VERSION "HINBNNNYYNNNYYNNNNNNNNNNNNYNNNYYYNNYNNNNNN/4//%%/4/'%**4NNN///"

NS_ :

BS_:

BU_: NMTMaster I_O_Device_3 I_O_Device_2 I_O_Device_1 NMT_Master

BO_ 127 RED_IndicateActiveCANLine: 0 Vector__XXX

BO_ 118 FM_ForceReset: 0 Vector__XXX

BO_ 117 FM_ReqMasterCapable: 0 Vector__XXX

BO_ 116 FM_RspMasterCapable: 0 Vector__XXX

BO_ 115 FM_ReqPrioLevel: 0 Vector__XXX

BO_ 114 FM_TriggerTimeSlot: 0 Vector__XXX

BO_ 113 FM_MasterPrioLevel: 2 Vector__XXX
 SG_ FM_NodeID : 8|8@1+ (1,0) [0|0] "" Vector__XXX
 SG_ FM_PrioLevel : 0|8@1+ (1,0) [0|0] "" Vector__XXX

BO_ 1919 HBGuard_127: 1 Vector__XXX
 SG_ Toggle : 7|1@1+ (1,0) [0|0] "" Vector__XXX
 SG_ State : 0|7@1+ (1,0) [0|0] "" Vector__XXX

BO_ 1918 HBGuard_126: 1 Vector__XXX
 SG_ Toggle : 7|1@1+ (1,0) [0|0] "" Vector__XXX
 SG_ State : 0|7@1+ (1,0) [0|0] "" Vector__XXX

BO_ 1917 HBGuard_125: 1 Vector__XXX
 SG_ Toggle : 7|1@1+ (1,0) [0|0] "" Vector__XXX
 SG_ State : 0|7@1+ (1,0) [0|0] "" Vector__XXX

BO_ 1916 HBGuard_124: 1 Vector__XXX
 SG_ Toggle : 7|1@1+ (1,0) [0|0] "" Vector__XXX
 SG_ State : 0|7@1+ (1,0) [0|0] "" Vector__XXX

BO_ 1915 HBGuard_123: 1 Vector__XXX
 SG_ Toggle : 7|1@1+ (1,0) [0|0] "" Vector__XXX
 SG_ State : 0|7@1+ (1,0) [0|0] "" Vector__XXX

BO_ 1914 HBGuard_122: 1 Vector__XXX
 SG_ Toggle : 7|1@1+ (1,0) [0|0] "" Vector__XXX
 SG_ State : 0|7@1+ (1,0) [0|0] "" Vector__XXX

BO_ 1913 HBGuard_121: 1 Vector__XXX
 SG_ Toggle : 7|1@1+ (1,0) [0|0] "" Vector__XXX
 SG_ State : 0|7@1+ (1,0) [0|0] "" Vector__XXX

BO_ 1912 HBGuard_120: 1 Vector__XXX
 SG_ Toggle : 7|1@1+ (1,0) [0|0] "" Vector__XXX
 SG_ State : 0|7@1+ (1,0) [0|0] "" Vector__XXX

BO_ 1911 HBGuard_119: 1 Vector__XXX
 SG_ Toggle : 7|1@1+ (1,0) [0|0] "" Vector__XXX
 SG_ State : 0|7@1+ (1,0) [0|0] "" Vector__XXX

BO_ 1910 HBGuard_118: 1 Vector__XXX
 SG_ Toggle : 7|1@1+ (1,0) [0|0] "" Vector__XXX
 SG_ State : 0|7@1+ (1,0) [0|0] "" Vector__XXX

BO_ 1909 HBGuard_117: 1 Vector__XXX
 SG_ Toggle : 7|1@1+ (1,0) [0|0] "" Vector__XXX
 SG_ State : 0|7@1+ (1,0) [0|0] "" Vector__XXX

BO_ 1908 HBGuard_116: 1 Vector__XXX
 SG_ Toggle : 7|1@1+ (1,0) [0|0] "" Vector__XXX
 SG_ State : 0|7@1+ (1,0) [0|0] "" Vector__XXX

BO_ 1907 HBGuard_115: 1 Vector__XXX
 SG_ Toggle : 7|1@1+ (1,0) [0|0] "" Vector__XXX
 SG_ State : 0|7@1+ (1,0) [0|0] "" Vector__XXX

BO_ 1906 HBGuard_114: 1 Vector__XXX
 SG_ Toggle : 7|1@1+ (1,0) [0|0] "" Vector__XXX
 SG_ State : 0|7@1+ (1,0) [0|0] "" Vector__XXX

BO_ 1905 HBGuard_113: 1 Vector__XXX
 SG_ Toggle : 7|1@1+ (1,0) [0|0] "" Vector__XXX
 SG_ State : 0|7@1+ (1,0) [0|0] "" Vector__XXX

BO_ 1904 HBGuard_112: 1 Vector__XXX
 SG_ Toggle : 7|1@1+ (1,0) [0|0] "" Vector__XXX
 SG_ State : 0|7@1+ (1,0) [0|0] "" Vector__XXX

BO_ 1903 HBGuard_111: 1 Vector__XXX
 SG_ Toggle : 7|1@1+ (1,0) [0|0] "" Vector__XXX
 SG_ State : 0|7@1+ (1,0) [0|0] "" Vector__XXX

BO_ 1902 HBGuard_110: 1 Vector__XXX
 SG_ Toggle : 7|1@1+ (1,0) [0|0] "" Vector__XXX
 SG_ State : 0|7@1+ (1,0) [0|0] "" Vector__XXX

BO_ 1901 HBGuard_109: 1 Vector__XXX
 SG_ Toggle : 7|1@1+ (1,0) [0|0] "" Vector__XXX
 SG_ State : 0|7@1+ (1,0) [0|0] "" Vector__XXX

BO_ 1900 HBGuard_108: 1 Vector__XXX
 SG_ Toggle : 7|1@1+ (1,0) [0|0] "" Vector__XXX
 SG_ State : 0|7@1+ (1,0) [0|0] "" Vector__XXX

BO_ 1899 HBGuard_107: 1 Vector__XXX
 SG_ Toggle : 7|1@1+ (1,0) [0|0] "" Vector__XXX
 SG_ State : 0|7@1+ (1,0) [0|0] "" Vector__XXX

BO_ 1898 HBGuard_106: 1 Vector__XXX
 SG_ Toggle : 7|1@1+ (1,0) [0|0] "" Vector__XXX
 SG_ State : 0|7@1+ (1,0) [0|0] "" Vector__XXX

BO_ 1897 HBGuard_105: 1 Vector__XXX
 SG_ Toggle : 7|1@1+ (1,0) [0|0] "" Vector__XXX
 SG_ State : 0|7@1+ (1,0) [0|0] "" Vector__XXX

BO_ 1896 HBGuard_104: 1 Vector__XXX
 SG_ Toggle : 7|1@1+ (1,0) [0|0] "" Vector__XXX
 SG_ State : 0|7@1+ (1,0) [0|0] "" Vector__XXX

BO_ 1895 HBGuard_103: 1 Vector__XXX
 SG_ Toggle : 7|1@1+ (1,0) [0|0] "" Vector__XXX
 SG_ State : 0|7@1+ (1,0) [0|0] "" Vector__XXX

BO_ 1894 HBGuard_102: 1 Vector__XXX
 SG_ Toggle : 7|1@1+ (1,0) [0|0] "" Vector__XXX
 SG_ State : 0|7@1+ (1,0) [0|0] "" Vector__XXX

BO_ 1893 HBGuard_101: 1 Vector__XXX
 SG_ Toggle : 7|1@1+ (1,0) [0|0] "" Vector__XXX
 SG_ State : 0|7@1+ (1,0) [0|0] "" Vector__XXX

BO_ 1892 HBGuard_100: 1 Vector__XXX
 SG_ Toggle : 7|1@1+ (1,0) [0|0] "" Vector__XXX
 SG_ State : 0|7@1+ (1,0) [0|0] "" Vector__XXX

BO_ 1891 HBGuard_099: 1 Vector__XXX
 SG_ Toggle : 7|1@1+ (1,0) [0|0] "" Vector__XXX
 SG_ State : 0|7@1+ (1,0) [0|0] "" Vector__XXX

BO_ 1890 HBGuard_098: 1 Vector__XXX
 SG_ Toggle : 7|1@1+ (1,0) [0|0] "" Vector__XXX
 SG_ State : 0|7@1+ (1,0) [0|0] "" Vector__XXX

BO_ 1889 HBGuard_097: 1 Vector__XXX
 SG_ Toggle : 7|1@1+ (1,0) [0|0] "" Vector__XXX
 SG_ State : 0|7@1+ (1,0) [0|0] "" Vector__XXX

BO_ 1888 HBGuard_096: 1 Vector__XXX
 SG_ Toggle : 7|1@1+ (1,0) [0|0] "" Vector__XXX
 SG_ State : 0|7@1+ (1,0) [0|0] "" Vector__XXX

BO_ 1887 HBGuard_095: 1 Vector__XXX
 SG_ Toggle : 7|1@1+ (1,0) [0|0] "" Vector__XXX
 SG_ State : 0|7@1+ (1,0) [0|0] "" Vector__XXX

BO_ 1886 HBGuard_094: 1 Vector__XXX
 SG_ Toggle : 7|1@1+ (1,0) [0|0] "" Vector__XXX
 SG_ State : 0|7@1+ (1,0) [0|0] "" Vector__XXX

BO_ 1885 HBGuard_093: 1 Vector__XXX
 SG_ Toggle : 7|1@1+ (1,0) [0|0] "" Vector__XXX
 SG_ State : 0|7@1+ (1,0) [0|0] "" Vector__XXX

BO_ 1884 HBGuard_092: 1 Vector__XXX
 SG_ Toggle : 7|1@1+ (1,0) [0|0] "" Vector__XXX
 SG_ State : 0|7@1+ (1,0) [0|0] "" Vector__XXX

BO_ 1883 HBGuard_091: 1 Vector__XXX
 SG_ Toggle : 7|1@1+ (1,0) [0|0] "" Vector__XXX
 SG_ State : 0|7@1+ (1,0) [0|0] "" Vector__XXX

BO_ 1882 HBGuard_090: 1 Vector__XXX
 SG_ Toggle : 7|1@1+ (1,0) [0|0] "" Vector__XXX
 SG_ State : 0|7@1+ (1,0) [0|0] "" Vector__XXX

BO_ 1881 HBGuard_089: 1 Vector__XXX
 SG_ Toggle : 7|1@1+ (1,0) [0|0] "" Vector__XXX
 SG_ State : 0|7@1+ (1,0) [0|0] "" Vector__XXX

BO_ 1880 HBGuard_088: 1 Vector__XXX
 SG_ Toggle : 7|1@1+ (1,0) [0|0] "" Vector__XXX
 SG_ State : 0|7@1+ (1,0) [0|0] "" Vector__XXX

BO_ 1879 HBGuard_087: 1 Vector__XXX
 SG_ Toggle : 7|1@1+ (1,0) [0|0] "" Vector__XXX
 SG_ State : 0|7@1+ (1,0) [0|0] "" Vector__XXX

BO_ 1878 HBGuard_086: 1 Vector__XXX
 SG_ Toggle : 7|1@1+ (1,0) [0|0] "" Vector__XXX
 SG_ State : 0|7@1+ (1,0) [0|0] "" Vector__XXX

BO_ 1877 HBGuard_085: 1 Vector__XXX
 SG_ Toggle : 7|1@1+ (1,0) [0|0] "" Vector__XXX
 SG_ State : 0|7@1+ (1,0) [0|0] "" Vector__XXX

BO_ 1876 HBGuard_084: 1 Vector__XXX
 SG_ Toggle : 7|1@1+ (1,0) [0|0] "" Vector__XXX
 SG_ State : 0|7@1+ (1,0) [0|0] "" Vector__XXX

BO_ 1875 HBGuard_083: 1 Vector__XXX
 SG_ Toggle : 7|1@1+ (1,0) [0|0] "" Vector__XXX
 SG_ State : 0|7@1+ (1,0) [0|0] "" Vector__XXX

BO_ 1874 HBGuard_082: 1 Vector__XXX
 SG_ Toggle : 7|1@1+ (1,0) [0|0] "" Vector__XXX
 SG_ State : 0|7@1+ (1,0) [0|0] "" Vector__XXX

BO_ 1873 HBGuard_081: 1 Vector__XXX
 SG_ Toggle : 7|1@1+ (1,0) [0|0] "" Vector__XXX
 SG_ State : 0|7@1+ (1,0) [0|0] "" Vector__XXX

BO_ 1872 HBGuard_080: 1 Vector__XXX
 SG_ Toggle : 7|1@1+ (1,0) [0|0] "" Vector__XXX
 SG_ State : 0|7@1+ (1,0) [0|0] "" Vector__XXX

BO_ 1871 HBGuard_079: 1 Vector__XXX
 SG_ Toggle : 7|1@1+ (1,0) [0|0] "" Vector__XXX
 SG_ State : 0|7@1+ (1,0) [0|0] "" Vector__XXX

BO_ 1870 HBGuard_078: 1 Vector__XXX
 SG_ Toggle : 7|1@1+ (1,0) [0|0] "" Vector__XXX
 SG_ State : 0|7@1+ (1,0) [0|0] "" Vector__XXX

BO_ 1869 HBGuard_077: 1 Vector__XXX
 SG_ Toggle : 7|1@1+ (1,0) [0|0] "" Vector__XXX
 SG_ State : 0|7@1+ (1,0) [0|0] "" Vector__XXX

BO_ 1868 HBGuard_076: 1 Vector__XXX
 SG_ Toggle : 7|1@1+ (1,0) [0|0] "" Vector__XXX
 SG_ State : 0|7@1+ (1,0) [0|0] "" Vector__XXX

BO_ 1867 HBGuard_075: 1 Vector__XXX
 SG_ Toggle : 7|1@1+ (1,0) [0|0] "" Vector__XXX
 SG_ State : 0|7@1+ (1,0) [0|0] "" Vector__XXX

BO_ 1866 HBGuard_074: 1 Vector__XXX
 SG_ Toggle : 7|1@1+ (1,0) [0|0] "" Vector__XXX
 SG_ State : 0|7@1+ (1,0) [0|0] "" Vector__XXX

BO_ 1865 HBGuard_073: 1 Vector__XXX
 SG_ Toggle : 7|1@1+ (1,0) [0|0] "" Vector__XXX
 SG_ State : 0|7@1+ (1,0) [0|0] "" Vector__XXX

BO_ 1864 HBGuard_072: 1 Vector__XXX
 SG_ Toggle : 7|1@1+ (1,0) [0|0] "" Vector__XXX
 SG_ State : 0|7@1+ (1,0) [0|0] "" Vector__XXX

BO_ 1863 HBGuard_071: 1 Vector__XXX
 SG_ Toggle : 7|1@1+ (1,0) [0|0] "" Vector__XXX
 SG_ State : 0|7@1+ (1,0) [0|0] "" Vector__XXX

BO_ 1862 HBGuard_070: 1 Vector__XXX
 SG_ Toggle : 7|1@1+ (1,0) [0|0] "" Vector__XXX
 SG_ State : 0|7@1+ (1,0) [0|0] "" Vector__XXX

BO_ 1861 HBGuard_069: 1 Vector__XXX
 SG_ Toggle : 7|1@1+ (1,0) [0|0] "" Vector__XXX
 SG_ State : 0|7@1+ (1,0) [0|0] "" Vector__XXX

BO_ 1860 HBGuard_068: 1 Vector__XXX
 SG_ Toggle : 7|1@1+ (1,0) [0|0] "" Vector__XXX
 SG_ State : 0|7@1+ (1,0) [0|0] "" Vector__XXX

BO_ 1859 HBGuard_067: 1 Vector__XXX
 SG_ Toggle : 7|1@1+ (1,0) [0|0] "" Vector__XXX
 SG_ State : 0|7@1+ (1,0) [0|0] "" Vector__XXX

BO_ 1858 HBGuard_066: 1 Vector__XXX
 SG_ Toggle : 7|1@1+ (1,0) [0|0] "" Vector__XXX
 SG_ State : 0|7@1+ (1,0) [0|0] "" Vector__XXX

BO_ 1857 HBGuard_065: 1 Vector__XXX
 SG_ Toggle : 7|1@1+ (1,0) [0|0] "" Vector__XXX
 SG_ State : 0|7@1+ (1,0) [0|0] "" Vector__XXX

BO_ 1856 HBGuard_064: 1 Vector__XXX
 SG_ Toggle : 7|1@1+ (1,0) [0|0] "" Vector__XXX
 SG_ State : 0|7@1+ (1,0) [0|0] "" Vector__XXX

BO_ 1855 HBGuard_063: 1 Vector__XXX
 SG_ Toggle : 7|1@1+ (1,0) [0|0] "" Vector__XXX
 SG_ State : 0|7@1+ (1,0) [0|0] "" Vector__XXX

BO_ 1854 HBGuard_062: 1 Vector__XXX
 SG_ Toggle : 7|1@1+ (1,0) [0|0] "" Vector__XXX
 SG_ State : 0|7@1+ (1,0) [0|0] "" Vector__XXX

BO_ 1853 HBGuard_061: 1 Vector__XXX
 SG_ Toggle : 7|1@1+ (1,0) [0|0] "" Vector__XXX
 SG_ State : 0|7@1+ (1,0) [0|0] "" Vector__XXX

BO_ 1852 HBGuard_060: 1 Vector__XXX
 SG_ Toggle : 7|1@1+ (1,0) [0|0] "" Vector__XXX
 SG_ State : 0|7@1+ (1,0) [0|0] "" Vector__XXX

BO_ 1851 HBGuard_059: 1 Vector__XXX
 SG_ Toggle : 7|1@1+ (1,0) [0|0] "" Vector__XXX
 SG_ State : 0|7@1+ (1,0) [0|0] "" Vector__XXX

BO_ 1850 HBGuard_058: 1 Vector__XXX
 SG_ Toggle : 7|1@1+ (1,0) [0|0] "" Vector__XXX
 SG_ State : 0|7@1+ (1,0) [0|0] "" Vector__XXX

BO_ 1849 HBGuard_057: 1 Vector__XXX
 SG_ Toggle : 7|1@1+ (1,0) [0|0] "" Vector__XXX
 SG_ State : 0|7@1+ (1,0) [0|0] "" Vector__XXX

BO_ 1848 HBGuard_056: 1 Vector__XXX
 SG_ Toggle : 7|1@1+ (1,0) [0|0] "" Vector__XXX
 SG_ State : 0|7@1+ (1,0) [0|0] "" Vector__XXX

BO_ 1847 HBGuard_055: 1 Vector__XXX
 SG_ Toggle : 7|1@1+ (1,0) [0|0] "" Vector__XXX
 SG_ State : 0|7@1+ (1,0) [0|0] "" Vector__XXX

BO_ 1846 HBGuard_054: 1 Vector__XXX
 SG_ Toggle : 7|1@1+ (1,0) [0|0] "" Vector__XXX
 SG_ State : 0|7@1+ (1,0) [0|0] "" Vector__XXX

BO_ 1845 HBGuard_053: 1 Vector__XXX
 SG_ Toggle : 7|1@1+ (1,0) [0|0] "" Vector__XXX
 SG_ State : 0|7@1+ (1,0) [0|0] "" Vector__XXX

BO_ 1844 HBGuard_052: 1 Vector__XXX
 SG_ Toggle : 7|1@1+ (1,0) [0|0] "" Vector__XXX
 SG_ State : 0|7@1+ (1,0) [0|0] "" Vector__XXX

BO_ 1843 HBGuard_051: 1 Vector__XXX
 SG_ Toggle : 7|1@1+ (1,0) [0|0] "" Vector__XXX
 SG_ State : 0|7@1+ (1,0) [0|0] "" Vector__XXX

BO_ 1842 HBGuard_050: 1 Vector__XXX
 SG_ Toggle : 7|1@1+ (1,0) [0|0] "" Vector__XXX
 SG_ State : 0|7@1+ (1,0) [0|0] "" Vector__XXX

BO_ 1841 HBGuard_049: 1 Vector__XXX
 SG_ Toggle : 7|1@1+ (1,0) [0|0] "" Vector__XXX
 SG_ State : 0|7@1+ (1,0) [0|0] "" Vector__XXX

BO_ 1840 HBGuard_048: 1 Vector__XXX
 SG_ Toggle : 7|1@1+ (1,0) [0|0] "" Vector__XXX
 SG_ State : 0|7@1+ (1,0) [0|0] "" Vector__XXX

BO_ 1839 HBGuard_047: 1 Vector__XXX
 SG_ Toggle : 7|1@1+ (1,0) [0|0] "" Vector__XXX
 SG_ State : 0|7@1+ (1,0) [0|0] "" Vector__XXX

BO_ 1838 HBGuard_046: 1 Vector__XXX
 SG_ Toggle : 7|1@1+ (1,0) [0|0] "" Vector__XXX
 SG_ State : 0|7@1+ (1,0) [0|0] "" Vector__XXX

BO_ 1837 HBGuard_045: 1 Vector__XXX
 SG_ Toggle : 7|1@1+ (1,0) [0|0] "" Vector__XXX
 SG_ State : 0|7@1+ (1,0) [0|0] "" Vector__XXX

BO_ 1836 HBGuard_044: 1 Vector__XXX
 SG_ Toggle : 7|1@1+ (1,0) [0|0] "" Vector__XXX
 SG_ State : 0|7@1+ (1,0) [0|0] "" Vector__XXX

BO_ 1835 HBGuard_043: 1 Vector__XXX
 SG_ Toggle : 7|1@1+ (1,0) [0|0] "" Vector__XXX
 SG_ State : 0|7@1+ (1,0) [0|0] "" Vector__XXX

BO_ 1834 HBGuard_042: 1 Vector__XXX
 SG_ Toggle : 7|1@1+ (1,0) [0|0] "" Vector__XXX
 SG_ State : 0|7@1+ (1,0) [0|0] "" Vector__XXX

BO_ 1833 HBGuard_041: 1 Vector__XXX
 SG_ Toggle : 7|1@1+ (1,0) [0|0] "" Vector__XXX
 SG_ State : 0|7@1+ (1,0) [0|0] "" Vector__XXX

BO_ 1832 HBGuard_040: 1 Vector__XXX
 SG_ Toggle : 7|1@1+ (1,0) [0|0] "" Vector__XXX
 SG_ State : 0|7@1+ (1,0) [0|0] "" Vector__XXX

BO_ 1831 HBGuard_039: 1 Vector__XXX
 SG_ Toggle : 7|1@1+ (1,0) [0|0] "" Vector__XXX
 SG_ State : 0|7@1+ (1,0) [0|0] "" Vector__XXX

BO_ 1830 HBGuard_038: 1 Vector__XXX
 SG_ Toggle : 7|1@1+ (1,0) [0|0] "" Vector__XXX
 SG_ State : 0|7@1+ (1,0) [0|0] "" Vector__XXX

BO_ 1829 HBGuard_037: 1 Vector__XXX
 SG_ Toggle : 7|1@1+ (1,0) [0|0] "" Vector__XXX
 SG_ State : 0|7@1+ (1,0) [0|0] "" Vector__XXX

BO_ 1828 HBGuard_036: 1 Vector__XXX
 SG_ Toggle : 7|1@1+ (1,0) [0|0] "" Vector__XXX
 SG_ State : 0|7@1+ (1,0) [0|0] "" Vector__XXX

BO_ 1827 HBGuard_035: 1 Vector__XXX
 SG_ Toggle : 7|1@1+ (1,0) [0|0] "" Vector__XXX
 SG_ State : 0|7@1+ (1,0) [0|0] "" Vector__XXX

BO_ 1826 HBGuard_034: 1 Vector__XXX
 SG_ Toggle : 7|1@1+ (1,0) [0|0] "" Vector__XXX
 SG_ State : 0|7@1+ (1,0) [0|0] "" Vector__XXX

BO_ 1825 HBGuard_033: 1 Vector__XXX
 SG_ Toggle : 7|1@1+ (1,0) [0|0] "" Vector__XXX
 SG_ State : 0|7@1+ (1,0) [0|0] "" Vector__XXX

BO_ 1824 HBGuard_032: 1 Vector__XXX
 SG_ Toggle : 7|1@1+ (1,0) [0|0] "" Vector__XXX
 SG_ State : 0|7@1+ (1,0) [0|0] "" Vector__XXX

BO_ 1823 HBGuard_031: 1 Vector__XXX
 SG_ Toggle : 7|1@1+ (1,0) [0|0] "" Vector__XXX
 SG_ State : 0|7@1+ (1,0) [0|0] "" Vector__XXX

BO_ 1822 HBGuard_030: 1 Vector__XXX
 SG_ Toggle : 7|1@1+ (1,0) [0|0] "" Vector__XXX
 SG_ State : 0|7@1+ (1,0) [0|0] "" Vector__XXX

BO_ 1821 HBGuard_029: 1 Vector__XXX
 SG_ Toggle : 7|1@1+ (1,0) [0|0] "" Vector__XXX
 SG_ State : 0|7@1+ (1,0) [0|0] "" Vector__XXX

BO_ 1820 HBGuard_028: 1 Vector__XXX
 SG_ Toggle : 7|1@1+ (1,0) [0|0] "" Vector__XXX
 SG_ State : 0|7@1+ (1,0) [0|0] "" Vector__XXX

BO_ 1819 HBGuard_027: 1 Vector__XXX
 SG_ Toggle : 7|1@1+ (1,0) [0|0] "" Vector__XXX
 SG_ State : 0|7@1+ (1,0) [0|0] "" Vector__XXX

BO_ 1818 HBGuard_026: 1 Vector__XXX
 SG_ Toggle : 7|1@1+ (1,0) [0|0] "" Vector__XXX
 SG_ State : 0|7@1+ (1,0) [0|0] "" Vector__XXX

BO_ 1817 HBGuard_025: 1 Vector__XXX
 SG_ Toggle : 7|1@1+ (1,0) [0|0] "" Vector__XXX
 SG_ State : 0|7@1+ (1,0) [0|0] "" Vector__XXX

BO_ 1816 HBGuard_024: 1 Vector__XXX
 SG_ Toggle : 7|1@1+ (1,0) [0|0] "" Vector__XXX
 SG_ State : 0|7@1+ (1,0) [0|0] "" Vector__XXX

BO_ 1815 HBGuard_023: 1 Vector__XXX
 SG_ Toggle : 7|1@1+ (1,0) [0|0] "" Vector__XXX
 SG_ State : 0|7@1+ (1,0) [0|0] "" Vector__XXX

BO_ 1814 HBGuard_022: 1 Vector__XXX
 SG_ Toggle : 7|1@1+ (1,0) [0|0] "" Vector__XXX
 SG_ State : 0|7@1+ (1,0) [0|0] "" Vector__XXX

BO_ 1813 HBGuard_021: 1 Vector__XXX
 SG_ Toggle : 7|1@1+ (1,0) [0|0] "" Vector__XXX
 SG_ State : 0|7@1+ (1,0) [0|0] "" Vector__XXX

BO_ 1812 HBGuard_020: 1 Vector__XXX
 SG_ Toggle : 7|1@1+ (1,0) [0|0] "" Vector__XXX
 SG_ State : 0|7@1+ (1,0) [0|0] "" Vector__XXX

BO_ 1811 HBGuard_019: 1 Vector__XXX
 SG_ Toggle : 7|1@1+ (1,0) [0|0] "" Vector__XXX
 SG_ State : 0|7@1+ (1,0) [0|0] "" Vector__XXX

BO_ 1810 HBGuard_018: 1 Vector__XXX
 SG_ Toggle : 7|1@1+ (1,0) [0|0] "" Vector__XXX
 SG_ State : 0|7@1+ (1,0) [0|0] "" Vector__XXX

BO_ 1809 HBGuard_017: 1 Vector__XXX
 SG_ Toggle : 7|1@1+ (1,0) [0|0] "" Vector__XXX
 SG_ State : 0|7@1+ (1,0) [0|0] "" Vector__XXX

BO_ 1808 HBGuard_016: 1 Vector__XXX
 SG_ Toggle : 7|1@1+ (1,0) [0|0] "" Vector__XXX
 SG_ State : 0|7@1+ (1,0) [0|0] "" Vector__XXX

BO_ 1807 HBGuard_015: 1 Vector__XXX
 SG_ Toggle : 7|1@1+ (1,0) [0|0] "" Vector__XXX
 SG_ State : 0|7@1+ (1,0) [0|0] "" Vector__XXX

BO_ 1806 HBGuard_014: 1 Vector__XXX
 SG_ Toggle : 7|1@1+ (1,0) [0|0] "" Vector__XXX
 SG_ State : 0|7@1+ (1,0) [0|0] "" Vector__XXX

BO_ 1805 HBGuard_013: 1 I_O_Device_3
 SG_ Toggle : 7|1@1+ (1,0) [0|0] "" Vector__XXX
 SG_ State : 0|7@1+ (1,0) [0|0] "" Vector__XXX

BO_ 1804 HBGuard_012: 1 I_O_Device_2
 SG_ Toggle : 7|1@1+ (1,0) [0|0] "" Vector__XXX
 SG_ State : 0|7@1+ (1,0) [0|0] "" Vector__XXX

BO_ 1803 HBGuard_011: 1 I_O_Device_1
 SG_ Toggle : 7|1@1+ (1,0) [0|0] "" Vector__XXX
 SG_ State : 0|7@1+ (1,0) [0|0] "" Vector__XXX

BO_ 1802 HBGuard_010: 1 Vector__XXX
 SG_ Toggle : 7|1@1+ (1,0) [0|0] "" Vector__XXX
 SG_ State : 0|7@1+ (1,0) [0|0] "" Vector__XXX

BO_ 1801 HBGuard_009: 1 Vector__XXX
 SG_ Toggle : 7|1@1+ (1,0) [0|0] "" Vector__XXX
 SG_ State : 0|7@1+ (1,0) [0|0] "" Vector__XXX

BO_ 1800 HBGuard_008: 1 Vector__XXX
 SG_ Toggle : 7|1@1+ (1,0) [0|0] "" Vector__XXX
 SG_ State : 0|7@1+ (1,0) [0|0] "" Vector__XXX

BO_ 1799 HBGuard_007: 1 Vector__XXX
 SG_ Toggle : 7|1@1+ (1,0) [0|0] "" Vector__XXX
 SG_ State : 0|7@1+ (1,0) [0|0] "" Vector__XXX

BO_ 1798 HBGuard_006: 1 Vector__XXX
 SG_ Toggle : 7|1@1+ (1,0) [0|0] "" Vector__XXX
 SG_ State : 0|7@1+ (1,0) [0|0] "" Vector__XXX

BO_ 1797 HBGuard_005: 1 Vector__XXX
 SG_ Toggle : 7|1@1+ (1,0) [0|0] "" Vector__XXX
 SG_ State : 0|7@1+ (1,0) [0|0] "" Vector__XXX

BO_ 1796 HBGuard_004: 1 Vector__XXX
 SG_ Toggle : 7|1@1+ (1,0) [0|0] "" Vector__XXX
 SG_ State : 0|7@1+ (1,0) [0|0] "" Vector__XXX

BO_ 1795 HBGuard_003: 1 Vector__XXX
 SG_ Toggle : 7|1@1+ (1,0) [0|0] "" Vector__XXX
 SG_ State : 0|7@1+ (1,0) [0|0] "" Vector__XXX

BO_ 1794 HBGuard_002: 1 Vector__XXX
 SG_ Toggle : 7|1@1+ (1,0) [0|0] "" Vector__XXX
 SG_ State : 0|7@1+ (1,0) [0|0] "" Vector__XXX

BO_ 1793 HBGuard_001: 1 NMT_Master
 SG_ Toggle : 7|1@1+ (1,0) [0|0] "" Vector__XXX
 SG_ State : 0|7@1+ (1,0) [0|0] "" Vector__XXX

BO_ 1760 DynSDOReq: 0 Vector__XXX

BO_ 2021 LSS_M: 8 Vector__XXX
 SG_ LSS_IdentSerialHigh m75 : 8|32@1+ (1,0) [0|0] "" Vector__XXX
 SG_ LSS_IdentSerialLow m74 : 8|32@1+ (1,0) [0|0] "" Vector__XXX
 SG_ LSS_IdentRevisionHigh m73 : 8|32@1+ (1,0) [0|0] "" Vector__XXX
 SG_ LSS_IdentRevisionLow m72 : 8|32@1+ (1,0) [0|0] "" Vector__XXX
 SG_ LSS_IdentProductCode m71 : 8|32@1+ (1,0) [0|0] "" Vector__XXX
 SG_ LSS_IdentVendorId m70 : 8|32@1+ (1,0) [0|0] "" Vector__XXX
 SG_ LSS_TableIndex m19 : 16|8@1+ (1,0) [0|0] "" Vector__XXX
 SG_ LSS_TableSelector m19 : 8|8@1+ (1,0) [0|0] "" Vector__XXX
 SG_ LSS_SwitchSerial m67 : 8|32@1+ (1,0) [0|0] "" Vector__XXX
 SG_ LSS_SwitchRevision m66 : 8|32@1+ (1,0) [0|0] "" Vector__XXX
 SG_ LSS_SwitchProductCode m65 : 8|32@1+ (1,0) [0|0] "" Vector__XXX
 SG_ LSS_SwitchVendorId m64 : 8|32@1+ (1,0) [0|0] "" Vector__XXX
 SG_ LSS_Mode m4 : 8|8@1+ (1,0) [0|0] "" Vector__XXX
 SG_ LSS_M_CS M : 0|8@1+ (1,0) [0|0] "" Vector__XXX

BO_ 2020 LSS_S: 8 Vector__XXX
 SG_ LSS_NodeId m94 : 8|8@1+ (1,0) [0|0] "" Vector__XXX
 SG_ LSS_Serial m93 : 8|32@1+ (1,0) [0|0] "" Vector__XXX
 SG_ LSS_Revision m92 : 8|32@1+ (1,0) [0|0] "" Vector__XXX
 SG_ LSS_ProductId m91 : 8|32@1+ (1,0) [0|0] "" Vector__XXX
 SG_ LSS_VendorId m90 : 8|32@1+ (1,0) [0|0] "" Vector__XXX
 SG_ LSS_StoreCfg_SpecErr m23 : 16|8@1+ (1,0) [0|0] "" Vector__XXX
 SG_ LSS_StoreCfg_ErrCode m23 : 8|8@1+ (1,0) [0|0] "" Vector__XXX
 SG_ LSS_CfgBitTim_SpecErr m19 : 16|8@1+ (1,0) [0|0] "" Vector__XXX
 SG_ LSS_CfgBitTim_ErrCode m19 : 8|8@1+ (1,0) [0|0] "" Vector__XXX
 SG_ LSS_CfgNodeID_SpecErr m17 : 16|8@1+ (1,0) [0|0] "" Vector__XXX
 SG_ LSS_CfgNodeID_ErrCode m17 : 8|8@1+ (1,0) [0|0] "" Vector__XXX
 SG_ LSS_S_CS M : 0|8@1+ (1,0) [0|0] "" Vector__XXX

BO_ 1 GFC: 0 Vector__XXX

BO_ 1535 SSDO_127: 8 Vector__XXX

BO_ 1534 SSDO_126: 8 Vector__XXX

BO_ 1533 SSDO_125: 8 Vector__XXX

BO_ 1532 SSDO_124: 8 Vector__XXX

BO_ 1531 SSDO_123: 8 Vector__XXX

BO_ 1530 SSDO_122: 8 Vector__XXX

BO_ 1529 SSDO_121: 8 Vector__XXX

BO_ 1528 SSDO_120: 8 Vector__XXX

BO_ 1527 SSDO_119: 8 Vector__XXX

BO_ 1526 SSDO_118: 8 Vector__XXX

BO_ 1525 SSDO_117: 8 Vector__XXX

BO_ 1524 SSDO_116: 8 Vector__XXX

BO_ 1523 SSDO_115: 8 Vector__XXX

BO_ 1522 SSDO_114: 8 Vector__XXX

BO_ 1521 SSDO_113: 8 Vector__XXX

BO_ 1520 SSDO_112: 8 Vector__XXX

BO_ 1519 SSDO_111: 8 Vector__XXX

BO_ 1518 SSDO_110: 8 Vector__XXX

BO_ 1517 SSDO_109: 8 Vector__XXX

BO_ 1516 SSDO_108: 8 Vector__XXX

BO_ 1515 SSDO_107: 8 Vector__XXX

BO_ 1514 SSDO_106: 8 Vector__XXX

BO_ 1513 SSDO_105: 8 Vector__XXX

BO_ 1512 SSDO_104: 8 Vector__XXX

BO_ 1511 SSDO_103: 8 Vector__XXX

BO_ 1510 SSDO_102: 8 Vector__XXX

BO_ 1509 SSDO_101: 8 Vector__XXX

BO_ 1508 SSDO_100: 8 Vector__XXX

BO_ 1507 SSDO_099: 8 Vector__XXX

BO_ 1506 SSDO_098: 8 Vector__XXX

BO_ 1505 SSDO_097: 8 Vector__XXX

BO_ 1504 SSDO_096: 8 Vector__XXX

BO_ 1503 SSDO_095: 8 Vector__XXX

BO_ 1502 SSDO_094: 8 Vector__XXX

BO_ 1501 SSDO_093: 8 Vector__XXX

BO_ 1500 SSDO_092: 8 Vector__XXX

BO_ 1499 SSDO_091: 8 Vector__XXX

BO_ 1498 SSDO_090: 8 Vector__XXX

BO_ 1497 SSDO_089: 8 Vector__XXX

BO_ 1496 SSDO_088: 8 Vector__XXX

BO_ 1495 SSDO_087: 8 Vector__XXX

BO_ 1494 SSDO_086: 8 Vector__XXX

BO_ 1493 SSDO_085: 8 Vector__XXX

BO_ 1492 SSDO_084: 8 Vector__XXX

BO_ 1491 SSDO_083: 8 Vector__XXX

BO_ 1490 SSDO_082: 8 Vector__XXX

BO_ 1489 SSDO_081: 8 Vector__XXX

BO_ 1488 SSDO_080: 8 Vector__XXX

BO_ 1487 SSDO_079: 8 Vector__XXX

BO_ 1486 SSDO_078: 8 Vector__XXX

BO_ 1485 SSDO_077: 8 Vector__XXX

BO_ 1484 SSDO_076: 8 Vector__XXX

BO_ 1483 SSDO_075: 8 Vector__XXX

BO_ 1482 SSDO_074: 8 Vector__XXX

BO_ 1481 SSDO_073: 8 Vector__XXX

BO_ 1480 SSDO_072: 8 Vector__XXX

BO_ 1479 SSDO_071: 8 Vector__XXX

BO_ 1478 SSDO_070: 8 Vector__XXX

BO_ 1477 SSDO_069: 8 Vector__XXX

BO_ 1476 SSDO_068: 8 Vector__XXX

BO_ 1475 SSDO_067: 8 Vector__XXX

BO_ 1474 SSDO_066: 8 Vector__XXX

BO_ 1473 SSDO_065: 8 Vector__XXX

BO_ 1472 SSDO_064: 8 Vector__XXX

BO_ 1471 SSDO_063: 8 Vector__XXX

BO_ 1470 SSDO_062: 8 Vector__XXX

BO_ 1469 SSDO_061: 8 Vector__XXX

BO_ 1468 SSDO_060: 8 Vector__XXX

BO_ 1467 SSDO_059: 8 Vector__XXX

BO_ 1466 SSDO_058: 8 Vector__XXX

BO_ 1465 SSDO_057: 8 Vector__XXX

BO_ 1464 SSDO_056: 8 Vector__XXX

BO_ 1463 SSDO_055: 8 Vector__XXX

BO_ 1462 SSDO_054: 8 Vector__XXX

BO_ 1461 SSDO_053: 8 Vector__XXX

BO_ 1460 SSDO_052: 8 Vector__XXX

BO_ 1459 SSDO_051: 8 Vector__XXX

BO_ 1458 SSDO_050: 8 Vector__XXX

BO_ 1457 SSDO_049: 8 Vector__XXX

BO_ 1456 SSDO_048: 8 Vector__XXX

BO_ 1455 SSDO_047: 8 Vector__XXX

BO_ 1454 SSDO_046: 8 Vector__XXX

BO_ 1453 SSDO_045: 8 Vector__XXX

BO_ 1452 SSDO_044: 8 Vector__XXX

BO_ 1451 SSDO_043: 8 Vector__XXX

BO_ 1450 SSDO_042: 8 Vector__XXX

BO_ 1449 SSDO_041: 8 Vector__XXX

BO_ 1448 SSDO_040: 8 Vector__XXX

BO_ 1447 SSDO_039: 8 Vector__XXX

BO_ 1446 SSDO_038: 8 Vector__XXX

BO_ 1445 SSDO_037: 8 Vector__XXX

BO_ 1444 SSDO_036: 8 Vector__XXX

BO_ 1443 SSDO_035: 8 Vector__XXX

BO_ 1442 SSDO_034: 8 Vector__XXX

BO_ 1441 SSDO_033: 8 Vector__XXX

BO_ 1440 SSDO_032: 8 Vector__XXX

BO_ 1439 SSDO_031: 8 Vector__XXX

BO_ 1438 SSDO_030: 8 Vector__XXX

BO_ 1437 SSDO_029: 8 Vector__XXX

BO_ 1436 SSDO_028: 8 Vector__XXX

BO_ 1435 SSDO_027: 8 Vector__XXX

BO_ 1434 SSDO_026: 8 Vector__XXX

BO_ 1433 SSDO_025: 8 Vector__XXX

BO_ 1432 SSDO_024: 8 Vector__XXX

BO_ 1431 SSDO_023: 8 Vector__XXX

BO_ 1430 SSDO_022: 8 Vector__XXX

BO_ 1429 SSDO_021: 8 Vector__XXX

BO_ 1428 SSDO_020: 8 Vector__XXX

BO_ 1427 SSDO_019: 8 Vector__XXX

BO_ 1426 SSDO_018: 8 Vector__XXX

BO_ 1425 SSDO_017: 8 Vector__XXX

BO_ 1424 SSDO_016: 8 Vector__XXX

BO_ 1423 SSDO_015: 8 Vector__XXX

BO_ 1422 SSDO_014: 8 Vector__XXX

BO_ 1421 SSDO_013: 8 I_O_Device_3

BO_ 1420 SSDO_012: 8 I_O_Device_2

BO_ 1419 SSDO_011: 8 I_O_Device_1

BO_ 1418 SSDO_010: 8 Vector__XXX

BO_ 1417 SSDO_009: 8 Vector__XXX

BO_ 1416 SSDO_008: 8 Vector__XXX

BO_ 1415 SSDO_007: 8 Vector__XXX

BO_ 1414 SSDO_006: 8 Vector__XXX

BO_ 1413 SSDO_005: 8 Vector__XXX

BO_ 1412 SSDO_004: 8 Vector__XXX

BO_ 1411 SSDO_003: 8 Vector__XXX

BO_ 1410 SSDO_002: 8 Vector__XXX

BO_ 1409 SSDO_001: 8 NMT_Master

BO_ 1663 CSDO_127: 8 Vector__XXX

BO_ 1662 CSDO_126: 8 Vector__XXX

BO_ 1661 CSDO_125: 8 Vector__XXX

BO_ 1660 CSDO_124: 8 Vector__XXX

BO_ 1659 CSDO_123: 8 Vector__XXX

BO_ 1658 CSDO_122: 8 Vector__XXX

BO_ 1657 CSDO_121: 8 Vector__XXX

BO_ 1656 CSDO_120: 8 Vector__XXX

BO_ 1655 CSDO_119: 8 Vector__XXX

BO_ 1654 CSDO_118: 8 Vector__XXX

BO_ 1653 CSDO_117: 8 Vector__XXX

BO_ 1652 CSDO_116: 8 Vector__XXX

BO_ 1651 CSDO_115: 8 Vector__XXX

BO_ 1650 CSDO_114: 8 Vector__XXX

BO_ 1649 CSDO_113: 8 Vector__XXX

BO_ 1648 CSDO_112: 8 Vector__XXX

BO_ 1647 CSDO_111: 8 Vector__XXX

BO_ 1646 CSDO_110: 8 Vector__XXX

BO_ 1645 CSDO_109: 8 Vector__XXX

BO_ 1644 CSDO_108: 8 Vector__XXX

BO_ 1643 CSDO_107: 8 Vector__XXX

BO_ 1642 CSDO_106: 8 Vector__XXX

BO_ 1641 CSDO_105: 8 Vector__XXX

BO_ 1640 CSDO_104: 8 Vector__XXX

BO_ 1639 CSDO_103: 8 Vector__XXX

BO_ 1638 CSDO_102: 8 Vector__XXX

BO_ 1637 CSDO_101: 8 Vector__XXX

BO_ 1636 CSDO_100: 8 Vector__XXX

BO_ 1635 CSDO_099: 8 Vector__XXX

BO_ 1634 CSDO_098: 8 Vector__XXX

BO_ 1633 CSDO_097: 8 Vector__XXX

BO_ 1632 CSDO_096: 8 Vector__XXX

BO_ 1631 CSDO_095: 8 Vector__XXX

BO_ 1630 CSDO_094: 8 Vector__XXX

BO_ 1629 CSDO_093: 8 Vector__XXX

BO_ 1628 CSDO_092: 8 Vector__XXX

BO_ 1627 CSDO_091: 8 Vector__XXX

BO_ 1626 CSDO_090: 8 Vector__XXX

BO_ 1625 CSDO_089: 8 Vector__XXX

BO_ 1624 CSDO_088: 8 Vector__XXX

BO_ 1623 CSDO_087: 8 Vector__XXX

BO_ 1622 CSDO_086: 8 Vector__XXX

BO_ 1621 CSDO_085: 8 Vector__XXX

BO_ 1620 CSDO_084: 8 Vector__XXX

BO_ 1619 CSDO_083: 8 Vector__XXX

BO_ 1618 CSDO_082: 8 Vector__XXX

BO_ 1617 CSDO_081: 8 Vector__XXX

BO_ 1616 CSDO_080: 8 Vector__XXX

BO_ 1615 CSDO_079: 8 Vector__XXX

BO_ 1614 CSDO_078: 8 Vector__XXX

BO_ 1613 CSDO_077: 8 Vector__XXX

BO_ 1612 CSDO_076: 8 Vector__XXX

BO_ 1611 CSDO_075: 8 Vector__XXX

BO_ 1610 CSDO_074: 8 Vector__XXX

BO_ 1609 CSDO_073: 8 Vector__XXX

BO_ 1608 CSDO_072: 8 Vector__XXX

BO_ 1607 CSDO_071: 8 Vector__XXX

BO_ 1606 CSDO_070: 8 Vector__XXX

BO_ 1605 CSDO_069: 8 Vector__XXX

BO_ 1604 CSDO_068: 8 Vector__XXX

BO_ 1603 CSDO_067: 8 Vector__XXX

BO_ 1602 CSDO_066: 8 Vector__XXX

BO_ 1601 CSDO_065: 8 Vector__XXX

BO_ 1600 CSDO_064: 8 Vector__XXX

BO_ 1599 CSDO_063: 8 Vector__XXX

BO_ 1598 CSDO_062: 8 Vector__XXX

BO_ 1597 CSDO_061: 8 Vector__XXX

BO_ 1596 CSDO_060: 8 Vector__XXX

BO_ 1595 CSDO_059: 8 Vector__XXX

BO_ 1594 CSDO_058: 8 Vector__XXX

BO_ 1593 CSDO_057: 8 Vector__XXX

BO_ 1592 CSDO_056: 8 Vector__XXX

BO_ 1591 CSDO_055: 8 Vector__XXX

BO_ 1590 CSDO_054: 8 Vector__XXX

BO_ 1589 CSDO_053: 8 Vector__XXX

BO_ 1588 CSDO_052: 8 Vector__XXX

BO_ 1587 CSDO_051: 8 Vector__XXX

BO_ 1586 CSDO_050: 8 Vector__XXX

BO_ 1585 CSDO_049: 8 Vector__XXX

BO_ 1584 CSDO_048: 8 Vector__XXX

BO_ 1583 CSDO_047: 8 Vector__XXX

BO_ 1582 CSDO_046: 8 Vector__XXX

BO_ 1581 CSDO_045: 8 Vector__XXX

BO_ 1580 CSDO_044: 8 Vector__XXX

BO_ 1579 CSDO_043: 8 Vector__XXX

BO_ 1578 CSDO_042: 8 Vector__XXX

BO_ 1577 CSDO_041: 8 Vector__XXX

BO_ 1576 CSDO_040: 8 Vector__XXX

BO_ 1575 CSDO_039: 8 Vector__XXX

BO_ 1574 CSDO_038: 8 Vector__XXX

BO_ 1573 CSDO_037: 8 Vector__XXX

BO_ 1572 CSDO_036: 8 Vector__XXX

BO_ 1571 CSDO_035: 8 Vector__XXX

BO_ 1570 CSDO_034: 8 Vector__XXX

BO_ 1569 CSDO_033: 8 Vector__XXX

BO_ 1568 CSDO_032: 8 Vector__XXX

BO_ 1567 CSDO_031: 8 Vector__XXX

BO_ 1566 CSDO_030: 8 Vector__XXX

BO_ 1565 CSDO_029: 8 Vector__XXX

BO_ 1564 CSDO_028: 8 Vector__XXX

BO_ 1563 CSDO_027: 8 Vector__XXX

BO_ 1562 CSDO_026: 8 Vector__XXX

BO_ 1561 CSDO_025: 8 Vector__XXX

BO_ 1560 CSDO_024: 8 Vector__XXX

BO_ 1559 CSDO_023: 8 Vector__XXX

BO_ 1558 CSDO_022: 8 Vector__XXX

BO_ 1557 CSDO_021: 8 Vector__XXX

BO_ 1556 CSDO_020: 8 Vector__XXX

BO_ 1555 CSDO_019: 8 Vector__XXX

BO_ 1554 CSDO_018: 8 Vector__XXX

BO_ 1553 CSDO_017: 8 Vector__XXX

BO_ 1552 CSDO_016: 8 Vector__XXX

BO_ 1551 CSDO_015: 8 Vector__XXX

BO_ 1550 CSDO_014: 8 Vector__XXX

BO_ 1549 CSDO_013: 8 Vector__XXX
 SG_ CSDO_013_CS M : 0|8@1+ (1,0) [0|0] ""  I_O_Device_3

BO_ 1548 CSDO_012: 8 Vector__XXX
 SG_ CSDO_012_CS M : 0|8@1+ (1,0) [0|0] ""  I_O_Device_2

BO_ 1547 CSDO_011: 8 Vector__XXX
 SG_ CSDO_011_CS M : 0|8@1+ (1,0) [0|0] ""  I_O_Device_1

BO_ 1546 CSDO_010: 8 Vector__XXX

BO_ 1545 CSDO_009: 8 Vector__XXX

BO_ 1544 CSDO_008: 8 Vector__XXX

BO_ 1543 CSDO_007: 8 Vector__XXX

BO_ 1542 CSDO_006: 8 Vector__XXX

BO_ 1541 CSDO_005: 8 Vector__XXX

BO_ 1540 CSDO_004: 8 Vector__XXX

BO_ 1539 CSDO_003: 8 Vector__XXX

BO_ 1538 CSDO_002: 8 Vector__XXX

BO_ 1537 CSDO_001: 8 Vector__XXX
 SG_ CSDO_001_CS M : 0|8@1+ (1,0) [0|0] ""  NMT_Master

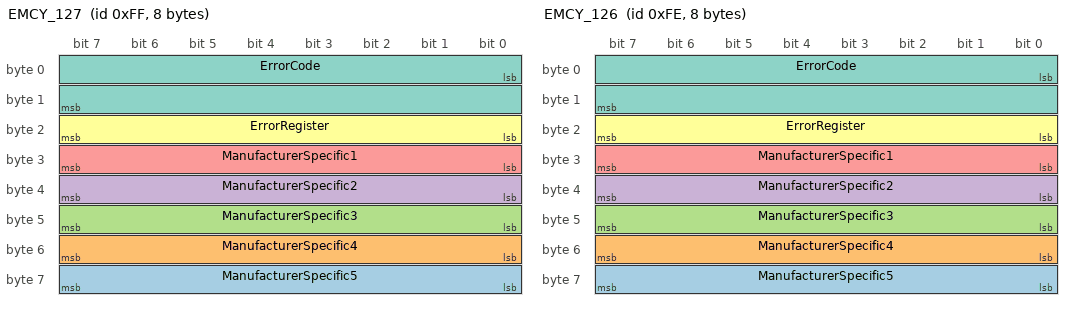
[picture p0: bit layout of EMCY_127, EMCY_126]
BO_ 255 EMCY_127: 8 Vector__XXX
 SG_ ManufacturerSpecific5 : 56|8@1+ (1,0) [0|0] "" Vector__XXX
 SG_ ManufacturerSpecific4 : 48|8@1+ (1,0) [0|0] "" Vector__XXX
 SG_ ManufacturerSpecific3 : 40|8@1+ (1,0) [0|0] "" Vector__XXX
 SG_ ManufacturerSpecific2 : 32|8@1+ (1,0) [0|0] "" Vector__XXX
 SG_ ManufacturerSpecific1 : 24|8@1+ (1,0) [0|0] "" Vector__XXX
 SG_ ErrorRegister : 16|8@1+ (1,0) [0|0] "" Vector__XXX
 SG_ ErrorCode : 0|16@1+ (1,0) [0|0] "" Vector__XXX

BO_ 254 EMCY_126: 8 Vector__XXX
 SG_ ManufacturerSpecific5 : 56|8@1+ (1,0) [0|0] "" Vector__XXX
 SG_ ManufacturerSpecific4 : 48|8@1+ (1,0) [0|0] "" Vector__XXX
 SG_ ManufacturerSpecific3 : 40|8@1+ (1,0) [0|0] "" Vector__XXX
 SG_ ManufacturerSpecific2 : 32|8@1+ (1,0) [0|0] "" Vector__XXX
 SG_ ManufacturerSpecific1 : 24|8@1+ (1,0) [0|0] "" Vector__XXX
 SG_ ErrorRegister : 16|8@1+ (1,0) [0|0] "" Vector__XXX
 SG_ ErrorCode : 0|16@1+ (1,0) [0|0] "" Vector__XXX

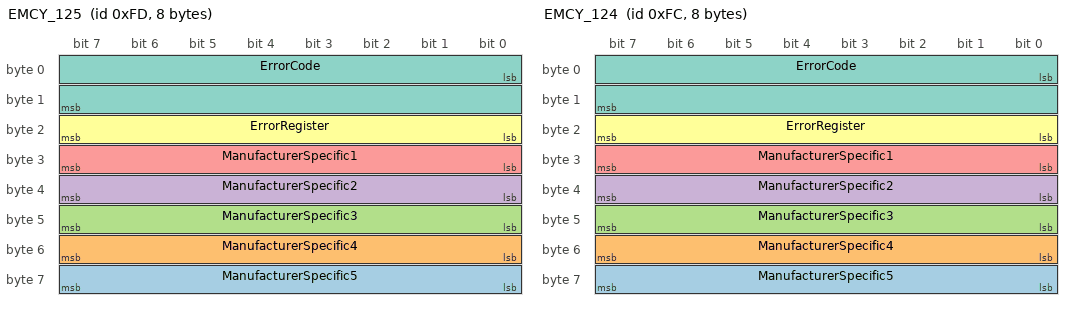
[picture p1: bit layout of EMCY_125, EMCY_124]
BO_ 253 EMCY_125: 8 Vector__XXX
 SG_ ManufacturerSpecific5 : 56|8@1+ (1,0) [0|0] "" Vector__XXX
 SG_ ManufacturerSpecific4 : 48|8@1+ (1,0) [0|0] "" Vector__XXX
 SG_ ManufacturerSpecific3 : 40|8@1+ (1,0) [0|0] "" Vector__XXX
 SG_ ManufacturerSpecific2 : 32|8@1+ (1,0) [0|0] "" Vector__XXX
 SG_ ManufacturerSpecific1 : 24|8@1+ (1,0) [0|0] "" Vector__XXX
 SG_ ErrorRegister : 16|8@1+ (1,0) [0|0] "" Vector__XXX
 SG_ ErrorCode : 0|16@1+ (1,0) [0|0] "" Vector__XXX

BO_ 252 EMCY_124: 8 Vector__XXX
 SG_ ManufacturerSpecific5 : 56|8@1+ (1,0) [0|0] "" Vector__XXX
 SG_ ManufacturerSpecific4 : 48|8@1+ (1,0) [0|0] "" Vector__XXX
 SG_ ManufacturerSpecific3 : 40|8@1+ (1,0) [0|0] "" Vector__XXX
 SG_ ManufacturerSpecific2 : 32|8@1+ (1,0) [0|0] "" Vector__XXX
 SG_ ManufacturerSpecific1 : 24|8@1+ (1,0) [0|0] "" Vector__XXX
 SG_ ErrorRegister : 16|8@1+ (1,0) [0|0] "" Vector__XXX
 SG_ ErrorCode : 0|16@1+ (1,0) [0|0] "" Vector__XXX

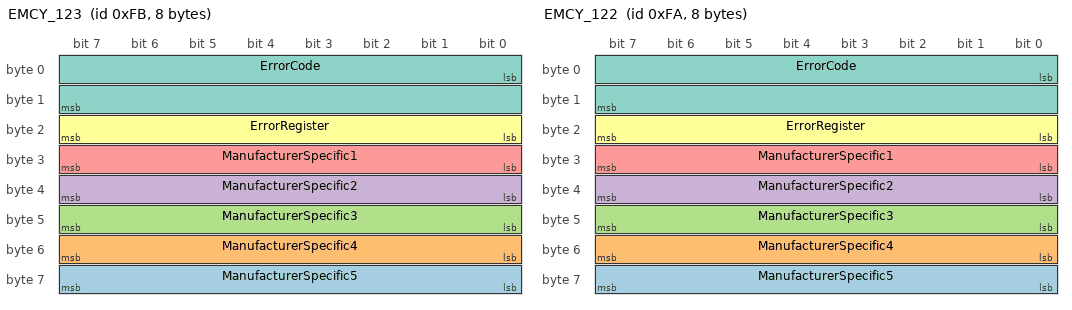
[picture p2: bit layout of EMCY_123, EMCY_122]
BO_ 251 EMCY_123: 8 Vector__XXX
 SG_ ManufacturerSpecific5 : 56|8@1+ (1,0) [0|0] "" Vector__XXX
 SG_ ManufacturerSpecific4 : 48|8@1+ (1,0) [0|0] "" Vector__XXX
 SG_ ManufacturerSpecific3 : 40|8@1+ (1,0) [0|0] "" Vector__XXX
 SG_ ManufacturerSpecific2 : 32|8@1+ (1,0) [0|0] "" Vector__XXX
 SG_ ManufacturerSpecific1 : 24|8@1+ (1,0) [0|0] "" Vector__XXX
 SG_ ErrorRegister : 16|8@1+ (1,0) [0|0] "" Vector__XXX
 SG_ ErrorCode : 0|16@1+ (1,0) [0|0] "" Vector__XXX

BO_ 250 EMCY_122: 8 Vector__XXX
 SG_ ManufacturerSpecific5 : 56|8@1+ (1,0) [0|0] "" Vector__XXX
 SG_ ManufacturerSpecific4 : 48|8@1+ (1,0) [0|0] "" Vector__XXX
 SG_ ManufacturerSpecific3 : 40|8@1+ (1,0) [0|0] "" Vector__XXX
 SG_ ManufacturerSpecific2 : 32|8@1+ (1,0) [0|0] "" Vector__XXX
 SG_ ManufacturerSpecific1 : 24|8@1+ (1,0) [0|0] "" Vector__XXX
 SG_ ErrorRegister : 16|8@1+ (1,0) [0|0] "" Vector__XXX
 SG_ ErrorCode : 0|16@1+ (1,0) [0|0] "" Vector__XXX

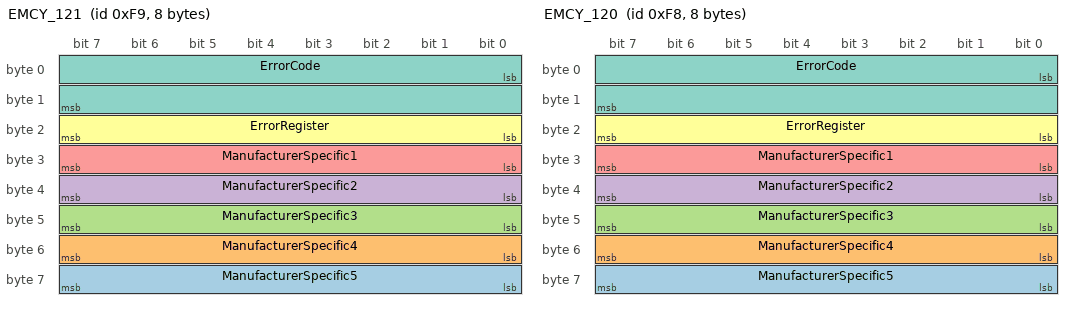
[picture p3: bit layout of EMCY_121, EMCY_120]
BO_ 249 EMCY_121: 8 Vector__XXX
 SG_ ManufacturerSpecific5 : 56|8@1+ (1,0) [0|0] "" Vector__XXX
 SG_ ManufacturerSpecific4 : 48|8@1+ (1,0) [0|0] "" Vector__XXX
 SG_ ManufacturerSpecific3 : 40|8@1+ (1,0) [0|0] "" Vector__XXX
 SG_ ManufacturerSpecific2 : 32|8@1+ (1,0) [0|0] "" Vector__XXX
 SG_ ManufacturerSpecific1 : 24|8@1+ (1,0) [0|0] "" Vector__XXX
 SG_ ErrorRegister : 16|8@1+ (1,0) [0|0] "" Vector__XXX
 SG_ ErrorCode : 0|16@1+ (1,0) [0|0] "" Vector__XXX

BO_ 248 EMCY_120: 8 Vector__XXX
 SG_ ManufacturerSpecific5 : 56|8@1+ (1,0) [0|0] "" Vector__XXX
 SG_ ManufacturerSpecific4 : 48|8@1+ (1,0) [0|0] "" Vector__XXX
 SG_ ManufacturerSpecific3 : 40|8@1+ (1,0) [0|0] "" Vector__XXX
 SG_ ManufacturerSpecific2 : 32|8@1+ (1,0) [0|0] "" Vector__XXX
 SG_ ManufacturerSpecific1 : 24|8@1+ (1,0) [0|0] "" Vector__XXX
 SG_ ErrorRegister : 16|8@1+ (1,0) [0|0] "" Vector__XXX
 SG_ ErrorCode : 0|16@1+ (1,0) [0|0] "" Vector__XXX

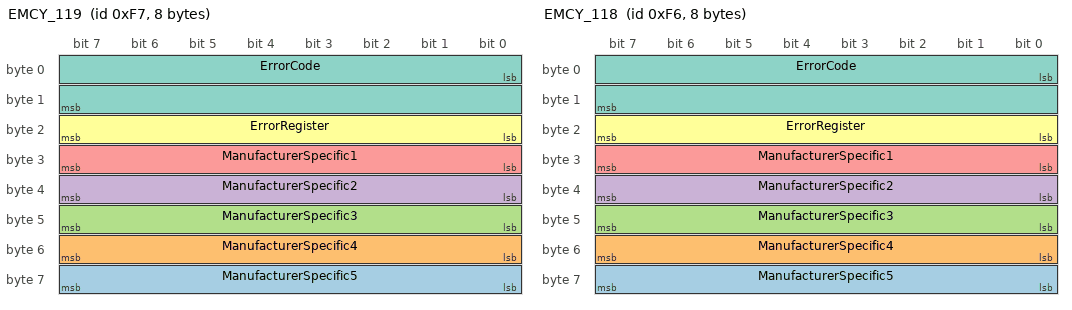
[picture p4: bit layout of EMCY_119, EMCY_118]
BO_ 247 EMCY_119: 8 Vector__XXX
 SG_ ManufacturerSpecific5 : 56|8@1+ (1,0) [0|0] "" Vector__XXX
 SG_ ManufacturerSpecific4 : 48|8@1+ (1,0) [0|0] "" Vector__XXX
 SG_ ManufacturerSpecific3 : 40|8@1+ (1,0) [0|0] "" Vector__XXX
 SG_ ManufacturerSpecific2 : 32|8@1+ (1,0) [0|0] "" Vector__XXX
 SG_ ManufacturerSpecific1 : 24|8@1+ (1,0) [0|0] "" Vector__XXX
 SG_ ErrorRegister : 16|8@1+ (1,0) [0|0] "" Vector__XXX
 SG_ ErrorCode : 0|16@1+ (1,0) [0|0] "" Vector__XXX

BO_ 246 EMCY_118: 8 Vector__XXX
 SG_ ManufacturerSpecific5 : 56|8@1+ (1,0) [0|0] "" Vector__XXX
 SG_ ManufacturerSpecific4 : 48|8@1+ (1,0) [0|0] "" Vector__XXX
 SG_ ManufacturerSpecific3 : 40|8@1+ (1,0) [0|0] "" Vector__XXX
 SG_ ManufacturerSpecific2 : 32|8@1+ (1,0) [0|0] "" Vector__XXX
 SG_ ManufacturerSpecific1 : 24|8@1+ (1,0) [0|0] "" Vector__XXX
 SG_ ErrorRegister : 16|8@1+ (1,0) [0|0] "" Vector__XXX
 SG_ ErrorCode : 0|16@1+ (1,0) [0|0] "" Vector__XXX

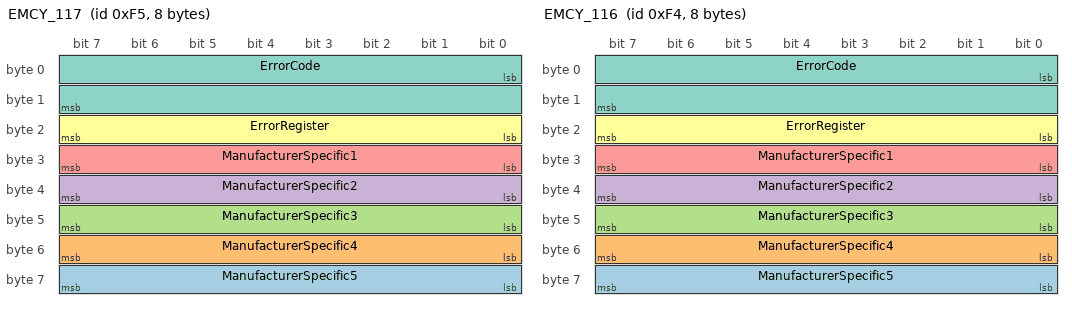
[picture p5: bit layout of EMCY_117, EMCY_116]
BO_ 245 EMCY_117: 8 Vector__XXX
 SG_ ManufacturerSpecific5 : 56|8@1+ (1,0) [0|0] "" Vector__XXX
 SG_ ManufacturerSpecific4 : 48|8@1+ (1,0) [0|0] "" Vector__XXX
 SG_ ManufacturerSpecific3 : 40|8@1+ (1,0) [0|0] "" Vector__XXX
 SG_ ManufacturerSpecific2 : 32|8@1+ (1,0) [0|0] "" Vector__XXX
 SG_ ManufacturerSpecific1 : 24|8@1+ (1,0) [0|0] "" Vector__XXX
 SG_ ErrorRegister : 16|8@1+ (1,0) [0|0] "" Vector__XXX
 SG_ ErrorCode : 0|16@1+ (1,0) [0|0] "" Vector__XXX

BO_ 244 EMCY_116: 8 Vector__XXX
 SG_ ManufacturerSpecific5 : 56|8@1+ (1,0) [0|0] "" Vector__XXX
 SG_ ManufacturerSpecific4 : 48|8@1+ (1,0) [0|0] "" Vector__XXX
 SG_ ManufacturerSpecific3 : 40|8@1+ (1,0) [0|0] "" Vector__XXX
 SG_ ManufacturerSpecific2 : 32|8@1+ (1,0) [0|0] "" Vector__XXX
 SG_ ManufacturerSpecific1 : 24|8@1+ (1,0) [0|0] "" Vector__XXX
 SG_ ErrorRegister : 16|8@1+ (1,0) [0|0] "" Vector__XXX
 SG_ ErrorCode : 0|16@1+ (1,0) [0|0] "" Vector__XXX

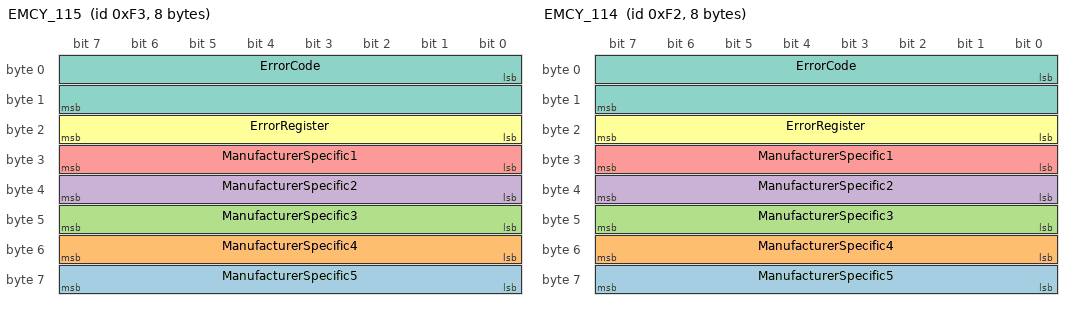
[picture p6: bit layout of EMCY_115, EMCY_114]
BO_ 243 EMCY_115: 8 Vector__XXX
 SG_ ManufacturerSpecific5 : 56|8@1+ (1,0) [0|0] "" Vector__XXX
 SG_ ManufacturerSpecific4 : 48|8@1+ (1,0) [0|0] "" Vector__XXX
 SG_ ManufacturerSpecific3 : 40|8@1+ (1,0) [0|0] "" Vector__XXX
 SG_ ManufacturerSpecific2 : 32|8@1+ (1,0) [0|0] "" Vector__XXX
 SG_ ManufacturerSpecific1 : 24|8@1+ (1,0) [0|0] "" Vector__XXX
 SG_ ErrorRegister : 16|8@1+ (1,0) [0|0] "" Vector__XXX
 SG_ ErrorCode : 0|16@1+ (1,0) [0|0] "" Vector__XXX

BO_ 242 EMCY_114: 8 Vector__XXX
 SG_ ManufacturerSpecific5 : 56|8@1+ (1,0) [0|0] "" Vector__XXX
 SG_ ManufacturerSpecific4 : 48|8@1+ (1,0) [0|0] "" Vector__XXX
 SG_ ManufacturerSpecific3 : 40|8@1+ (1,0) [0|0] "" Vector__XXX
 SG_ ManufacturerSpecific2 : 32|8@1+ (1,0) [0|0] "" Vector__XXX
 SG_ ManufacturerSpecific1 : 24|8@1+ (1,0) [0|0] "" Vector__XXX
 SG_ ErrorRegister : 16|8@1+ (1,0) [0|0] "" Vector__XXX
 SG_ ErrorCode : 0|16@1+ (1,0) [0|0] "" Vector__XXX

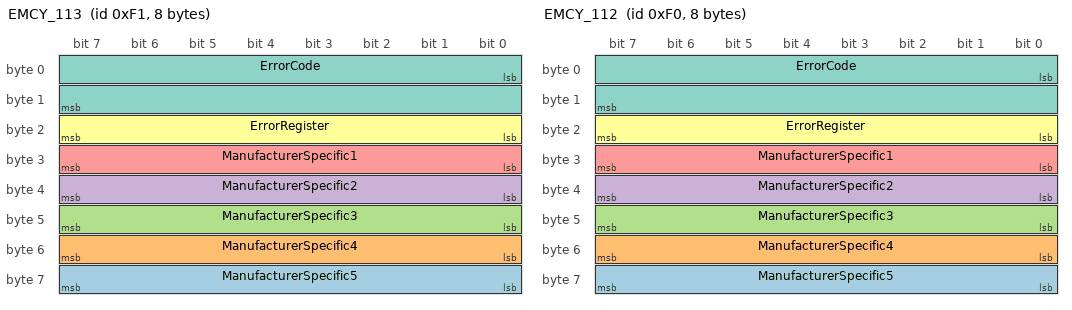
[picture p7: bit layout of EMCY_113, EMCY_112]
BO_ 241 EMCY_113: 8 Vector__XXX
 SG_ ManufacturerSpecific5 : 56|8@1+ (1,0) [0|0] "" Vector__XXX
 SG_ ManufacturerSpecific4 : 48|8@1+ (1,0) [0|0] "" Vector__XXX
 SG_ ManufacturerSpecific3 : 40|8@1+ (1,0) [0|0] "" Vector__XXX
 SG_ ManufacturerSpecific2 : 32|8@1+ (1,0) [0|0] "" Vector__XXX
 SG_ ManufacturerSpecific1 : 24|8@1+ (1,0) [0|0] "" Vector__XXX
 SG_ ErrorRegister : 16|8@1+ (1,0) [0|0] "" Vector__XXX
 SG_ ErrorCode : 0|16@1+ (1,0) [0|0] "" Vector__XXX

BO_ 240 EMCY_112: 8 Vector__XXX
 SG_ ManufacturerSpecific5 : 56|8@1+ (1,0) [0|0] "" Vector__XXX
 SG_ ManufacturerSpecific4 : 48|8@1+ (1,0) [0|0] "" Vector__XXX
 SG_ ManufacturerSpecific3 : 40|8@1+ (1,0) [0|0] "" Vector__XXX
 SG_ ManufacturerSpecific2 : 32|8@1+ (1,0) [0|0] "" Vector__XXX
 SG_ ManufacturerSpecific1 : 24|8@1+ (1,0) [0|0] "" Vector__XXX
 SG_ ErrorRegister : 16|8@1+ (1,0) [0|0] "" Vector__XXX
 SG_ ErrorCode : 0|16@1+ (1,0) [0|0] "" Vector__XXX

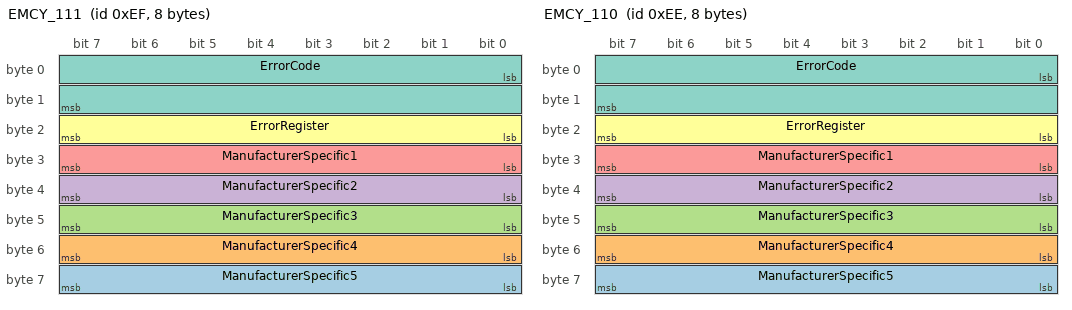
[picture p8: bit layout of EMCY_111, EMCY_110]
BO_ 239 EMCY_111: 8 Vector__XXX
 SG_ ManufacturerSpecific5 : 56|8@1+ (1,0) [0|0] "" Vector__XXX
 SG_ ManufacturerSpecific4 : 48|8@1+ (1,0) [0|0] "" Vector__XXX
 SG_ ManufacturerSpecific3 : 40|8@1+ (1,0) [0|0] "" Vector__XXX
 SG_ ManufacturerSpecific2 : 32|8@1+ (1,0) [0|0] "" Vector__XXX
 SG_ ManufacturerSpecific1 : 24|8@1+ (1,0) [0|0] "" Vector__XXX
 SG_ ErrorRegister : 16|8@1+ (1,0) [0|0] "" Vector__XXX
 SG_ ErrorCode : 0|16@1+ (1,0) [0|0] "" Vector__XXX

BO_ 238 EMCY_110: 8 Vector__XXX
 SG_ ManufacturerSpecific5 : 56|8@1+ (1,0) [0|0] "" Vector__XXX
 SG_ ManufacturerSpecific4 : 48|8@1+ (1,0) [0|0] "" Vector__XXX
 SG_ ManufacturerSpecific3 : 40|8@1+ (1,0) [0|0] "" Vector__XXX
 SG_ ManufacturerSpecific2 : 32|8@1+ (1,0) [0|0] "" Vector__XXX
 SG_ ManufacturerSpecific1 : 24|8@1+ (1,0) [0|0] "" Vector__XXX
 SG_ ErrorRegister : 16|8@1+ (1,0) [0|0] "" Vector__XXX
 SG_ ErrorCode : 0|16@1+ (1,0) [0|0] "" Vector__XXX

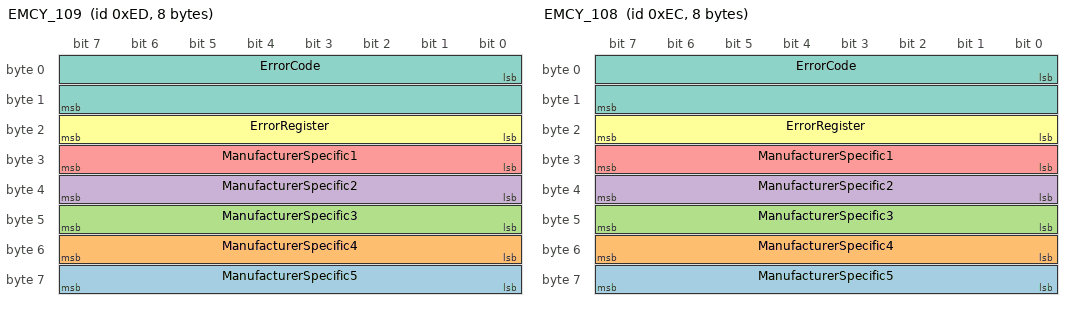
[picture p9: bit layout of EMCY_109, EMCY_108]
BO_ 237 EMCY_109: 8 Vector__XXX
 SG_ ManufacturerSpecific5 : 56|8@1+ (1,0) [0|0] "" Vector__XXX
 SG_ ManufacturerSpecific4 : 48|8@1+ (1,0) [0|0] "" Vector__XXX
 SG_ ManufacturerSpecific3 : 40|8@1+ (1,0) [0|0] "" Vector__XXX
 SG_ ManufacturerSpecific2 : 32|8@1+ (1,0) [0|0] "" Vector__XXX
 SG_ ManufacturerSpecific1 : 24|8@1+ (1,0) [0|0] "" Vector__XXX
 SG_ ErrorRegister : 16|8@1+ (1,0) [0|0] "" Vector__XXX
 SG_ ErrorCode : 0|16@1+ (1,0) [0|0] "" Vector__XXX

BO_ 236 EMCY_108: 8 Vector__XXX
 SG_ ManufacturerSpecific5 : 56|8@1+ (1,0) [0|0] "" Vector__XXX
 SG_ ManufacturerSpecific4 : 48|8@1+ (1,0) [0|0] "" Vector__XXX
 SG_ ManufacturerSpecific3 : 40|8@1+ (1,0) [0|0] "" Vector__XXX
 SG_ ManufacturerSpecific2 : 32|8@1+ (1,0) [0|0] "" Vector__XXX
 SG_ ManufacturerSpecific1 : 24|8@1+ (1,0) [0|0] "" Vector__XXX
 SG_ ErrorRegister : 16|8@1+ (1,0) [0|0] "" Vector__XXX
 SG_ ErrorCode : 0|16@1+ (1,0) [0|0] "" Vector__XXX

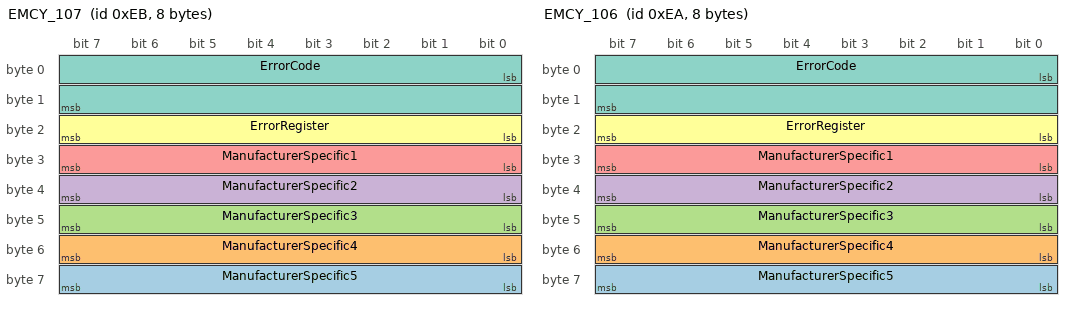
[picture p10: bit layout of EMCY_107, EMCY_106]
BO_ 235 EMCY_107: 8 Vector__XXX
 SG_ ManufacturerSpecific5 : 56|8@1+ (1,0) [0|0] "" Vector__XXX
 SG_ ManufacturerSpecific4 : 48|8@1+ (1,0) [0|0] "" Vector__XXX
 SG_ ManufacturerSpecific3 : 40|8@1+ (1,0) [0|0] "" Vector__XXX
 SG_ ManufacturerSpecific2 : 32|8@1+ (1,0) [0|0] "" Vector__XXX
 SG_ ManufacturerSpecific1 : 24|8@1+ (1,0) [0|0] "" Vector__XXX
 SG_ ErrorRegister : 16|8@1+ (1,0) [0|0] "" Vector__XXX
 SG_ ErrorCode : 0|16@1+ (1,0) [0|0] "" Vector__XXX

BO_ 234 EMCY_106: 8 Vector__XXX
 SG_ ManufacturerSpecific5 : 56|8@1+ (1,0) [0|0] "" Vector__XXX
 SG_ ManufacturerSpecific4 : 48|8@1+ (1,0) [0|0] "" Vector__XXX
 SG_ ManufacturerSpecific3 : 40|8@1+ (1,0) [0|0] "" Vector__XXX
 SG_ ManufacturerSpecific2 : 32|8@1+ (1,0) [0|0] "" Vector__XXX
 SG_ ManufacturerSpecific1 : 24|8@1+ (1,0) [0|0] "" Vector__XXX
 SG_ ErrorRegister : 16|8@1+ (1,0) [0|0] "" Vector__XXX
 SG_ ErrorCode : 0|16@1+ (1,0) [0|0] "" Vector__XXX

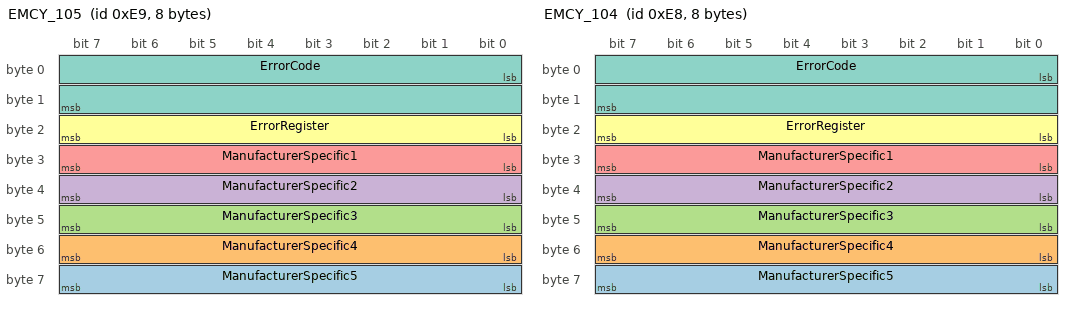
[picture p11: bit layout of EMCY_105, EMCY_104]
BO_ 233 EMCY_105: 8 Vector__XXX
 SG_ ManufacturerSpecific5 : 56|8@1+ (1,0) [0|0] "" Vector__XXX
 SG_ ManufacturerSpecific4 : 48|8@1+ (1,0) [0|0] "" Vector__XXX
 SG_ ManufacturerSpecific3 : 40|8@1+ (1,0) [0|0] "" Vector__XXX
 SG_ ManufacturerSpecific2 : 32|8@1+ (1,0) [0|0] "" Vector__XXX
 SG_ ManufacturerSpecific1 : 24|8@1+ (1,0) [0|0] "" Vector__XXX
 SG_ ErrorRegister : 16|8@1+ (1,0) [0|0] "" Vector__XXX
 SG_ ErrorCode : 0|16@1+ (1,0) [0|0] "" Vector__XXX

BO_ 232 EMCY_104: 8 Vector__XXX
 SG_ ManufacturerSpecific5 : 56|8@1+ (1,0) [0|0] "" Vector__XXX
 SG_ ManufacturerSpecific4 : 48|8@1+ (1,0) [0|0] "" Vector__XXX
 SG_ ManufacturerSpecific3 : 40|8@1+ (1,0) [0|0] "" Vector__XXX
 SG_ ManufacturerSpecific2 : 32|8@1+ (1,0) [0|0] "" Vector__XXX
 SG_ ManufacturerSpecific1 : 24|8@1+ (1,0) [0|0] "" Vector__XXX
 SG_ ErrorRegister : 16|8@1+ (1,0) [0|0] "" Vector__XXX
 SG_ ErrorCode : 0|16@1+ (1,0) [0|0] "" Vector__XXX

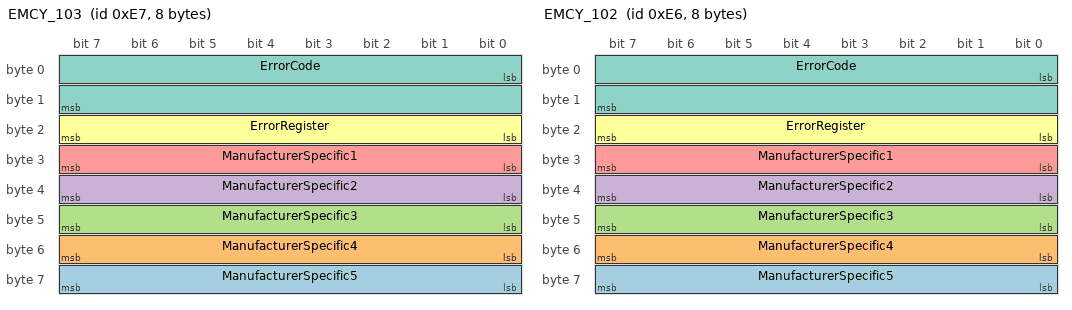
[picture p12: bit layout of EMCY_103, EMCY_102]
BO_ 231 EMCY_103: 8 Vector__XXX
 SG_ ManufacturerSpecific5 : 56|8@1+ (1,0) [0|0] "" Vector__XXX
 SG_ ManufacturerSpecific4 : 48|8@1+ (1,0) [0|0] "" Vector__XXX
 SG_ ManufacturerSpecific3 : 40|8@1+ (1,0) [0|0] "" Vector__XXX
 SG_ ManufacturerSpecific2 : 32|8@1+ (1,0) [0|0] "" Vector__XXX
 SG_ ManufacturerSpecific1 : 24|8@1+ (1,0) [0|0] "" Vector__XXX
 SG_ ErrorRegister : 16|8@1+ (1,0) [0|0] "" Vector__XXX
 SG_ ErrorCode : 0|16@1+ (1,0) [0|0] "" Vector__XXX

BO_ 230 EMCY_102: 8 Vector__XXX
 SG_ ManufacturerSpecific5 : 56|8@1+ (1,0) [0|0] "" Vector__XXX
 SG_ ManufacturerSpecific4 : 48|8@1+ (1,0) [0|0] "" Vector__XXX
 SG_ ManufacturerSpecific3 : 40|8@1+ (1,0) [0|0] "" Vector__XXX
 SG_ ManufacturerSpecific2 : 32|8@1+ (1,0) [0|0] "" Vector__XXX
 SG_ ManufacturerSpecific1 : 24|8@1+ (1,0) [0|0] "" Vector__XXX
 SG_ ErrorRegister : 16|8@1+ (1,0) [0|0] "" Vector__XXX
 SG_ ErrorCode : 0|16@1+ (1,0) [0|0] "" Vector__XXX

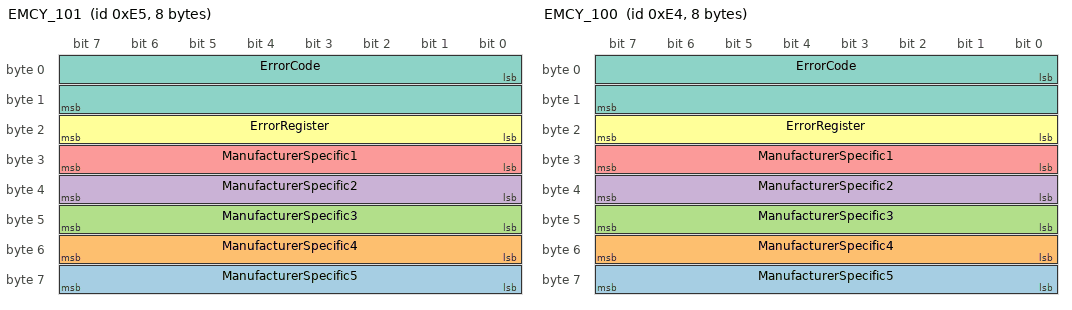
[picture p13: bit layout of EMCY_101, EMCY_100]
BO_ 229 EMCY_101: 8 Vector__XXX
 SG_ ManufacturerSpecific5 : 56|8@1+ (1,0) [0|0] "" Vector__XXX
 SG_ ManufacturerSpecific4 : 48|8@1+ (1,0) [0|0] "" Vector__XXX
 SG_ ManufacturerSpecific3 : 40|8@1+ (1,0) [0|0] "" Vector__XXX
 SG_ ManufacturerSpecific2 : 32|8@1+ (1,0) [0|0] "" Vector__XXX
 SG_ ManufacturerSpecific1 : 24|8@1+ (1,0) [0|0] "" Vector__XXX
 SG_ ErrorRegister : 16|8@1+ (1,0) [0|0] "" Vector__XXX
 SG_ ErrorCode : 0|16@1+ (1,0) [0|0] "" Vector__XXX

BO_ 228 EMCY_100: 8 Vector__XXX
 SG_ ManufacturerSpecific5 : 56|8@1+ (1,0) [0|0] "" Vector__XXX
 SG_ ManufacturerSpecific4 : 48|8@1+ (1,0) [0|0] "" Vector__XXX
 SG_ ManufacturerSpecific3 : 40|8@1+ (1,0) [0|0] "" Vector__XXX
 SG_ ManufacturerSpecific2 : 32|8@1+ (1,0) [0|0] "" Vector__XXX
 SG_ ManufacturerSpecific1 : 24|8@1+ (1,0) [0|0] "" Vector__XXX
 SG_ ErrorRegister : 16|8@1+ (1,0) [0|0] "" Vector__XXX
 SG_ ErrorCode : 0|16@1+ (1,0) [0|0] "" Vector__XXX

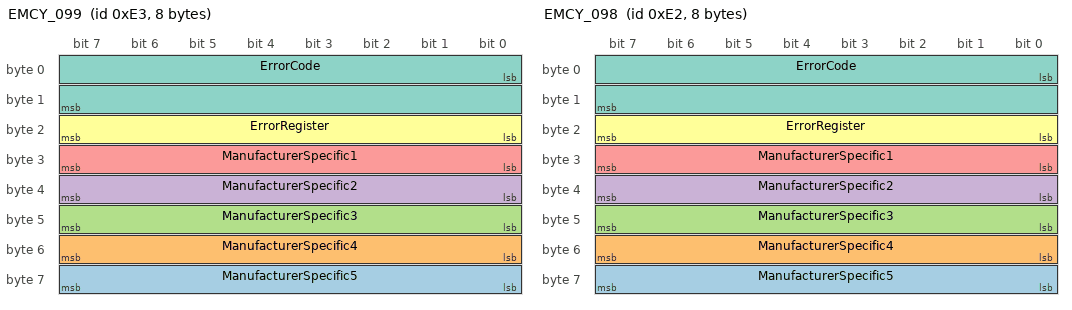
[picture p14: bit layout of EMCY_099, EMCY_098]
BO_ 227 EMCY_099: 8 Vector__XXX
 SG_ ManufacturerSpecific5 : 56|8@1+ (1,0) [0|0] "" Vector__XXX
 SG_ ManufacturerSpecific4 : 48|8@1+ (1,0) [0|0] "" Vector__XXX
 SG_ ManufacturerSpecific3 : 40|8@1+ (1,0) [0|0] "" Vector__XXX
 SG_ ManufacturerSpecific2 : 32|8@1+ (1,0) [0|0] "" Vector__XXX
 SG_ ManufacturerSpecific1 : 24|8@1+ (1,0) [0|0] "" Vector__XXX
 SG_ ErrorRegister : 16|8@1+ (1,0) [0|0] "" Vector__XXX
 SG_ ErrorCode : 0|16@1+ (1,0) [0|0] "" Vector__XXX

BO_ 226 EMCY_098: 8 Vector__XXX
 SG_ ManufacturerSpecific5 : 56|8@1+ (1,0) [0|0] "" Vector__XXX
 SG_ ManufacturerSpecific4 : 48|8@1+ (1,0) [0|0] "" Vector__XXX
 SG_ ManufacturerSpecific3 : 40|8@1+ (1,0) [0|0] "" Vector__XXX
 SG_ ManufacturerSpecific2 : 32|8@1+ (1,0) [0|0] "" Vector__XXX
 SG_ ManufacturerSpecific1 : 24|8@1+ (1,0) [0|0] "" Vector__XXX
 SG_ ErrorRegister : 16|8@1+ (1,0) [0|0] "" Vector__XXX
 SG_ ErrorCode : 0|16@1+ (1,0) [0|0] "" Vector__XXX

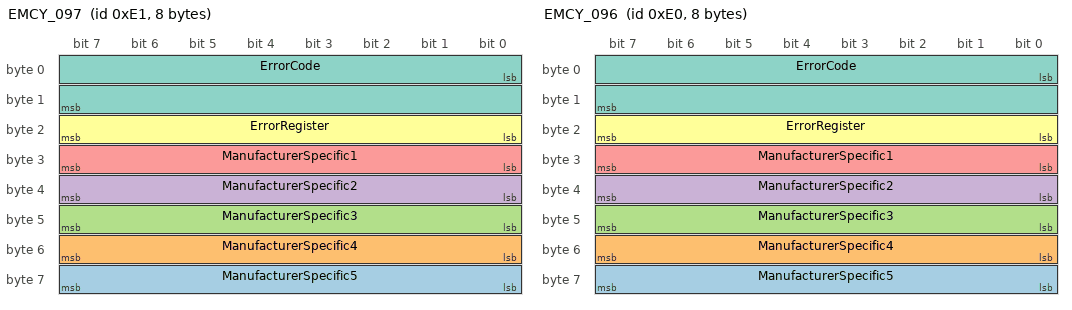
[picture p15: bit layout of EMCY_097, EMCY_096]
BO_ 225 EMCY_097: 8 Vector__XXX
 SG_ ManufacturerSpecific5 : 56|8@1+ (1,0) [0|0] "" Vector__XXX
 SG_ ManufacturerSpecific4 : 48|8@1+ (1,0) [0|0] "" Vector__XXX
 SG_ ManufacturerSpecific3 : 40|8@1+ (1,0) [0|0] "" Vector__XXX
 SG_ ManufacturerSpecific2 : 32|8@1+ (1,0) [0|0] "" Vector__XXX
 SG_ ManufacturerSpecific1 : 24|8@1+ (1,0) [0|0] "" Vector__XXX
 SG_ ErrorRegister : 16|8@1+ (1,0) [0|0] "" Vector__XXX
 SG_ ErrorCode : 0|16@1+ (1,0) [0|0] "" Vector__XXX

BO_ 224 EMCY_096: 8 Vector__XXX
 SG_ ManufacturerSpecific5 : 56|8@1+ (1,0) [0|0] "" Vector__XXX
 SG_ ManufacturerSpecific4 : 48|8@1+ (1,0) [0|0] "" Vector__XXX
 SG_ ManufacturerSpecific3 : 40|8@1+ (1,0) [0|0] "" Vector__XXX
 SG_ ManufacturerSpecific2 : 32|8@1+ (1,0) [0|0] "" Vector__XXX
 SG_ ManufacturerSpecific1 : 24|8@1+ (1,0) [0|0] "" Vector__XXX
 SG_ ErrorRegister : 16|8@1+ (1,0) [0|0] "" Vector__XXX
 SG_ ErrorCode : 0|16@1+ (1,0) [0|0] "" Vector__XXX

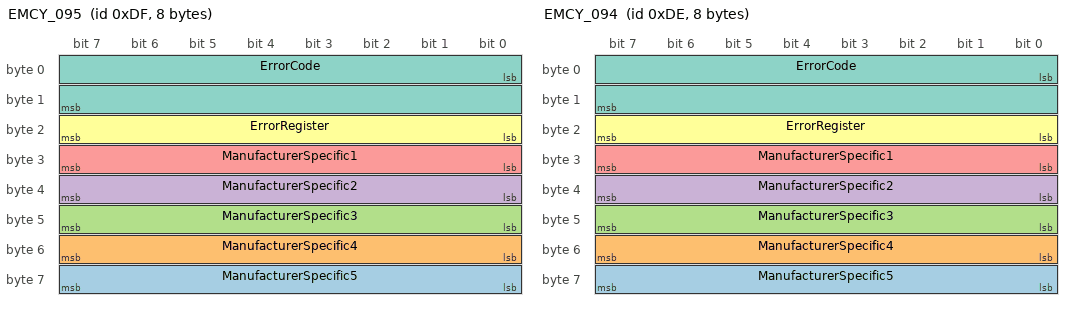
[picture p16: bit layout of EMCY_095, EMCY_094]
BO_ 223 EMCY_095: 8 Vector__XXX
 SG_ ManufacturerSpecific5 : 56|8@1+ (1,0) [0|0] "" Vector__XXX
 SG_ ManufacturerSpecific4 : 48|8@1+ (1,0) [0|0] "" Vector__XXX
 SG_ ManufacturerSpecific3 : 40|8@1+ (1,0) [0|0] "" Vector__XXX
 SG_ ManufacturerSpecific2 : 32|8@1+ (1,0) [0|0] "" Vector__XXX
 SG_ ManufacturerSpecific1 : 24|8@1+ (1,0) [0|0] "" Vector__XXX
 SG_ ErrorRegister : 16|8@1+ (1,0) [0|0] "" Vector__XXX
 SG_ ErrorCode : 0|16@1+ (1,0) [0|0] "" Vector__XXX

BO_ 222 EMCY_094: 8 Vector__XXX
 SG_ ManufacturerSpecific5 : 56|8@1+ (1,0) [0|0] "" Vector__XXX
 SG_ ManufacturerSpecific4 : 48|8@1+ (1,0) [0|0] "" Vector__XXX
 SG_ ManufacturerSpecific3 : 40|8@1+ (1,0) [0|0] "" Vector__XXX
 SG_ ManufacturerSpecific2 : 32|8@1+ (1,0) [0|0] "" Vector__XXX
 SG_ ManufacturerSpecific1 : 24|8@1+ (1,0) [0|0] "" Vector__XXX
 SG_ ErrorRegister : 16|8@1+ (1,0) [0|0] "" Vector__XXX
 SG_ ErrorCode : 0|16@1+ (1,0) [0|0] "" Vector__XXX

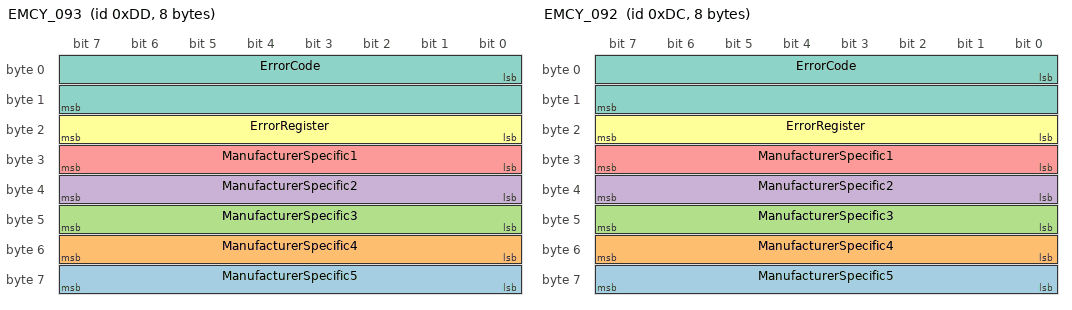
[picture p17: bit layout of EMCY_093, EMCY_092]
BO_ 221 EMCY_093: 8 Vector__XXX
 SG_ ManufacturerSpecific5 : 56|8@1+ (1,0) [0|0] "" Vector__XXX
 SG_ ManufacturerSpecific4 : 48|8@1+ (1,0) [0|0] "" Vector__XXX
 SG_ ManufacturerSpecific3 : 40|8@1+ (1,0) [0|0] "" Vector__XXX
 SG_ ManufacturerSpecific2 : 32|8@1+ (1,0) [0|0] "" Vector__XXX
 SG_ ManufacturerSpecific1 : 24|8@1+ (1,0) [0|0] "" Vector__XXX
 SG_ ErrorRegister : 16|8@1+ (1,0) [0|0] "" Vector__XXX
 SG_ ErrorCode : 0|16@1+ (1,0) [0|0] "" Vector__XXX

BO_ 220 EMCY_092: 8 Vector__XXX
 SG_ ManufacturerSpecific5 : 56|8@1+ (1,0) [0|0] "" Vector__XXX
 SG_ ManufacturerSpecific4 : 48|8@1+ (1,0) [0|0] "" Vector__XXX
 SG_ ManufacturerSpecific3 : 40|8@1+ (1,0) [0|0] "" Vector__XXX
 SG_ ManufacturerSpecific2 : 32|8@1+ (1,0) [0|0] "" Vector__XXX
 SG_ ManufacturerSpecific1 : 24|8@1+ (1,0) [0|0] "" Vector__XXX
 SG_ ErrorRegister : 16|8@1+ (1,0) [0|0] "" Vector__XXX
 SG_ ErrorCode : 0|16@1+ (1,0) [0|0] "" Vector__XXX

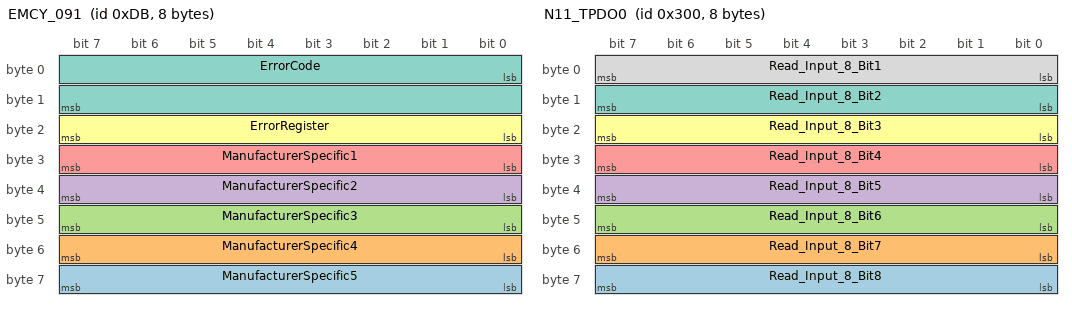
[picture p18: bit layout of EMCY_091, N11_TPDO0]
BO_ 219 EMCY_091: 8 Vector__XXX
 SG_ ManufacturerSpecific5 : 56|8@1+ (1,0) [0|0] "" Vector__XXX
 SG_ ManufacturerSpecific4 : 48|8@1+ (1,0) [0|0] "" Vector__XXX
 SG_ ManufacturerSpecific3 : 40|8@1+ (1,0) [0|0] "" Vector__XXX
 SG_ ManufacturerSpecific2 : 32|8@1+ (1,0) [0|0] "" Vector__XXX
 SG_ ManufacturerSpecific1 : 24|8@1+ (1,0) [0|0] "" Vector__XXX
 SG_ ErrorRegister : 16|8@1+ (1,0) [0|0] "" Vector__XXX
 SG_ ErrorCode : 0|16@1+ (1,0) [0|0] "" Vector__XXX

BO_ 218 EMCY_090: 8 Vector__XXX
 SG_ ManufacturerSpecific5 : 56|8@1+ (1,0) [0|0] "" Vector__XXX
 SG_ ManufacturerSpecific4 : 48|8@1+ (1,0) [0|0] "" Vector__XXX
 SG_ ManufacturerSpecific3 : 40|8@1+ (1,0) [0|0] "" Vector__XXX
 SG_ ManufacturerSpecific2 : 32|8@1+ (1,0) [0|0] "" Vector__XXX
 SG_ ManufacturerSpecific1 : 24|8@1+ (1,0) [0|0] "" Vector__XXX
 SG_ ErrorRegister : 16|8@1+ (1,0) [0|0] "" Vector__XXX
 SG_ ErrorCode : 0|16@1+ (1,0) [0|0] "" Vector__XXX

BO_ 217 EMCY_089: 8 Vector__XXX
 SG_ ManufacturerSpecific5 : 56|8@1+ (1,0) [0|0] "" Vector__XXX
 SG_ ManufacturerSpecific4 : 48|8@1+ (1,0) [0|0] "" Vector__XXX
 SG_ ManufacturerSpecific3 : 40|8@1+ (1,0) [0|0] "" Vector__XXX
 SG_ ManufacturerSpecific2 : 32|8@1+ (1,0) [0|0] "" Vector__XXX
 SG_ ManufacturerSpecific1 : 24|8@1+ (1,0) [0|0] "" Vector__XXX
 SG_ ErrorRegister : 16|8@1+ (1,0) [0|0] "" Vector__XXX
 SG_ ErrorCode : 0|16@1+ (1,0) [0|0] "" Vector__XXX

BO_ 216 EMCY_088: 8 Vector__XXX
 SG_ ManufacturerSpecific5 : 56|8@1+ (1,0) [0|0] "" Vector__XXX
 SG_ ManufacturerSpecific4 : 48|8@1+ (1,0) [0|0] "" Vector__XXX
 SG_ ManufacturerSpecific3 : 40|8@1+ (1,0) [0|0] "" Vector__XXX
 SG_ ManufacturerSpecific2 : 32|8@1+ (1,0) [0|0] "" Vector__XXX
 SG_ ManufacturerSpecific1 : 24|8@1+ (1,0) [0|0] "" Vector__XXX
 SG_ ErrorRegister : 16|8@1+ (1,0) [0|0] "" Vector__XXX
 SG_ ErrorCode : 0|16@1+ (1,0) [0|0] "" Vector__XXX

BO_ 215 EMCY_087: 8 Vector__XXX
 SG_ ManufacturerSpecific5 : 56|8@1+ (1,0) [0|0] "" Vector__XXX
 SG_ ManufacturerSpecific4 : 48|8@1+ (1,0) [0|0] "" Vector__XXX
 SG_ ManufacturerSpecific3 : 40|8@1+ (1,0) [0|0] "" Vector__XXX
 SG_ ManufacturerSpecific2 : 32|8@1+ (1,0) [0|0] "" Vector__XXX
 SG_ ManufacturerSpecific1 : 24|8@1+ (1,0) [0|0] "" Vector__XXX
 SG_ ErrorRegister : 16|8@1+ (1,0) [0|0] "" Vector__XXX
 SG_ ErrorCode : 0|16@1+ (1,0) [0|0] "" Vector__XXX

BO_ 214 EMCY_086: 8 Vector__XXX
 SG_ ManufacturerSpecific5 : 56|8@1+ (1,0) [0|0] "" Vector__XXX
 SG_ ManufacturerSpecific4 : 48|8@1+ (1,0) [0|0] "" Vector__XXX
 SG_ ManufacturerSpecific3 : 40|8@1+ (1,0) [0|0] "" Vector__XXX
 SG_ ManufacturerSpecific2 : 32|8@1+ (1,0) [0|0] "" Vector__XXX
 SG_ ManufacturerSpecific1 : 24|8@1+ (1,0) [0|0] "" Vector__XXX
 SG_ ErrorRegister : 16|8@1+ (1,0) [0|0] "" Vector__XXX
 SG_ ErrorCode : 0|16@1+ (1,0) [0|0] "" Vector__XXX

BO_ 213 EMCY_085: 8 Vector__XXX
 SG_ ManufacturerSpecific5 : 56|8@1+ (1,0) [0|0] "" Vector__XXX
 SG_ ManufacturerSpecific4 : 48|8@1+ (1,0) [0|0] "" Vector__XXX
 SG_ ManufacturerSpecific3 : 40|8@1+ (1,0) [0|0] "" Vector__XXX
 SG_ ManufacturerSpecific2 : 32|8@1+ (1,0) [0|0] "" Vector__XXX
 SG_ ManufacturerSpecific1 : 24|8@1+ (1,0) [0|0] "" Vector__XXX
 SG_ ErrorRegister : 16|8@1+ (1,0) [0|0] "" Vector__XXX
 SG_ ErrorCode : 0|16@1+ (1,0) [0|0] "" Vector__XXX

BO_ 212 EMCY_084: 8 Vector__XXX
 SG_ ManufacturerSpecific5 : 56|8@1+ (1,0) [0|0] "" Vector__XXX
 SG_ ManufacturerSpecific4 : 48|8@1+ (1,0) [0|0] "" Vector__XXX
 SG_ ManufacturerSpecific3 : 40|8@1+ (1,0) [0|0] "" Vector__XXX
 SG_ ManufacturerSpecific2 : 32|8@1+ (1,0) [0|0] "" Vector__XXX
 SG_ ManufacturerSpecific1 : 24|8@1+ (1,0) [0|0] "" Vector__XXX
 SG_ ErrorRegister : 16|8@1+ (1,0) [0|0] "" Vector__XXX
 SG_ ErrorCode : 0|16@1+ (1,0) [0|0] "" Vector__XXX

BO_ 211 EMCY_083: 8 Vector__XXX
 SG_ ManufacturerSpecific5 : 56|8@1+ (1,0) [0|0] "" Vector__XXX
 SG_ ManufacturerSpecific4 : 48|8@1+ (1,0) [0|0] "" Vector__XXX
 SG_ ManufacturerSpecific3 : 40|8@1+ (1,0) [0|0] "" Vector__XXX
 SG_ ManufacturerSpecific2 : 32|8@1+ (1,0) [0|0] "" Vector__XXX
 SG_ ManufacturerSpecific1 : 24|8@1+ (1,0) [0|0] "" Vector__XXX
 SG_ ErrorRegister : 16|8@1+ (1,0) [0|0] "" Vector__XXX
 SG_ ErrorCode : 0|16@1+ (1,0) [0|0] "" Vector__XXX

BO_ 210 EMCY_082: 8 Vector__XXX
 SG_ ManufacturerSpecific5 : 56|8@1+ (1,0) [0|0] "" Vector__XXX
 SG_ ManufacturerSpecific4 : 48|8@1+ (1,0) [0|0] "" Vector__XXX
 SG_ ManufacturerSpecific3 : 40|8@1+ (1,0) [0|0] "" Vector__XXX
 SG_ ManufacturerSpecific2 : 32|8@1+ (1,0) [0|0] "" Vector__XXX
 SG_ ManufacturerSpecific1 : 24|8@1+ (1,0) [0|0] "" Vector__XXX
 SG_ ErrorRegister : 16|8@1+ (1,0) [0|0] "" Vector__XXX
 SG_ ErrorCode : 0|16@1+ (1,0) [0|0] "" Vector__XXX

BO_ 209 EMCY_081: 8 Vector__XXX
 SG_ ManufacturerSpecific5 : 56|8@1+ (1,0) [0|0] "" Vector__XXX
 SG_ ManufacturerSpecific4 : 48|8@1+ (1,0) [0|0] "" Vector__XXX
 SG_ ManufacturerSpecific3 : 40|8@1+ (1,0) [0|0] "" Vector__XXX
 SG_ ManufacturerSpecific2 : 32|8@1+ (1,0) [0|0] "" Vector__XXX
 SG_ ManufacturerSpecific1 : 24|8@1+ (1,0) [0|0] "" Vector__XXX
 SG_ ErrorRegister : 16|8@1+ (1,0) [0|0] "" Vector__XXX
 SG_ ErrorCode : 0|16@1+ (1,0) [0|0] "" Vector__XXX

BO_ 208 EMCY_080: 8 Vector__XXX
 SG_ ManufacturerSpecific5 : 56|8@1+ (1,0) [0|0] "" Vector__XXX
 SG_ ManufacturerSpecific4 : 48|8@1+ (1,0) [0|0] "" Vector__XXX
 SG_ ManufacturerSpecific3 : 40|8@1+ (1,0) [0|0] "" Vector__XXX
 SG_ ManufacturerSpecific2 : 32|8@1+ (1,0) [0|0] "" Vector__XXX
 SG_ ManufacturerSpecific1 : 24|8@1+ (1,0) [0|0] "" Vector__XXX
 SG_ ErrorRegister : 16|8@1+ (1,0) [0|0] "" Vector__XXX
 SG_ ErrorCode : 0|16@1+ (1,0) [0|0] "" Vector__XXX

BO_ 207 EMCY_079: 8 Vector__XXX
 SG_ ManufacturerSpecific5 : 56|8@1+ (1,0) [0|0] "" Vector__XXX
 SG_ ManufacturerSpecific4 : 48|8@1+ (1,0) [0|0] "" Vector__XXX
 SG_ ManufacturerSpecific3 : 40|8@1+ (1,0) [0|0] "" Vector__XXX
 SG_ ManufacturerSpecific2 : 32|8@1+ (1,0) [0|0] "" Vector__XXX
 SG_ ManufacturerSpecific1 : 24|8@1+ (1,0) [0|0] "" Vector__XXX
 SG_ ErrorRegister : 16|8@1+ (1,0) [0|0] "" Vector__XXX
 SG_ ErrorCode : 0|16@1+ (1,0) [0|0] "" Vector__XXX

BO_ 206 EMCY_078: 8 Vector__XXX
 SG_ ManufacturerSpecific5 : 56|8@1+ (1,0) [0|0] "" Vector__XXX
 SG_ ManufacturerSpecific4 : 48|8@1+ (1,0) [0|0] "" Vector__XXX
 SG_ ManufacturerSpecific3 : 40|8@1+ (1,0) [0|0] "" Vector__XXX
 SG_ ManufacturerSpecific2 : 32|8@1+ (1,0) [0|0] "" Vector__XXX
 SG_ ManufacturerSpecific1 : 24|8@1+ (1,0) [0|0] "" Vector__XXX
 SG_ ErrorRegister : 16|8@1+ (1,0) [0|0] "" Vector__XXX
 SG_ ErrorCode : 0|16@1+ (1,0) [0|0] "" Vector__XXX

BO_ 205 EMCY_077: 8 Vector__XXX
 SG_ ManufacturerSpecific5 : 56|8@1+ (1,0) [0|0] "" Vector__XXX
 SG_ ManufacturerSpecific4 : 48|8@1+ (1,0) [0|0] "" Vector__XXX
 SG_ ManufacturerSpecific3 : 40|8@1+ (1,0) [0|0] "" Vector__XXX
 SG_ ManufacturerSpecific2 : 32|8@1+ (1,0) [0|0] "" Vector__XXX
 SG_ ManufacturerSpecific1 : 24|8@1+ (1,0) [0|0] "" Vector__XXX
 SG_ ErrorRegister : 16|8@1+ (1,0) [0|0] "" Vector__XXX
 SG_ ErrorCode : 0|16@1+ (1,0) [0|0] "" Vector__XXX

BO_ 204 EMCY_076: 8 Vector__XXX
 SG_ ManufacturerSpecific5 : 56|8@1+ (1,0) [0|0] "" Vector__XXX
 SG_ ManufacturerSpecific4 : 48|8@1+ (1,0) [0|0] "" Vector__XXX
 SG_ ManufacturerSpecific3 : 40|8@1+ (1,0) [0|0] "" Vector__XXX
 SG_ ManufacturerSpecific2 : 32|8@1+ (1,0) [0|0] "" Vector__XXX
 SG_ ManufacturerSpecific1 : 24|8@1+ (1,0) [0|0] "" Vector__XXX
 SG_ ErrorRegister : 16|8@1+ (1,0) [0|0] "" Vector__XXX
 SG_ ErrorCode : 0|16@1+ (1,0) [0|0] "" Vector__XXX

BO_ 203 EMCY_075: 8 Vector__XXX
 SG_ ManufacturerSpecific5 : 56|8@1+ (1,0) [0|0] "" Vector__XXX
 SG_ ManufacturerSpecific4 : 48|8@1+ (1,0) [0|0] "" Vector__XXX
 SG_ ManufacturerSpecific3 : 40|8@1+ (1,0) [0|0] "" Vector__XXX
 SG_ ManufacturerSpecific2 : 32|8@1+ (1,0) [0|0] "" Vector__XXX
 SG_ ManufacturerSpecific1 : 24|8@1+ (1,0) [0|0] "" Vector__XXX
 SG_ ErrorRegister : 16|8@1+ (1,0) [0|0] "" Vector__XXX
 SG_ ErrorCode : 0|16@1+ (1,0) [0|0] "" Vector__XXX

BO_ 202 EMCY_074: 8 Vector__XXX
 SG_ ManufacturerSpecific5 : 56|8@1+ (1,0) [0|0] "" Vector__XXX
 SG_ ManufacturerSpecific4 : 48|8@1+ (1,0) [0|0] "" Vector__XXX
 SG_ ManufacturerSpecific3 : 40|8@1+ (1,0) [0|0] "" Vector__XXX
 SG_ ManufacturerSpecific2 : 32|8@1+ (1,0) [0|0] "" Vector__XXX
 SG_ ManufacturerSpecific1 : 24|8@1+ (1,0) [0|0] "" Vector__XXX
 SG_ ErrorRegister : 16|8@1+ (1,0) [0|0] "" Vector__XXX
 SG_ ErrorCode : 0|16@1+ (1,0) [0|0] "" Vector__XXX

BO_ 201 EMCY_073: 8 Vector__XXX
 SG_ ManufacturerSpecific5 : 56|8@1+ (1,0) [0|0] "" Vector__XXX
 SG_ ManufacturerSpecific4 : 48|8@1+ (1,0) [0|0] "" Vector__XXX
 SG_ ManufacturerSpecific3 : 40|8@1+ (1,0) [0|0] "" Vector__XXX
 SG_ ManufacturerSpecific2 : 32|8@1+ (1,0) [0|0] "" Vector__XXX
 SG_ ManufacturerSpecific1 : 24|8@1+ (1,0) [0|0] "" Vector__XXX
 SG_ ErrorRegister : 16|8@1+ (1,0) [0|0] "" Vector__XXX
 SG_ ErrorCode : 0|16@1+ (1,0) [0|0] "" Vector__XXX

BO_ 200 EMCY_072: 8 Vector__XXX
 SG_ ManufacturerSpecific5 : 56|8@1+ (1,0) [0|0] "" Vector__XXX
 SG_ ManufacturerSpecific4 : 48|8@1+ (1,0) [0|0] "" Vector__XXX
 SG_ ManufacturerSpecific3 : 40|8@1+ (1,0) [0|0] "" Vector__XXX
 SG_ ManufacturerSpecific2 : 32|8@1+ (1,0) [0|0] "" Vector__XXX
 SG_ ManufacturerSpecific1 : 24|8@1+ (1,0) [0|0] "" Vector__XXX
 SG_ ErrorRegister : 16|8@1+ (1,0) [0|0] "" Vector__XXX
 SG_ ErrorCode : 0|16@1+ (1,0) [0|0] "" Vector__XXX

BO_ 199 EMCY_071: 8 Vector__XXX
 SG_ ManufacturerSpecific5 : 56|8@1+ (1,0) [0|0] "" Vector__XXX
 SG_ ManufacturerSpecific4 : 48|8@1+ (1,0) [0|0] "" Vector__XXX
 SG_ ManufacturerSpecific3 : 40|8@1+ (1,0) [0|0] "" Vector__XXX
 SG_ ManufacturerSpecific2 : 32|8@1+ (1,0) [0|0] "" Vector__XXX
 SG_ ManufacturerSpecific1 : 24|8@1+ (1,0) [0|0] "" Vector__XXX
 SG_ ErrorRegister : 16|8@1+ (1,0) [0|0] "" Vector__XXX
 SG_ ErrorCode : 0|16@1+ (1,0) [0|0] "" Vector__XXX

BO_ 198 EMCY_070: 8 Vector__XXX
 SG_ ManufacturerSpecific5 : 56|8@1+ (1,0) [0|0] "" Vector__XXX
 SG_ ManufacturerSpecific4 : 48|8@1+ (1,0) [0|0] "" Vector__XXX
 SG_ ManufacturerSpecific3 : 40|8@1+ (1,0) [0|0] "" Vector__XXX
 SG_ ManufacturerSpecific2 : 32|8@1+ (1,0) [0|0] "" Vector__XXX
 SG_ ManufacturerSpecific1 : 24|8@1+ (1,0) [0|0] "" Vector__XXX
 SG_ ErrorRegister : 16|8@1+ (1,0) [0|0] "" Vector__XXX
 SG_ ErrorCode : 0|16@1+ (1,0) [0|0] "" Vector__XXX

BO_ 197 EMCY_069: 8 Vector__XXX
 SG_ ManufacturerSpecific5 : 56|8@1+ (1,0) [0|0] "" Vector__XXX
 SG_ ManufacturerSpecific4 : 48|8@1+ (1,0) [0|0] "" Vector__XXX
 SG_ ManufacturerSpecific3 : 40|8@1+ (1,0) [0|0] "" Vector__XXX
 SG_ ManufacturerSpecific2 : 32|8@1+ (1,0) [0|0] "" Vector__XXX
 SG_ ManufacturerSpecific1 : 24|8@1+ (1,0) [0|0] "" Vector__XXX
 SG_ ErrorRegister : 16|8@1+ (1,0) [0|0] "" Vector__XXX
 SG_ ErrorCode : 0|16@1+ (1,0) [0|0] "" Vector__XXX

BO_ 196 EMCY_068: 8 Vector__XXX
 SG_ ManufacturerSpecific5 : 56|8@1+ (1,0) [0|0] "" Vector__XXX
 SG_ ManufacturerSpecific4 : 48|8@1+ (1,0) [0|0] "" Vector__XXX
 SG_ ManufacturerSpecific3 : 40|8@1+ (1,0) [0|0] "" Vector__XXX
 SG_ ManufacturerSpecific2 : 32|8@1+ (1,0) [0|0] "" Vector__XXX
 SG_ ManufacturerSpecific1 : 24|8@1+ (1,0) [0|0] "" Vector__XXX
 SG_ ErrorRegister : 16|8@1+ (1,0) [0|0] "" Vector__XXX
 SG_ ErrorCode : 0|16@1+ (1,0) [0|0] "" Vector__XXX

BO_ 195 EMCY_067: 8 Vector__XXX
 SG_ ManufacturerSpecific5 : 56|8@1+ (1,0) [0|0] "" Vector__XXX
 SG_ ManufacturerSpecific4 : 48|8@1+ (1,0) [0|0] "" Vector__XXX
 SG_ ManufacturerSpecific3 : 40|8@1+ (1,0) [0|0] "" Vector__XXX
 SG_ ManufacturerSpecific2 : 32|8@1+ (1,0) [0|0] "" Vector__XXX
 SG_ ManufacturerSpecific1 : 24|8@1+ (1,0) [0|0] "" Vector__XXX
 SG_ ErrorRegister : 16|8@1+ (1,0) [0|0] "" Vector__XXX
 SG_ ErrorCode : 0|16@1+ (1,0) [0|0] "" Vector__XXX

BO_ 194 EMCY_066: 8 Vector__XXX
 SG_ ManufacturerSpecific5 : 56|8@1+ (1,0) [0|0] "" Vector__XXX
 SG_ ManufacturerSpecific4 : 48|8@1+ (1,0) [0|0] "" Vector__XXX
 SG_ ManufacturerSpecific3 : 40|8@1+ (1,0) [0|0] "" Vector__XXX
 SG_ ManufacturerSpecific2 : 32|8@1+ (1,0) [0|0] "" Vector__XXX
 SG_ ManufacturerSpecific1 : 24|8@1+ (1,0) [0|0] "" Vector__XXX
 SG_ ErrorRegister : 16|8@1+ (1,0) [0|0] "" Vector__XXX
 SG_ ErrorCode : 0|16@1+ (1,0) [0|0] "" Vector__XXX

BO_ 193 EMCY_065: 8 Vector__XXX
 SG_ ManufacturerSpecific5 : 56|8@1+ (1,0) [0|0] "" Vector__XXX
 SG_ ManufacturerSpecific4 : 48|8@1+ (1,0) [0|0] "" Vector__XXX
 SG_ ManufacturerSpecific3 : 40|8@1+ (1,0) [0|0] "" Vector__XXX
 SG_ ManufacturerSpecific2 : 32|8@1+ (1,0) [0|0] "" Vector__XXX
 SG_ ManufacturerSpecific1 : 24|8@1+ (1,0) [0|0] "" Vector__XXX
 SG_ ErrorRegister : 16|8@1+ (1,0) [0|0] "" Vector__XXX
 SG_ ErrorCode : 0|16@1+ (1,0) [0|0] "" Vector__XXX

BO_ 192 EMCY_064: 8 Vector__XXX
 SG_ ManufacturerSpecific5 : 56|8@1+ (1,0) [0|0] "" Vector__XXX
 SG_ ManufacturerSpecific4 : 48|8@1+ (1,0) [0|0] "" Vector__XXX
 SG_ ManufacturerSpecific3 : 40|8@1+ (1,0) [0|0] "" Vector__XXX
 SG_ ManufacturerSpecific2 : 32|8@1+ (1,0) [0|0] "" Vector__XXX
 SG_ ManufacturerSpecific1 : 24|8@1+ (1,0) [0|0] "" Vector__XXX
 SG_ ErrorRegister : 16|8@1+ (1,0) [0|0] "" Vector__XXX
 SG_ ErrorCode : 0|16@1+ (1,0) [0|0] "" Vector__XXX

BO_ 191 EMCY_063: 8 Vector__XXX
 SG_ ManufacturerSpecific5 : 56|8@1+ (1,0) [0|0] "" Vector__XXX
 SG_ ManufacturerSpecific4 : 48|8@1+ (1,0) [0|0] "" Vector__XXX
 SG_ ManufacturerSpecific3 : 40|8@1+ (1,0) [0|0] "" Vector__XXX
 SG_ ManufacturerSpecific2 : 32|8@1+ (1,0) [0|0] "" Vector__XXX
 SG_ ManufacturerSpecific1 : 24|8@1+ (1,0) [0|0] "" Vector__XXX
 SG_ ErrorRegister : 16|8@1+ (1,0) [0|0] "" Vector__XXX
 SG_ ErrorCode : 0|16@1+ (1,0) [0|0] "" Vector__XXX

BO_ 190 EMCY_062: 8 Vector__XXX
 SG_ ManufacturerSpecific5 : 56|8@1+ (1,0) [0|0] "" Vector__XXX
 SG_ ManufacturerSpecific4 : 48|8@1+ (1,0) [0|0] "" Vector__XXX
 SG_ ManufacturerSpecific3 : 40|8@1+ (1,0) [0|0] "" Vector__XXX
 SG_ ManufacturerSpecific2 : 32|8@1+ (1,0) [0|0] "" Vector__XXX
 SG_ ManufacturerSpecific1 : 24|8@1+ (1,0) [0|0] "" Vector__XXX
 SG_ ErrorRegister : 16|8@1+ (1,0) [0|0] "" Vector__XXX
 SG_ ErrorCode : 0|16@1+ (1,0) [0|0] "" Vector__XXX

BO_ 189 EMCY_061: 8 Vector__XXX
 SG_ ManufacturerSpecific5 : 56|8@1+ (1,0) [0|0] "" Vector__XXX
 SG_ ManufacturerSpecific4 : 48|8@1+ (1,0) [0|0] "" Vector__XXX
 SG_ ManufacturerSpecific3 : 40|8@1+ (1,0) [0|0] "" Vector__XXX
 SG_ ManufacturerSpecific2 : 32|8@1+ (1,0) [0|0] "" Vector__XXX
 SG_ ManufacturerSpecific1 : 24|8@1+ (1,0) [0|0] "" Vector__XXX
 SG_ ErrorRegister : 16|8@1+ (1,0) [0|0] "" Vector__XXX
 SG_ ErrorCode : 0|16@1+ (1,0) [0|0] "" Vector__XXX

BO_ 188 EMCY_060: 8 Vector__XXX
 SG_ ManufacturerSpecific5 : 56|8@1+ (1,0) [0|0] "" Vector__XXX
 SG_ ManufacturerSpecific4 : 48|8@1+ (1,0) [0|0] "" Vector__XXX
 SG_ ManufacturerSpecific3 : 40|8@1+ (1,0) [0|0] "" Vector__XXX
 SG_ ManufacturerSpecific2 : 32|8@1+ (1,0) [0|0] "" Vector__XXX
 SG_ ManufacturerSpecific1 : 24|8@1+ (1,0) [0|0] "" Vector__XXX
 SG_ ErrorRegister : 16|8@1+ (1,0) [0|0] "" Vector__XXX
 SG_ ErrorCode : 0|16@1+ (1,0) [0|0] "" Vector__XXX

BO_ 187 EMCY_059: 8 Vector__XXX
 SG_ ManufacturerSpecific5 : 56|8@1+ (1,0) [0|0] "" Vector__XXX
 SG_ ManufacturerSpecific4 : 48|8@1+ (1,0) [0|0] "" Vector__XXX
 SG_ ManufacturerSpecific3 : 40|8@1+ (1,0) [0|0] "" Vector__XXX
 SG_ ManufacturerSpecific2 : 32|8@1+ (1,0) [0|0] "" Vector__XXX
 SG_ ManufacturerSpecific1 : 24|8@1+ (1,0) [0|0] "" Vector__XXX
 SG_ ErrorRegister : 16|8@1+ (1,0) [0|0] "" Vector__XXX
 SG_ ErrorCode : 0|16@1+ (1,0) [0|0] "" Vector__XXX

BO_ 186 EMCY_058: 8 Vector__XXX
 SG_ ManufacturerSpecific5 : 56|8@1+ (1,0) [0|0] "" Vector__XXX
 SG_ ManufacturerSpecific4 : 48|8@1+ (1,0) [0|0] "" Vector__XXX
 SG_ ManufacturerSpecific3 : 40|8@1+ (1,0) [0|0] "" Vector__XXX
 SG_ ManufacturerSpecific2 : 32|8@1+ (1,0) [0|0] "" Vector__XXX
 SG_ ManufacturerSpecific1 : 24|8@1+ (1,0) [0|0] "" Vector__XXX
 SG_ ErrorRegister : 16|8@1+ (1,0) [0|0] "" Vector__XXX
 SG_ ErrorCode : 0|16@1+ (1,0) [0|0] "" Vector__XXX

BO_ 185 EMCY_057: 8 Vector__XXX
 SG_ ManufacturerSpecific5 : 56|8@1+ (1,0) [0|0] "" Vector__XXX
 SG_ ManufacturerSpecific4 : 48|8@1+ (1,0) [0|0] "" Vector__XXX
 SG_ ManufacturerSpecific3 : 40|8@1+ (1,0) [0|0] "" Vector__XXX
 SG_ ManufacturerSpecific2 : 32|8@1+ (1,0) [0|0] "" Vector__XXX
 SG_ ManufacturerSpecific1 : 24|8@1+ (1,0) [0|0] "" Vector__XXX
 SG_ ErrorRegister : 16|8@1+ (1,0) [0|0] "" Vector__XXX
 SG_ ErrorCode : 0|16@1+ (1,0) [0|0] "" Vector__XXX

BO_ 184 EMCY_056: 8 Vector__XXX
 SG_ ManufacturerSpecific5 : 56|8@1+ (1,0) [0|0] "" Vector__XXX
 SG_ ManufacturerSpecific4 : 48|8@1+ (1,0) [0|0] "" Vector__XXX
 SG_ ManufacturerSpecific3 : 40|8@1+ (1,0) [0|0] "" Vector__XXX
 SG_ ManufacturerSpecific2 : 32|8@1+ (1,0) [0|0] "" Vector__XXX
 SG_ ManufacturerSpecific1 : 24|8@1+ (1,0) [0|0] "" Vector__XXX
 SG_ ErrorRegister : 16|8@1+ (1,0) [0|0] "" Vector__XXX
 SG_ ErrorCode : 0|16@1+ (1,0) [0|0] "" Vector__XXX

BO_ 183 EMCY_055: 8 Vector__XXX
 SG_ ManufacturerSpecific5 : 56|8@1+ (1,0) [0|0] "" Vector__XXX
 SG_ ManufacturerSpecific4 : 48|8@1+ (1,0) [0|0] "" Vector__XXX
 SG_ ManufacturerSpecific3 : 40|8@1+ (1,0) [0|0] "" Vector__XXX
 SG_ ManufacturerSpecific2 : 32|8@1+ (1,0) [0|0] "" Vector__XXX
 SG_ ManufacturerSpecific1 : 24|8@1+ (1,0) [0|0] "" Vector__XXX
 SG_ ErrorRegister : 16|8@1+ (1,0) [0|0] "" Vector__XXX
 SG_ ErrorCode : 0|16@1+ (1,0) [0|0] "" Vector__XXX

BO_ 182 EMCY_054: 8 Vector__XXX
 SG_ ManufacturerSpecific5 : 56|8@1+ (1,0) [0|0] "" Vector__XXX
 SG_ ManufacturerSpecific4 : 48|8@1+ (1,0) [0|0] "" Vector__XXX
 SG_ ManufacturerSpecific3 : 40|8@1+ (1,0) [0|0] "" Vector__XXX
 SG_ ManufacturerSpecific2 : 32|8@1+ (1,0) [0|0] "" Vector__XXX
 SG_ ManufacturerSpecific1 : 24|8@1+ (1,0) [0|0] "" Vector__XXX
 SG_ ErrorRegister : 16|8@1+ (1,0) [0|0] "" Vector__XXX
 SG_ ErrorCode : 0|16@1+ (1,0) [0|0] "" Vector__XXX

BO_ 181 EMCY_053: 8 Vector__XXX
 SG_ ManufacturerSpecific5 : 56|8@1+ (1,0) [0|0] "" Vector__XXX
 SG_ ManufacturerSpecific4 : 48|8@1+ (1,0) [0|0] "" Vector__XXX
 SG_ ManufacturerSpecific3 : 40|8@1+ (1,0) [0|0] "" Vector__XXX
 SG_ ManufacturerSpecific2 : 32|8@1+ (1,0) [0|0] "" Vector__XXX
 SG_ ManufacturerSpecific1 : 24|8@1+ (1,0) [0|0] "" Vector__XXX
 SG_ ErrorRegister : 16|8@1+ (1,0) [0|0] "" Vector__XXX
 SG_ ErrorCode : 0|16@1+ (1,0) [0|0] "" Vector__XXX

BO_ 180 EMCY_052: 8 Vector__XXX
 SG_ ManufacturerSpecific5 : 56|8@1+ (1,0) [0|0] "" Vector__XXX
 SG_ ManufacturerSpecific4 : 48|8@1+ (1,0) [0|0] "" Vector__XXX
 SG_ ManufacturerSpecific3 : 40|8@1+ (1,0) [0|0] "" Vector__XXX
 SG_ ManufacturerSpecific2 : 32|8@1+ (1,0) [0|0] "" Vector__XXX
 SG_ ManufacturerSpecific1 : 24|8@1+ (1,0) [0|0] "" Vector__XXX
 SG_ ErrorRegister : 16|8@1+ (1,0) [0|0] "" Vector__XXX
 SG_ ErrorCode : 0|16@1+ (1,0) [0|0] "" Vector__XXX

BO_ 179 EMCY_051: 8 Vector__XXX
 SG_ ManufacturerSpecific5 : 56|8@1+ (1,0) [0|0] "" Vector__XXX
 SG_ ManufacturerSpecific4 : 48|8@1+ (1,0) [0|0] "" Vector__XXX
 SG_ ManufacturerSpecific3 : 40|8@1+ (1,0) [0|0] "" Vector__XXX
 SG_ ManufacturerSpecific2 : 32|8@1+ (1,0) [0|0] "" Vector__XXX
 SG_ ManufacturerSpecific1 : 24|8@1+ (1,0) [0|0] "" Vector__XXX
 SG_ ErrorRegister : 16|8@1+ (1,0) [0|0] "" Vector__XXX
 SG_ ErrorCode : 0|16@1+ (1,0) [0|0] "" Vector__XXX

BO_ 178 EMCY_050: 8 Vector__XXX
 SG_ ManufacturerSpecific5 : 56|8@1+ (1,0) [0|0] "" Vector__XXX
 SG_ ManufacturerSpecific4 : 48|8@1+ (1,0) [0|0] "" Vector__XXX
 SG_ ManufacturerSpecific3 : 40|8@1+ (1,0) [0|0] "" Vector__XXX
 SG_ ManufacturerSpecific2 : 32|8@1+ (1,0) [0|0] "" Vector__XXX
 SG_ ManufacturerSpecific1 : 24|8@1+ (1,0) [0|0] "" Vector__XXX
 SG_ ErrorRegister : 16|8@1+ (1,0) [0|0] "" Vector__XXX
 SG_ ErrorCode : 0|16@1+ (1,0) [0|0] "" Vector__XXX

BO_ 177 EMCY_049: 8 Vector__XXX
 SG_ ManufacturerSpecific5 : 56|8@1+ (1,0) [0|0] "" Vector__XXX
 SG_ ManufacturerSpecific4 : 48|8@1+ (1,0) [0|0] "" Vector__XXX
 SG_ ManufacturerSpecific3 : 40|8@1+ (1,0) [0|0] "" Vector__XXX
 SG_ ManufacturerSpecific2 : 32|8@1+ (1,0) [0|0] "" Vector__XXX
 SG_ ManufacturerSpecific1 : 24|8@1+ (1,0) [0|0] "" Vector__XXX
 SG_ ErrorRegister : 16|8@1+ (1,0) [0|0] "" Vector__XXX
 SG_ ErrorCode : 0|16@1+ (1,0) [0|0] "" Vector__XXX

BO_ 176 EMCY_048: 8 Vector__XXX
 SG_ ManufacturerSpecific5 : 56|8@1+ (1,0) [0|0] "" Vector__XXX
 SG_ ManufacturerSpecific4 : 48|8@1+ (1,0) [0|0] "" Vector__XXX
 SG_ ManufacturerSpecific3 : 40|8@1+ (1,0) [0|0] "" Vector__XXX
 SG_ ManufacturerSpecific2 : 32|8@1+ (1,0) [0|0] "" Vector__XXX
 SG_ ManufacturerSpecific1 : 24|8@1+ (1,0) [0|0] "" Vector__XXX
 SG_ ErrorRegister : 16|8@1+ (1,0) [0|0] "" Vector__XXX
 SG_ ErrorCode : 0|16@1+ (1,0) [0|0] "" Vector__XXX

BO_ 175 EMCY_047: 8 Vector__XXX
 SG_ ManufacturerSpecific5 : 56|8@1+ (1,0) [0|0] "" Vector__XXX
 SG_ ManufacturerSpecific4 : 48|8@1+ (1,0) [0|0] "" Vector__XXX
 SG_ ManufacturerSpecific3 : 40|8@1+ (1,0) [0|0] "" Vector__XXX
 SG_ ManufacturerSpecific2 : 32|8@1+ (1,0) [0|0] "" Vector__XXX
 SG_ ManufacturerSpecific1 : 24|8@1+ (1,0) [0|0] "" Vector__XXX
 SG_ ErrorRegister : 16|8@1+ (1,0) [0|0] "" Vector__XXX
 SG_ ErrorCode : 0|16@1+ (1,0) [0|0] "" Vector__XXX

BO_ 174 EMCY_046: 8 Vector__XXX
 SG_ ManufacturerSpecific5 : 56|8@1+ (1,0) [0|0] "" Vector__XXX
 SG_ ManufacturerSpecific4 : 48|8@1+ (1,0) [0|0] "" Vector__XXX
 SG_ ManufacturerSpecific3 : 40|8@1+ (1,0) [0|0] "" Vector__XXX
 SG_ ManufacturerSpecific2 : 32|8@1+ (1,0) [0|0] "" Vector__XXX
 SG_ ManufacturerSpecific1 : 24|8@1+ (1,0) [0|0] "" Vector__XXX
 SG_ ErrorRegister : 16|8@1+ (1,0) [0|0] "" Vector__XXX
 SG_ ErrorCode : 0|16@1+ (1,0) [0|0] "" Vector__XXX

BO_ 173 EMCY_045: 8 Vector__XXX
 SG_ ManufacturerSpecific5 : 56|8@1+ (1,0) [0|0] "" Vector__XXX
 SG_ ManufacturerSpecific4 : 48|8@1+ (1,0) [0|0] "" Vector__XXX
 SG_ ManufacturerSpecific3 : 40|8@1+ (1,0) [0|0] "" Vector__XXX
 SG_ ManufacturerSpecific2 : 32|8@1+ (1,0) [0|0] "" Vector__XXX
 SG_ ManufacturerSpecific1 : 24|8@1+ (1,0) [0|0] "" Vector__XXX
 SG_ ErrorRegister : 16|8@1+ (1,0) [0|0] "" Vector__XXX
 SG_ ErrorCode : 0|16@1+ (1,0) [0|0] "" Vector__XXX

BO_ 172 EMCY_044: 8 Vector__XXX
 SG_ ManufacturerSpecific5 : 56|8@1+ (1,0) [0|0] "" Vector__XXX
 SG_ ManufacturerSpecific4 : 48|8@1+ (1,0) [0|0] "" Vector__XXX
 SG_ ManufacturerSpecific3 : 40|8@1+ (1,0) [0|0] "" Vector__XXX
 SG_ ManufacturerSpecific2 : 32|8@1+ (1,0) [0|0] "" Vector__XXX
 SG_ ManufacturerSpecific1 : 24|8@1+ (1,0) [0|0] "" Vector__XXX
 SG_ ErrorRegister : 16|8@1+ (1,0) [0|0] "" Vector__XXX
 SG_ ErrorCode : 0|16@1+ (1,0) [0|0] "" Vector__XXX

BO_ 171 EMCY_043: 8 Vector__XXX
 SG_ ManufacturerSpecific5 : 56|8@1+ (1,0) [0|0] "" Vector__XXX
 SG_ ManufacturerSpecific4 : 48|8@1+ (1,0) [0|0] "" Vector__XXX
 SG_ ManufacturerSpecific3 : 40|8@1+ (1,0) [0|0] "" Vector__XXX
 SG_ ManufacturerSpecific2 : 32|8@1+ (1,0) [0|0] "" Vector__XXX
 SG_ ManufacturerSpecific1 : 24|8@1+ (1,0) [0|0] "" Vector__XXX
 SG_ ErrorRegister : 16|8@1+ (1,0) [0|0] "" Vector__XXX
 SG_ ErrorCode : 0|16@1+ (1,0) [0|0] "" Vector__XXX

BO_ 170 EMCY_042: 8 Vector__XXX
 SG_ ManufacturerSpecific5 : 56|8@1+ (1,0) [0|0] "" Vector__XXX
 SG_ ManufacturerSpecific4 : 48|8@1+ (1,0) [0|0] "" Vector__XXX
 SG_ ManufacturerSpecific3 : 40|8@1+ (1,0) [0|0] "" Vector__XXX
 SG_ ManufacturerSpecific2 : 32|8@1+ (1,0) [0|0] "" Vector__XXX
 SG_ ManufacturerSpecific1 : 24|8@1+ (1,0) [0|0] "" Vector__XXX
 SG_ ErrorRegister : 16|8@1+ (1,0) [0|0] "" Vector__XXX
 SG_ ErrorCode : 0|16@1+ (1,0) [0|0] "" Vector__XXX

BO_ 169 EMCY_041: 8 Vector__XXX
 SG_ ManufacturerSpecific5 : 56|8@1+ (1,0) [0|0] "" Vector__XXX
 SG_ ManufacturerSpecific4 : 48|8@1+ (1,0) [0|0] "" Vector__XXX
 SG_ ManufacturerSpecific3 : 40|8@1+ (1,0) [0|0] "" Vector__XXX
 SG_ ManufacturerSpecific2 : 32|8@1+ (1,0) [0|0] "" Vector__XXX
 SG_ ManufacturerSpecific1 : 24|8@1+ (1,0) [0|0] "" Vector__XXX
 SG_ ErrorRegister : 16|8@1+ (1,0) [0|0] "" Vector__XXX
 SG_ ErrorCode : 0|16@1+ (1,0) [0|0] "" Vector__XXX

BO_ 168 EMCY_040: 8 Vector__XXX
 SG_ ManufacturerSpecific5 : 56|8@1+ (1,0) [0|0] "" Vector__XXX
 SG_ ManufacturerSpecific4 : 48|8@1+ (1,0) [0|0] "" Vector__XXX
 SG_ ManufacturerSpecific3 : 40|8@1+ (1,0) [0|0] "" Vector__XXX
 SG_ ManufacturerSpecific2 : 32|8@1+ (1,0) [0|0] "" Vector__XXX
 SG_ ManufacturerSpecific1 : 24|8@1+ (1,0) [0|0] "" Vector__XXX
 SG_ ErrorRegister : 16|8@1+ (1,0) [0|0] "" Vector__XXX
 SG_ ErrorCode : 0|16@1+ (1,0) [0|0] "" Vector__XXX

BO_ 167 EMCY_039: 8 Vector__XXX
 SG_ ManufacturerSpecific5 : 56|8@1+ (1,0) [0|0] "" Vector__XXX
 SG_ ManufacturerSpecific4 : 48|8@1+ (1,0) [0|0] "" Vector__XXX
 SG_ ManufacturerSpecific3 : 40|8@1+ (1,0) [0|0] "" Vector__XXX
 SG_ ManufacturerSpecific2 : 32|8@1+ (1,0) [0|0] "" Vector__XXX
 SG_ ManufacturerSpecific1 : 24|8@1+ (1,0) [0|0] "" Vector__XXX
 SG_ ErrorRegister : 16|8@1+ (1,0) [0|0] "" Vector__XXX
 SG_ ErrorCode : 0|16@1+ (1,0) [0|0] "" Vector__XXX

BO_ 166 EMCY_038: 8 Vector__XXX
 SG_ ManufacturerSpecific5 : 56|8@1+ (1,0) [0|0] "" Vector__XXX
 SG_ ManufacturerSpecific4 : 48|8@1+ (1,0) [0|0] "" Vector__XXX
 SG_ ManufacturerSpecific3 : 40|8@1+ (1,0) [0|0] "" Vector__XXX
 SG_ ManufacturerSpecific2 : 32|8@1+ (1,0) [0|0] "" Vector__XXX
 SG_ ManufacturerSpecific1 : 24|8@1+ (1,0) [0|0] "" Vector__XXX
 SG_ ErrorRegister : 16|8@1+ (1,0) [0|0] "" Vector__XXX
 SG_ ErrorCode : 0|16@1+ (1,0) [0|0] "" Vector__XXX

BO_ 165 EMCY_037: 8 Vector__XXX
 SG_ ManufacturerSpecific5 : 56|8@1+ (1,0) [0|0] "" Vector__XXX
 SG_ ManufacturerSpecific4 : 48|8@1+ (1,0) [0|0] "" Vector__XXX
 SG_ ManufacturerSpecific3 : 40|8@1+ (1,0) [0|0] "" Vector__XXX
 SG_ ManufacturerSpecific2 : 32|8@1+ (1,0) [0|0] "" Vector__XXX
 SG_ ManufacturerSpecific1 : 24|8@1+ (1,0) [0|0] "" Vector__XXX
 SG_ ErrorRegister : 16|8@1+ (1,0) [0|0] "" Vector__XXX
 SG_ ErrorCode : 0|16@1+ (1,0) [0|0] "" Vector__XXX

BO_ 164 EMCY_036: 8 Vector__XXX
 SG_ ManufacturerSpecific5 : 56|8@1+ (1,0) [0|0] "" Vector__XXX
 SG_ ManufacturerSpecific4 : 48|8@1+ (1,0) [0|0] "" Vector__XXX
 SG_ ManufacturerSpecific3 : 40|8@1+ (1,0) [0|0] "" Vector__XXX
 SG_ ManufacturerSpecific2 : 32|8@1+ (1,0) [0|0] "" Vector__XXX
 SG_ ManufacturerSpecific1 : 24|8@1+ (1,0) [0|0] "" Vector__XXX
 SG_ ErrorRegister : 16|8@1+ (1,0) [0|0] "" Vector__XXX
 SG_ ErrorCode : 0|16@1+ (1,0) [0|0] "" Vector__XXX

BO_ 163 EMCY_035: 8 Vector__XXX
 SG_ ManufacturerSpecific5 : 56|8@1+ (1,0) [0|0] "" Vector__XXX
 SG_ ManufacturerSpecific4 : 48|8@1+ (1,0) [0|0] "" Vector__XXX
 SG_ ManufacturerSpecific3 : 40|8@1+ (1,0) [0|0] "" Vector__XXX
 SG_ ManufacturerSpecific2 : 32|8@1+ (1,0) [0|0] "" Vector__XXX
 SG_ ManufacturerSpecific1 : 24|8@1+ (1,0) [0|0] "" Vector__XXX
 SG_ ErrorRegister : 16|8@1+ (1,0) [0|0] "" Vector__XXX
 SG_ ErrorCode : 0|16@1+ (1,0) [0|0] "" Vector__XXX

BO_ 162 EMCY_034: 8 Vector__XXX
 SG_ ManufacturerSpecific5 : 56|8@1+ (1,0) [0|0] "" Vector__XXX
 SG_ ManufacturerSpecific4 : 48|8@1+ (1,0) [0|0] "" Vector__XXX
 SG_ ManufacturerSpecific3 : 40|8@1+ (1,0) [0|0] "" Vector__XXX
 SG_ ManufacturerSpecific2 : 32|8@1+ (1,0) [0|0] "" Vector__XXX
 SG_ ManufacturerSpecific1 : 24|8@1+ (1,0) [0|0] "" Vector__XXX
 SG_ ErrorRegister : 16|8@1+ (1,0) [0|0] "" Vector__XXX
 SG_ ErrorCode : 0|16@1+ (1,0) [0|0] "" Vector__XXX

BO_ 161 EMCY_033: 8 Vector__XXX
 SG_ ManufacturerSpecific5 : 56|8@1+ (1,0) [0|0] "" Vector__XXX
 SG_ ManufacturerSpecific4 : 48|8@1+ (1,0) [0|0] "" Vector__XXX
 SG_ ManufacturerSpecific3 : 40|8@1+ (1,0) [0|0] "" Vector__XXX
 SG_ ManufacturerSpecific2 : 32|8@1+ (1,0) [0|0] "" Vector__XXX
 SG_ ManufacturerSpecific1 : 24|8@1+ (1,0) [0|0] "" Vector__XXX
 SG_ ErrorRegister : 16|8@1+ (1,0) [0|0] "" Vector__XXX
 SG_ ErrorCode : 0|16@1+ (1,0) [0|0] "" Vector__XXX

BO_ 160 EMCY_032: 8 Vector__XXX
 SG_ ManufacturerSpecific5 : 56|8@1+ (1,0) [0|0] "" Vector__XXX
 SG_ ManufacturerSpecific4 : 48|8@1+ (1,0) [0|0] "" Vector__XXX
 SG_ ManufacturerSpecific3 : 40|8@1+ (1,0) [0|0] "" Vector__XXX
 SG_ ManufacturerSpecific2 : 32|8@1+ (1,0) [0|0] "" Vector__XXX
 SG_ ManufacturerSpecific1 : 24|8@1+ (1,0) [0|0] "" Vector__XXX
 SG_ ErrorRegister : 16|8@1+ (1,0) [0|0] "" Vector__XXX
 SG_ ErrorCode : 0|16@1+ (1,0) [0|0] "" Vector__XXX

BO_ 159 EMCY_031: 8 Vector__XXX
 SG_ ManufacturerSpecific5 : 56|8@1+ (1,0) [0|0] "" Vector__XXX
 SG_ ManufacturerSpecific4 : 48|8@1+ (1,0) [0|0] "" Vector__XXX
 SG_ ManufacturerSpecific3 : 40|8@1+ (1,0) [0|0] "" Vector__XXX
 SG_ ManufacturerSpecific2 : 32|8@1+ (1,0) [0|0] "" Vector__XXX
 SG_ ManufacturerSpecific1 : 24|8@1+ (1,0) [0|0] "" Vector__XXX
 SG_ ErrorRegister : 16|8@1+ (1,0) [0|0] "" Vector__XXX
 SG_ ErrorCode : 0|16@1+ (1,0) [0|0] "" Vector__XXX

BO_ 158 EMCY_030: 8 Vector__XXX
 SG_ ManufacturerSpecific5 : 56|8@1+ (1,0) [0|0] "" Vector__XXX
 SG_ ManufacturerSpecific4 : 48|8@1+ (1,0) [0|0] "" Vector__XXX
 SG_ ManufacturerSpecific3 : 40|8@1+ (1,0) [0|0] "" Vector__XXX
 SG_ ManufacturerSpecific2 : 32|8@1+ (1,0) [0|0] "" Vector__XXX
 SG_ ManufacturerSpecific1 : 24|8@1+ (1,0) [0|0] "" Vector__XXX
 SG_ ErrorRegister : 16|8@1+ (1,0) [0|0] "" Vector__XXX
 SG_ ErrorCode : 0|16@1+ (1,0) [0|0] "" Vector__XXX

BO_ 157 EMCY_029: 8 Vector__XXX
 SG_ ManufacturerSpecific5 : 56|8@1+ (1,0) [0|0] "" Vector__XXX
 SG_ ManufacturerSpecific4 : 48|8@1+ (1,0) [0|0] "" Vector__XXX
 SG_ ManufacturerSpecific3 : 40|8@1+ (1,0) [0|0] "" Vector__XXX
 SG_ ManufacturerSpecific2 : 32|8@1+ (1,0) [0|0] "" Vector__XXX
 SG_ ManufacturerSpecific1 : 24|8@1+ (1,0) [0|0] "" Vector__XXX
 SG_ ErrorRegister : 16|8@1+ (1,0) [0|0] "" Vector__XXX
 SG_ ErrorCode : 0|16@1+ (1,0) [0|0] "" Vector__XXX

BO_ 156 EMCY_028: 8 Vector__XXX
 SG_ ManufacturerSpecific5 : 56|8@1+ (1,0) [0|0] "" Vector__XXX
 SG_ ManufacturerSpecific4 : 48|8@1+ (1,0) [0|0] "" Vector__XXX
 SG_ ManufacturerSpecific3 : 40|8@1+ (1,0) [0|0] "" Vector__XXX
 SG_ ManufacturerSpecific2 : 32|8@1+ (1,0) [0|0] "" Vector__XXX
 SG_ ManufacturerSpecific1 : 24|8@1+ (1,0) [0|0] "" Vector__XXX
 SG_ ErrorRegister : 16|8@1+ (1,0) [0|0] "" Vector__XXX
 SG_ ErrorCode : 0|16@1+ (1,0) [0|0] "" Vector__XXX

BO_ 155 EMCY_027: 8 Vector__XXX
 SG_ ManufacturerSpecific5 : 56|8@1+ (1,0) [0|0] "" Vector__XXX
 SG_ ManufacturerSpecific4 : 48|8@1+ (1,0) [0|0] "" Vector__XXX
 SG_ ManufacturerSpecific3 : 40|8@1+ (1,0) [0|0] "" Vector__XXX
 SG_ ManufacturerSpecific2 : 32|8@1+ (1,0) [0|0] "" Vector__XXX
 SG_ ManufacturerSpecific1 : 24|8@1+ (1,0) [0|0] "" Vector__XXX
 SG_ ErrorRegister : 16|8@1+ (1,0) [0|0] "" Vector__XXX
 SG_ ErrorCode : 0|16@1+ (1,0) [0|0] "" Vector__XXX

BO_ 154 EMCY_026: 8 Vector__XXX
 SG_ ManufacturerSpecific5 : 56|8@1+ (1,0) [0|0] "" Vector__XXX
 SG_ ManufacturerSpecific4 : 48|8@1+ (1,0) [0|0] "" Vector__XXX
 SG_ ManufacturerSpecific3 : 40|8@1+ (1,0) [0|0] "" Vector__XXX
 SG_ ManufacturerSpecific2 : 32|8@1+ (1,0) [0|0] "" Vector__XXX
 SG_ ManufacturerSpecific1 : 24|8@1+ (1,0) [0|0] "" Vector__XXX
 SG_ ErrorRegister : 16|8@1+ (1,0) [0|0] "" Vector__XXX
 SG_ ErrorCode : 0|16@1+ (1,0) [0|0] "" Vector__XXX

BO_ 153 EMCY_025: 8 Vector__XXX
 SG_ ManufacturerSpecific5 : 56|8@1+ (1,0) [0|0] "" Vector__XXX
 SG_ ManufacturerSpecific4 : 48|8@1+ (1,0) [0|0] "" Vector__XXX
 SG_ ManufacturerSpecific3 : 40|8@1+ (1,0) [0|0] "" Vector__XXX
 SG_ ManufacturerSpecific2 : 32|8@1+ (1,0) [0|0] "" Vector__XXX
 SG_ ManufacturerSpecific1 : 24|8@1+ (1,0) [0|0] "" Vector__XXX
 SG_ ErrorRegister : 16|8@1+ (1,0) [0|0] "" Vector__XXX
 SG_ ErrorCode : 0|16@1+ (1,0) [0|0] "" Vector__XXX

BO_ 152 EMCY_024: 8 Vector__XXX
 SG_ ManufacturerSpecific5 : 56|8@1+ (1,0) [0|0] "" Vector__XXX
 SG_ ManufacturerSpecific4 : 48|8@1+ (1,0) [0|0] "" Vector__XXX
 SG_ ManufacturerSpecific3 : 40|8@1+ (1,0) [0|0] "" Vector__XXX
 SG_ ManufacturerSpecific2 : 32|8@1+ (1,0) [0|0] "" Vector__XXX
 SG_ ManufacturerSpecific1 : 24|8@1+ (1,0) [0|0] "" Vector__XXX
 SG_ ErrorRegister : 16|8@1+ (1,0) [0|0] "" Vector__XXX
 SG_ ErrorCode : 0|16@1+ (1,0) [0|0] "" Vector__XXX

BO_ 151 EMCY_023: 8 Vector__XXX
 SG_ ManufacturerSpecific5 : 56|8@1+ (1,0) [0|0] "" Vector__XXX
 SG_ ManufacturerSpecific4 : 48|8@1+ (1,0) [0|0] "" Vector__XXX
 SG_ ManufacturerSpecific3 : 40|8@1+ (1,0) [0|0] "" Vector__XXX
 SG_ ManufacturerSpecific2 : 32|8@1+ (1,0) [0|0] "" Vector__XXX
 SG_ ManufacturerSpecific1 : 24|8@1+ (1,0) [0|0] "" Vector__XXX
 SG_ ErrorRegister : 16|8@1+ (1,0) [0|0] "" Vector__XXX
 SG_ ErrorCode : 0|16@1+ (1,0) [0|0] "" Vector__XXX

BO_ 150 EMCY_022: 8 Vector__XXX
 SG_ ManufacturerSpecific5 : 56|8@1+ (1,0) [0|0] "" Vector__XXX
 SG_ ManufacturerSpecific4 : 48|8@1+ (1,0) [0|0] "" Vector__XXX
 SG_ ManufacturerSpecific3 : 40|8@1+ (1,0) [0|0] "" Vector__XXX
 SG_ ManufacturerSpecific2 : 32|8@1+ (1,0) [0|0] "" Vector__XXX
 SG_ ManufacturerSpecific1 : 24|8@1+ (1,0) [0|0] "" Vector__XXX
 SG_ ErrorRegister : 16|8@1+ (1,0) [0|0] "" Vector__XXX
 SG_ ErrorCode : 0|16@1+ (1,0) [0|0] "" Vector__XXX

BO_ 149 EMCY_021: 8 Vector__XXX
 SG_ ManufacturerSpecific5 : 56|8@1+ (1,0) [0|0] "" Vector__XXX
 SG_ ManufacturerSpecific4 : 48|8@1+ (1,0) [0|0] "" Vector__XXX
 SG_ ManufacturerSpecific3 : 40|8@1+ (1,0) [0|0] "" Vector__XXX
 SG_ ManufacturerSpecific2 : 32|8@1+ (1,0) [0|0] "" Vector__XXX
 SG_ ManufacturerSpecific1 : 24|8@1+ (1,0) [0|0] "" Vector__XXX
 SG_ ErrorRegister : 16|8@1+ (1,0) [0|0] "" Vector__XXX
 SG_ ErrorCode : 0|16@1+ (1,0) [0|0] "" Vector__XXX

BO_ 148 EMCY_020: 8 Vector__XXX
 SG_ ManufacturerSpecific5 : 56|8@1+ (1,0) [0|0] "" Vector__XXX
 SG_ ManufacturerSpecific4 : 48|8@1+ (1,0) [0|0] "" Vector__XXX
 SG_ ManufacturerSpecific3 : 40|8@1+ (1,0) [0|0] "" Vector__XXX
 SG_ ManufacturerSpecific2 : 32|8@1+ (1,0) [0|0] "" Vector__XXX
 SG_ ManufacturerSpecific1 : 24|8@1+ (1,0) [0|0] "" Vector__XXX
 SG_ ErrorRegister : 16|8@1+ (1,0) [0|0] "" Vector__XXX
 SG_ ErrorCode : 0|16@1+ (1,0) [0|0] "" Vector__XXX

BO_ 147 EMCY_019: 8 Vector__XXX
 SG_ ManufacturerSpecific5 : 56|8@1+ (1,0) [0|0] "" Vector__XXX
 SG_ ManufacturerSpecific4 : 48|8@1+ (1,0) [0|0] "" Vector__XXX
 SG_ ManufacturerSpecific3 : 40|8@1+ (1,0) [0|0] "" Vector__XXX
 SG_ ManufacturerSpecific2 : 32|8@1+ (1,0) [0|0] "" Vector__XXX
 SG_ ManufacturerSpecific1 : 24|8@1+ (1,0) [0|0] "" Vector__XXX
 SG_ ErrorRegister : 16|8@1+ (1,0) [0|0] "" Vector__XXX
 SG_ ErrorCode : 0|16@1+ (1,0) [0|0] "" Vector__XXX

BO_ 146 EMCY_018: 8 Vector__XXX
 SG_ ManufacturerSpecific5 : 56|8@1+ (1,0) [0|0] "" Vector__XXX
 SG_ ManufacturerSpecific4 : 48|8@1+ (1,0) [0|0] "" Vector__XXX
 SG_ ManufacturerSpecific3 : 40|8@1+ (1,0) [0|0] "" Vector__XXX
 SG_ ManufacturerSpecific2 : 32|8@1+ (1,0) [0|0] "" Vector__XXX
 SG_ ManufacturerSpecific1 : 24|8@1+ (1,0) [0|0] "" Vector__XXX
 SG_ ErrorRegister : 16|8@1+ (1,0) [0|0] "" Vector__XXX
 SG_ ErrorCode : 0|16@1+ (1,0) [0|0] "" Vector__XXX

BO_ 145 EMCY_017: 8 Vector__XXX
 SG_ ManufacturerSpecific5 : 56|8@1+ (1,0) [0|0] "" Vector__XXX
 SG_ ManufacturerSpecific4 : 48|8@1+ (1,0) [0|0] "" Vector__XXX
 SG_ ManufacturerSpecific3 : 40|8@1+ (1,0) [0|0] "" Vector__XXX
 SG_ ManufacturerSpecific2 : 32|8@1+ (1,0) [0|0] "" Vector__XXX
 SG_ ManufacturerSpecific1 : 24|8@1+ (1,0) [0|0] "" Vector__XXX
 SG_ ErrorRegister : 16|8@1+ (1,0) [0|0] "" Vector__XXX
 SG_ ErrorCode : 0|16@1+ (1,0) [0|0] "" Vector__XXX

BO_ 144 EMCY_016: 8 Vector__XXX
 SG_ ManufacturerSpecific5 : 56|8@1+ (1,0) [0|0] "" Vector__XXX
 SG_ ManufacturerSpecific4 : 48|8@1+ (1,0) [0|0] "" Vector__XXX
 SG_ ManufacturerSpecific3 : 40|8@1+ (1,0) [0|0] "" Vector__XXX
 SG_ ManufacturerSpecific2 : 32|8@1+ (1,0) [0|0] "" Vector__XXX
 SG_ ManufacturerSpecific1 : 24|8@1+ (1,0) [0|0] "" Vector__XXX
 SG_ ErrorRegister : 16|8@1+ (1,0) [0|0] "" Vector__XXX
 SG_ ErrorCode : 0|16@1+ (1,0) [0|0] "" Vector__XXX

BO_ 143 EMCY_015: 8 Vector__XXX
 SG_ ManufacturerSpecific5 : 56|8@1+ (1,0) [0|0] "" Vector__XXX
 SG_ ManufacturerSpecific4 : 48|8@1+ (1,0) [0|0] "" Vector__XXX
 SG_ ManufacturerSpecific3 : 40|8@1+ (1,0) [0|0] "" Vector__XXX
 SG_ ManufacturerSpecific2 : 32|8@1+ (1,0) [0|0] "" Vector__XXX
 SG_ ManufacturerSpecific1 : 24|8@1+ (1,0) [0|0] "" Vector__XXX
 SG_ ErrorRegister : 16|8@1+ (1,0) [0|0] "" Vector__XXX
 SG_ ErrorCode : 0|16@1+ (1,0) [0|0] "" Vector__XXX

BO_ 142 EMCY_014: 8 Vector__XXX
 SG_ ManufacturerSpecific5 : 56|8@1+ (1,0) [0|0] "" Vector__XXX
 SG_ ManufacturerSpecific4 : 48|8@1+ (1,0) [0|0] "" Vector__XXX
 SG_ ManufacturerSpecific3 : 40|8@1+ (1,0) [0|0] "" Vector__XXX
 SG_ ManufacturerSpecific2 : 32|8@1+ (1,0) [0|0] "" Vector__XXX
 SG_ ManufacturerSpecific1 : 24|8@1+ (1,0) [0|0] "" Vector__XXX
 SG_ ErrorRegister : 16|8@1+ (1,0) [0|0] "" Vector__XXX
 SG_ ErrorCode : 0|16@1+ (1,0) [0|0] "" Vector__XXX

BO_ 141 EMCY_013: 8 I_O_Device_3
 SG_ ManufacturerSpecific5 : 56|8@1+ (1,0) [0|0] "" Vector__XXX
 SG_ ManufacturerSpecific4 : 48|8@1+ (1,0) [0|0] "" Vector__XXX
 SG_ ManufacturerSpecific3 : 40|8@1+ (1,0) [0|0] "" Vector__XXX
 SG_ ManufacturerSpecific2 : 32|8@1+ (1,0) [0|0] "" Vector__XXX
 SG_ ManufacturerSpecific1 : 24|8@1+ (1,0) [0|0] "" Vector__XXX
 SG_ ErrorRegister : 16|8@1+ (1,0) [0|0] "" Vector__XXX
 SG_ ErrorCode : 0|16@1+ (1,0) [0|0] "" Vector__XXX

BO_ 140 EMCY_012: 8 I_O_Device_2
 SG_ ManufacturerSpecific5 : 56|8@1+ (1,0) [0|0] "" Vector__XXX
 SG_ ManufacturerSpecific4 : 48|8@1+ (1,0) [0|0] "" Vector__XXX
 SG_ ManufacturerSpecific3 : 40|8@1+ (1,0) [0|0] "" Vector__XXX
 SG_ ManufacturerSpecific2 : 32|8@1+ (1,0) [0|0] "" Vector__XXX
 SG_ ManufacturerSpecific1 : 24|8@1+ (1,0) [0|0] "" Vector__XXX
 SG_ ErrorRegister : 16|8@1+ (1,0) [0|0] "" Vector__XXX
 SG_ ErrorCode : 0|16@1+ (1,0) [0|0] "" Vector__XXX

BO_ 139 EMCY_011: 8 I_O_Device_1
 SG_ ManufacturerSpecific5 : 56|8@1+ (1,0) [0|0] "" Vector__XXX
 SG_ ManufacturerSpecific4 : 48|8@1+ (1,0) [0|0] "" Vector__XXX
 SG_ ManufacturerSpecific3 : 40|8@1+ (1,0) [0|0] "" Vector__XXX
 SG_ ManufacturerSpecific2 : 32|8@1+ (1,0) [0|0] "" Vector__XXX
 SG_ ManufacturerSpecific1 : 24|8@1+ (1,0) [0|0] "" Vector__XXX
 SG_ ErrorRegister : 16|8@1+ (1,0) [0|0] "" Vector__XXX
 SG_ ErrorCode : 0|16@1+ (1,0) [0|0] "" Vector__XXX

BO_ 138 EMCY_010: 8 Vector__XXX
 SG_ ManufacturerSpecific5 : 56|8@1+ (1,0) [0|0] "" Vector__XXX
 SG_ ManufacturerSpecific4 : 48|8@1+ (1,0) [0|0] "" Vector__XXX
 SG_ ManufacturerSpecific3 : 40|8@1+ (1,0) [0|0] "" Vector__XXX
 SG_ ManufacturerSpecific2 : 32|8@1+ (1,0) [0|0] "" Vector__XXX
 SG_ ManufacturerSpecific1 : 24|8@1+ (1,0) [0|0] "" Vector__XXX
 SG_ ErrorRegister : 16|8@1+ (1,0) [0|0] "" Vector__XXX
 SG_ ErrorCode : 0|16@1+ (1,0) [0|0] "" Vector__XXX

BO_ 137 EMCY_009: 8 Vector__XXX
 SG_ ManufacturerSpecific5 : 56|8@1+ (1,0) [0|0] "" Vector__XXX
 SG_ ManufacturerSpecific4 : 48|8@1+ (1,0) [0|0] "" Vector__XXX
 SG_ ManufacturerSpecific3 : 40|8@1+ (1,0) [0|0] "" Vector__XXX
 SG_ ManufacturerSpecific2 : 32|8@1+ (1,0) [0|0] "" Vector__XXX
 SG_ ManufacturerSpecific1 : 24|8@1+ (1,0) [0|0] "" Vector__XXX
 SG_ ErrorRegister : 16|8@1+ (1,0) [0|0] "" Vector__XXX
 SG_ ErrorCode : 0|16@1+ (1,0) [0|0] "" Vector__XXX

BO_ 136 EMCY_008: 8 Vector__XXX
 SG_ ManufacturerSpecific5 : 56|8@1+ (1,0) [0|0] "" Vector__XXX
 SG_ ManufacturerSpecific4 : 48|8@1+ (1,0) [0|0] "" Vector__XXX
 SG_ ManufacturerSpecific3 : 40|8@1+ (1,0) [0|0] "" Vector__XXX
 SG_ ManufacturerSpecific2 : 32|8@1+ (1,0) [0|0] "" Vector__XXX
 SG_ ManufacturerSpecific1 : 24|8@1+ (1,0) [0|0] "" Vector__XXX
 SG_ ErrorRegister : 16|8@1+ (1,0) [0|0] "" Vector__XXX
 SG_ ErrorCode : 0|16@1+ (1,0) [0|0] "" Vector__XXX

BO_ 135 EMCY_007: 8 Vector__XXX
 SG_ ManufacturerSpecific5 : 56|8@1+ (1,0) [0|0] "" Vector__XXX
 SG_ ManufacturerSpecific4 : 48|8@1+ (1,0) [0|0] "" Vector__XXX
 SG_ ManufacturerSpecific3 : 40|8@1+ (1,0) [0|0] "" Vector__XXX
 SG_ ManufacturerSpecific2 : 32|8@1+ (1,0) [0|0] "" Vector__XXX
 SG_ ManufacturerSpecific1 : 24|8@1+ (1,0) [0|0] "" Vector__XXX
 SG_ ErrorRegister : 16|8@1+ (1,0) [0|0] "" Vector__XXX
 SG_ ErrorCode : 0|16@1+ (1,0) [0|0] "" Vector__XXX

BO_ 134 EMCY_006: 8 Vector__XXX
 SG_ ManufacturerSpecific5 : 56|8@1+ (1,0) [0|0] "" Vector__XXX
 SG_ ManufacturerSpecific4 : 48|8@1+ (1,0) [0|0] "" Vector__XXX
 SG_ ManufacturerSpecific3 : 40|8@1+ (1,0) [0|0] "" Vector__XXX
 SG_ ManufacturerSpecific2 : 32|8@1+ (1,0) [0|0] "" Vector__XXX
 SG_ ManufacturerSpecific1 : 24|8@1+ (1,0) [0|0] "" Vector__XXX
 SG_ ErrorRegister : 16|8@1+ (1,0) [0|0] "" Vector__XXX
 SG_ ErrorCode : 0|16@1+ (1,0) [0|0] "" Vector__XXX

BO_ 133 EMCY_005: 8 Vector__XXX
 SG_ ManufacturerSpecific5 : 56|8@1+ (1,0) [0|0] "" Vector__XXX
 SG_ ManufacturerSpecific4 : 48|8@1+ (1,0) [0|0] "" Vector__XXX
 SG_ ManufacturerSpecific3 : 40|8@1+ (1,0) [0|0] "" Vector__XXX
 SG_ ManufacturerSpecific2 : 32|8@1+ (1,0) [0|0] "" Vector__XXX
 SG_ ManufacturerSpecific1 : 24|8@1+ (1,0) [0|0] "" Vector__XXX
 SG_ ErrorRegister : 16|8@1+ (1,0) [0|0] "" Vector__XXX
 SG_ ErrorCode : 0|16@1+ (1,0) [0|0] "" Vector__XXX

BO_ 132 EMCY_004: 8 Vector__XXX
 SG_ ManufacturerSpecific5 : 56|8@1+ (1,0) [0|0] "" Vector__XXX
 SG_ ManufacturerSpecific4 : 48|8@1+ (1,0) [0|0] "" Vector__XXX
 SG_ ManufacturerSpecific3 : 40|8@1+ (1,0) [0|0] "" Vector__XXX
 SG_ ManufacturerSpecific2 : 32|8@1+ (1,0) [0|0] "" Vector__XXX
 SG_ ManufacturerSpecific1 : 24|8@1+ (1,0) [0|0] "" Vector__XXX
 SG_ ErrorRegister : 16|8@1+ (1,0) [0|0] "" Vector__XXX
 SG_ ErrorCode : 0|16@1+ (1,0) [0|0] "" Vector__XXX

BO_ 131 EMCY_003: 8 Vector__XXX
 SG_ ManufacturerSpecific5 : 56|8@1+ (1,0) [0|0] "" Vector__XXX
 SG_ ManufacturerSpecific4 : 48|8@1+ (1,0) [0|0] "" Vector__XXX
 SG_ ManufacturerSpecific3 : 40|8@1+ (1,0) [0|0] "" Vector__XXX
 SG_ ManufacturerSpecific2 : 32|8@1+ (1,0) [0|0] "" Vector__XXX
 SG_ ManufacturerSpecific1 : 24|8@1+ (1,0) [0|0] "" Vector__XXX
 SG_ ErrorRegister : 16|8@1+ (1,0) [0|0] "" Vector__XXX
 SG_ ErrorCode : 0|16@1+ (1,0) [0|0] "" Vector__XXX

BO_ 130 EMCY_002: 8 Vector__XXX
 SG_ ManufacturerSpecific5 : 56|8@1+ (1,0) [0|0] "" Vector__XXX
 SG_ ManufacturerSpecific4 : 48|8@1+ (1,0) [0|0] "" Vector__XXX
 SG_ ManufacturerSpecific3 : 40|8@1+ (1,0) [0|0] "" Vector__XXX
 SG_ ManufacturerSpecific2 : 32|8@1+ (1,0) [0|0] "" Vector__XXX
 SG_ ManufacturerSpecific1 : 24|8@1+ (1,0) [0|0] "" Vector__XXX
 SG_ ErrorRegister : 16|8@1+ (1,0) [0|0] "" Vector__XXX
 SG_ ErrorCode : 0|16@1+ (1,0) [0|0] "" Vector__XXX

BO_ 129 EMCY_001: 8 NMT_Master
 SG_ ManufacturerSpecific5 : 56|8@1+ (1,0) [0|0] "" Vector__XXX
 SG_ ManufacturerSpecific4 : 48|8@1+ (1,0) [0|0] "" Vector__XXX
 SG_ ManufacturerSpecific3 : 40|8@1+ (1,0) [0|0] "" Vector__XXX
 SG_ ManufacturerSpecific2 : 32|8@1+ (1,0) [0|0] "" Vector__XXX
 SG_ ManufacturerSpecific1 : 24|8@1+ (1,0) [0|0] "" Vector__XXX
 SG_ ErrorRegister : 16|8@1+ (1,0) [0|0] "" Vector__XXX
 SG_ ErrorCode : 0|16@1+ (1,0) [0|0] "" Vector__XXX

BO_ 128 SYNC: 0 Vector__XXX

BO_ 0 NMTZeroMsg: 2 NMTMaster
 SG_ Node_ID : 8|8@1+ (1,0) [0|0] "" Vector__XXX
 SG_ CS : 0|8@1+ (1,0) [0|0] "" Vector__XXX

BO_ 768 N11_TPDO0: 8 I_O_Device_1
 SG_ Read_Input_8_Bit8 : 56|8@1+ (1,0) [0|0] ""  I_O_Device_2
 SG_ Read_Input_8_Bit7 : 48|8@1+ (1,0) [0|0] ""  I_O_Device_2
 SG_ Read_Input_8_Bit6 : 40|8@1+ (1,0) [0|0] ""  I_O_Device_2
 SG_ Read_Input_8_Bit5 : 32|8@1+ (1,0) [0|0] ""  I_O_Device_2
 SG_ Read_Input_8_Bit4 : 24|8@1+ (1,0) [0|0] ""  I_O_Device_2
 SG_ Read_Input_8_Bit3 : 16|8@1+ (1,0) [0|0] ""  I_O_Device_2
 SG_ Read_Input_8_Bit2 : 8|8@1+ (1,0) [0|0] ""  I_O_Device_2
 SG_ Read_Input_8_Bit1 : 0|8@1+ (1,0) [0|0] ""  I_O_Device_2

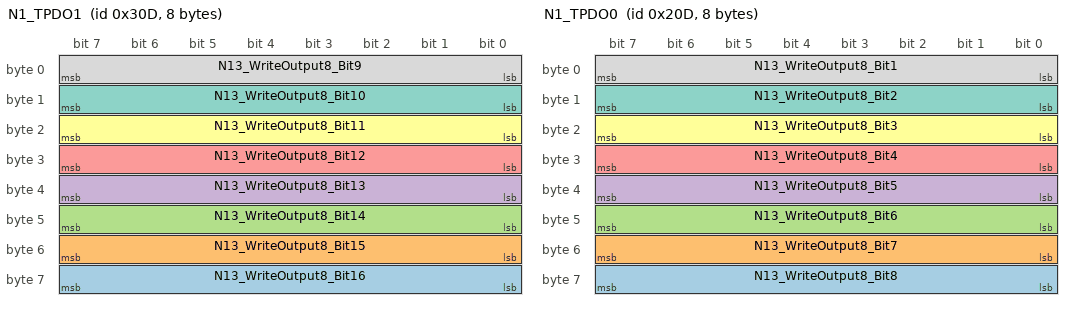
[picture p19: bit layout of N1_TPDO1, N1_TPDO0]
BO_ 781 N1_TPDO1: 8 NMT_Master
 SG_ N13_WriteOutput8_Bit16 : 56|8@1+ (1,0) [0|0] ""  I_O_Device_3
 SG_ N13_WriteOutput8_Bit15 : 48|8@1+ (1,0) [0|0] ""  I_O_Device_3
 SG_ N13_WriteOutput8_Bit14 : 40|8@1+ (1,0) [0|0] ""  I_O_Device_3
 SG_ N13_WriteOutput8_Bit13 : 32|8@1+ (1,0) [0|0] ""  I_O_Device_3
 SG_ N13_WriteOutput8_Bit12 : 24|8@1+ (1,0) [0|0] ""  I_O_Device_3
 SG_ N13_WriteOutput8_Bit11 : 16|8@1+ (1,0) [0|0] ""  I_O_Device_3
 SG_ N13_WriteOutput8_Bit10 : 8|8@1+ (1,0) [0|0] ""  I_O_Device_3
 SG_ N13_WriteOutput8_Bit9 : 0|8@1+ (1,0) [0|0] ""  I_O_Device_3

BO_ 525 N1_TPDO0: 8 NMT_Master
 SG_ N13_WriteOutput8_Bit8 : 56|8@1+ (1,0) [0|0] ""  I_O_Device_3
 SG_ N13_WriteOutput8_Bit7 : 48|8@1+ (1,0) [0|0] ""  I_O_Device_3
 SG_ N13_WriteOutput8_Bit6 : 40|8@1+ (1,0) [0|0] ""  I_O_Device_3
 SG_ N13_WriteOutput8_Bit5 : 32|8@1+ (1,0) [0|0] ""  I_O_Device_3
 SG_ N13_WriteOutput8_Bit4 : 24|8@1+ (1,0) [0|0] ""  I_O_Device_3
 SG_ N13_WriteOutput8_Bit3 : 16|8@1+ (1,0) [0|0] ""  I_O_Device_3
 SG_ N13_WriteOutput8_Bit2 : 8|8@1+ (1,0) [0|0] ""  I_O_Device_3
 SG_ N13_WriteOutput8_Bit1 : 0|8@1+ (1,0) [0|0] ""  I_O_Device_3

EV_ evN1_a040_10: 0 [0|0] "" 0 1 DUMMY_NODE_VECTOR3  NMT_Master;

EV_ evN1_a040_f: 0 [0|0] "" 0 2 DUMMY_NODE_VECTOR3  NMT_Master;

EV_ evN1_a040_e: 0 [0|0] "" 0 3 DUMMY_NODE_VECTOR3  NMT_Master;

EV_ evN1_a040_d: 0 [0|0] "" 0 4 DUMMY_NODE_VECTOR3  NMT_Master;

EV_ evN1_a040_c: 0 [0|0] "" 0 5 DUMMY_NODE_VECTOR3  NMT_Master;

EV_ evN1_a040_b: 0 [0|0] "" 0 6 DUMMY_NODE_VECTOR3  NMT_Master;

EV_ evN1_a040_a: 0 [0|0] "" 0 7 DUMMY_NODE_VECTOR3  NMT_Master;

EV_ evN1_a040_9: 0 [0|0] "" 0 8 DUMMY_NODE_VECTOR3  NMT_Master;

EV_ evN1_a040_8: 0 [0|0] "" 0 9 DUMMY_NODE_VECTOR3  NMT_Master;

EV_ evN1_a040_7: 0 [0|0] "" 0 10 DUMMY_NODE_VECTOR3  NMT_Master;

EV_ evN1_a040_6: 0 [0|0] "" 0 11 DUMMY_NODE_VECTOR3  NMT_Master;

EV_ evN1_a040_5: 0 [0|0] "" 0 12 DUMMY_NODE_VECTOR3  NMT_Master;

EV_ evN1_a040_4: 0 [0|0] "" 0 13 DUMMY_NODE_VECTOR3  NMT_Master;

EV_ evN1_a040_3: 0 [0|0] "" 0 14 DUMMY_NODE_VECTOR3  NMT_Master;

EV_ evN1_a040_2: 0 [0|0] "" 0 15 DUMMY_NODE_VECTOR3  NMT_Master;

EV_ evN1_a040_1: 0 [0|0] "" 0 16 DUMMY_NODE_VECTOR3  NMT_Master;

BA_DEF_ EV_  "AppName" STRING ;
BA_DEF_ BU_  "CO_DCF" STRING ;
BA_DEF_ BU_  "CO_ID" INT 0 127;
BA_DEF_ BU_  "CO_NVSEGMENT0" STRING ;
BA_DEF_ BU_  "CO_NVSEGMENT1" STRING ;
BA_DEF_ BU_  "CO_NVSEGMENT2" STRING ;
BA_DEF_ BU_  "CO_NVSEGMENT3" STRING ;
BA_DEF_ BU_  "CO_NVSEGMENT4" STRING ;
BA_DEF_ BU_  "CO_NVSEGMENT5" STRING ;
BA_DEF_ BU_  "CO_NVSEGMENT6" STRING ;
BA_DEF_ BU_  "CO_NVSEGMENT7" STRING ;
BA_DEF_ BU_  "CO_NVSEGMENT8" STRING ;
BA_DEF_ BU_  "CO_NVSEGMENT9" STRING ;
BA_DEF_ BU_  "CO_NVSEGMENT10" STRING ;
BA_DEF_ BU_  "CO_NVSEGMENT11" STRING ;
BA_DEF_ BU_  "CO_NVSEGMENT12" STRING ;
BA_DEF_ BU_  "CO_NVSEGMENT13" STRING ;
BA_DEF_ BU_  "CO_NVSEGMENT14" STRING ;
BA_DEF_ BU_  "CO_NVSEGMENT15" STRING ;
BA_DEF_ BU_  "CO_NVSEGMENT16" STRING ;
BA_DEF_ BU_  "CO_NVSEGMENT17" STRING ;
BA_DEF_ BU_  "CO_NVSEGMENT18" STRING ;
BA_DEF_ BU_  "CO_NVSEGMENT19" STRING ;
BA_DEF_ BU_  "CO_NVSEGMENT20" STRING ;
BA_DEF_ BU_  "CO_NVSEGMENT21" STRING ;
BA_DEF_ BU_  "CO_NVSEGMENT22" STRING ;
BA_DEF_ BU_  "CO_NVSEGMENT23" STRING ;
BA_DEF_ BU_  "CO_NVSEGMENT24" STRING ;
BA_DEF_ BU_  "CO_NVSEGMENT25" STRING ;
BA_DEF_ BU_  "CO_NVSEGMENT26" STRING ;
BA_DEF_ BU_  "CO_NVSEGMENT27" STRING ;
BA_DEF_ BU_  "CO_NVSEGMENT28" STRING ;
BA_DEF_ BU_  "CO_NVSEGMENT29" STRING ;
BA_DEF_ BU_  "CO_NVSEGMENT30" STRING ;
BA_DEF_ BU_  "CO_NVSEGMENT31" STRING ;
BA_DEF_ BU_  "CO_NVSEGMENT32" STRING ;
BA_DEF_ BU_  "CO_NVSEGMENT33" STRING ;
BA_DEF_ BU_  "CO_NVSEGMENT34" STRING ;
BA_DEF_ BU_  "CO_NVSEGMENT35" STRING ;
BA_DEF_ BU_  "CO_NVSEGMENT36" STRING ;
BA_DEF_ BU_  "CO_NVSEGMENT37" STRING ;
BA_DEF_ BU_  "CO_NVSEGMENT38" STRING ;
BA_DEF_ BU_  "CO_NVSEGMENT39" STRING ;
BA_DEF_ BU_  "CO_NVSEGMENT40" STRING ;
BA_DEF_ BU_  "CO_NVSEGMENT41" STRING ;
BA_DEF_ BU_  "CO_NVSEGMENT42" STRING ;
BA_DEF_ BU_  "CO_NVSEGMENT43" STRING ;
BA_DEF_ BU_  "CO_NVSEGMENT44" STRING ;
BA_DEF_ BU_  "CO_NVSEGMENT45" STRING ;
BA_DEF_  "OptionLoadDCF" INT 0 1;
BA_DEF_  "GeneratedBy" STRING ;
BA_DEF_  "IsCANopen" INT 0 1;
BA_DEF_  "AUTOGENERATION" INT 0 1;
BA_DEF_DEF_  "AppName" "";
BA_DEF_DEF_  "CO_DCF" "";
BA_DEF_DEF_  "CO_ID" 0;
BA_DEF_DEF_  "CO_NVSEGMENT0" "";
BA_DEF_DEF_  "CO_NVSEGMENT1" "";
BA_DEF_DEF_  "CO_NVSEGMENT2" "";
BA_DEF_DEF_  "CO_NVSEGMENT3" "";
BA_DEF_DEF_  "CO_NVSEGMENT4" "";
BA_DEF_DEF_  "CO_NVSEGMENT5" "";
BA_DEF_DEF_  "CO_NVSEGMENT6" "";
BA_DEF_DEF_  "CO_NVSEGMENT7" "";
BA_DEF_DEF_  "CO_NVSEGMENT8" "";
BA_DEF_DEF_  "CO_NVSEGMENT9" "";
BA_DEF_DEF_  "CO_NVSEGMENT10" "";
BA_DEF_DEF_  "CO_NVSEGMENT11" "";
BA_DEF_DEF_  "CO_NVSEGMENT12" "";
BA_DEF_DEF_  "CO_NVSEGMENT13" "";
BA_DEF_DEF_  "CO_NVSEGMENT14" "";
BA_DEF_DEF_  "CO_NVSEGMENT15" "";
BA_DEF_DEF_  "CO_NVSEGMENT16" "";
BA_DEF_DEF_  "CO_NVSEGMENT17" "";
BA_DEF_DEF_  "CO_NVSEGMENT18" "";
BA_DEF_DEF_  "CO_NVSEGMENT19" "";
BA_DEF_DEF_  "CO_NVSEGMENT20" "";
BA_DEF_DEF_  "CO_NVSEGMENT21" "";
BA_DEF_DEF_  "CO_NVSEGMENT22" "";
BA_DEF_DEF_  "CO_NVSEGMENT23" "";
BA_DEF_DEF_  "CO_NVSEGMENT24" "";
BA_DEF_DEF_  "CO_NVSEGMENT25" "";
BA_DEF_DEF_  "CO_NVSEGMENT26" "";
BA_DEF_DEF_  "CO_NVSEGMENT27" "";
BA_DEF_DEF_  "CO_NVSEGMENT28" "";
BA_DEF_DEF_  "CO_NVSEGMENT29" "";
BA_DEF_DEF_  "CO_NVSEGMENT30" "";
BA_DEF_DEF_  "CO_NVSEGMENT31" "";
BA_DEF_DEF_  "CO_NVSEGMENT32" "";
BA_DEF_DEF_  "CO_NVSEGMENT33" "";
BA_DEF_DEF_  "CO_NVSEGMENT34" "";
BA_DEF_DEF_  "CO_NVSEGMENT35" "";
BA_DEF_DEF_  "CO_NVSEGMENT36" "";
BA_DEF_DEF_  "CO_NVSEGMENT37" "";
BA_DEF_DEF_  "CO_NVSEGMENT38" "";
BA_DEF_DEF_  "CO_NVSEGMENT39" "";
BA_DEF_DEF_  "CO_NVSEGMENT40" "";
BA_DEF_DEF_  "CO_NVSEGMENT41" "";
BA_DEF_DEF_  "CO_NVSEGMENT42" "";
BA_DEF_DEF_  "CO_NVSEGMENT43" "";
BA_DEF_DEF_  "CO_NVSEGMENT44" "";
BA_DEF_DEF_  "CO_NVSEGMENT45" "";
BA_DEF_DEF_  "OptionLoadDCF" 0;
BA_DEF_DEF_  "GeneratedBy" "";
BA_DEF_DEF_  "IsCANopen" 0;
BA_DEF_DEF_  "AUTOGENERATION" 0;
BA_ "GeneratedBy" "Vector ProCANopen";
BA_ "IsCANopen" 1;
BA_ "AUTOGENERATION" 1;
BA_ "CO_ID" BU_ I_O_Device_3 13;
BA_ "CO_DCF" BU_ I_O_Device_3 "D013.DCF";
BA_ "CO_ID" BU_ I_O_Device_2 12;
BA_ "CO_DCF" BU_ I_O_Device_2 "D012.DCF";
BA_ "CO_ID" BU_ I_O_Device_1 11;
BA_ "CO_DCF" BU_ I_O_Device_1 "D011.DCF";
BA_ "CO_ID" BU_ NMT_Master 1;
BA_ "CO_DCF" BU_ NMT_Master "D001.DCF";
BA_ "CO_NVSEGMENT0" BU_ NMT_Master "a500,a507,0,1,0,8";
BA_ "CO_NVSEGMENT1" BU_ NMT_Master "a480,a487,0,2,0,0";
BA_ "CO_NVSEGMENT2" BU_ NMT_Master "a4c0,a4c7,0,5,0,0";
BA_ "CO_NVSEGMENT3" BU_ NMT_Master "a540,a547,0,3,0,0";
BA_ "CO_NVSEGMENT4" BU_ NMT_Master "a580,a587,0,6,0,0";
BA_ "CO_NVSEGMENT5" BU_ NMT_Master "a640,a647,0,4,0,0";
BA_ "CO_NVSEGMENT6" BU_ NMT_Master "a680,a687,0,7,0,0";
BA_ "CO_NVSEGMENT7" BU_ NMT_Master "a6c0,a6c7,0,8,0,0";
BA_ "CO_NVSEGMENT8" BU_ NMT_Master "a880,a887,0,21,0,0";
BA_ "CO_NVSEGMENT9" BU_ NMT_Master "a8c0,a8c7,0,27,0,0";
BA_ "CO_NVSEGMENT10" BU_ NMT_Master "a080,a087,1,1,0,8";
BA_ "CO_NVSEGMENT11" BU_ NMT_Master "a000,a007,1,2,0,0";
BA_ "CO_NVSEGMENT12" BU_ NMT_Master "a040,a047,1,5,0,0";
BA_ "CO_NVSEGMENT13" BU_ NMT_Master "a0c0,a0c7,1,3,0,0";
BA_ "CO_NVSEGMENT14" BU_ NMT_Master "a100,a107,1,6,0,0";
BA_ "CO_NVSEGMENT15" BU_ NMT_Master "a1c0,a1c7,1,4,0,0";
BA_ "CO_NVSEGMENT16" BU_ NMT_Master "a200,a207,1,7,0,0";
BA_ "CO_NVSEGMENT17" BU_ NMT_Master "a240,a247,1,8,0,0";
BA_ "CO_NVSEGMENT18" BU_ NMT_Master "a400,a407,1,21,0,0";
BA_ "CO_NVSEGMENT19" BU_ NMT_Master "a440,a447,1,27,0,0";
BA_ "AppName" EV_ evN1_a040_10 "N13_WriteOutput8_Bit16";
BA_ "AppName" EV_ evN1_a040_f "N13_WriteOutput8_Bit15";
BA_ "AppName" EV_ evN1_a040_e "N13_WriteOutput8_Bit14";
BA_ "AppName" EV_ evN1_a040_d "N13_WriteOutput8_Bit13";
BA_ "AppName" EV_ evN1_a040_c "N13_WriteOutput8_Bit12";
BA_ "AppName" EV_ evN1_a040_b "N13_WriteOutput8_Bit11";
BA_ "AppName" EV_ evN1_a040_a "N13_WriteOutput8_Bit10";
BA_ "AppName" EV_ evN1_a040_9 "N13_WriteOutput8_Bit9";
BA_ "AppName" EV_ evN1_a040_8 "N13_WriteOutput8_Bit8";
BA_ "AppName" EV_ evN1_a040_7 "N13_WriteOutput8_Bit7";
BA_ "AppName" EV_ evN1_a040_6 "N13_WriteOutput8_Bit6";
BA_ "AppName" EV_ evN1_a040_5 "N13_WriteOutput8_Bit5";
BA_ "AppName" EV_ evN1_a040_4 "N13_WriteOutput8_Bit4";
BA_ "AppName" EV_ evN1_a040_3 "N13_WriteOutput8_Bit3";
BA_ "AppName" EV_ evN1_a040_2 "N13_WriteOutput8_Bit2";
BA_ "AppName" EV_ evN1_a040_1 "N13_WriteOutput8_Bit1";
VAL_ 1919 State 127 "PreOperational" 5 "Operational" 4 "Stopped" 0 "Bootup" ;
VAL_ 1918 State 127 "PreOperational" 5 "Operational" 4 "Stopped" 0 "Bootup" ;
VAL_ 1917 State 127 "PreOperational" 5 "Operational" 4 "Stopped" 0 "Bootup" ;
VAL_ 1916 State 127 "PreOperational" 5 "Operational" 4 "Stopped" 0 "Bootup" ;
VAL_ 1915 State 127 "PreOperational" 5 "Operational" 4 "Stopped" 0 "Bootup" ;
VAL_ 1914 State 127 "PreOperational" 5 "Operational" 4 "Stopped" 0 "Bootup" ;
VAL_ 1913 State 127 "PreOperational" 5 "Operational" 4 "Stopped" 0 "Bootup" ;
VAL_ 1912 State 127 "PreOperational" 5 "Operational" 4 "Stopped" 0 "Bootup" ;
VAL_ 1911 State 127 "PreOperational" 5 "Operational" 4 "Stopped" 0 "Bootup" ;
VAL_ 1910 State 127 "PreOperational" 5 "Operational" 4 "Stopped" 0 "Bootup" ;
VAL_ 1909 State 127 "PreOperational" 5 "Operational" 4 "Stopped" 0 "Bootup" ;
VAL_ 1908 State 127 "PreOperational" 5 "Operational" 4 "Stopped" 0 "Bootup" ;
VAL_ 1907 State 127 "PreOperational" 5 "Operational" 4 "Stopped" 0 "Bootup" ;
VAL_ 1906 State 127 "PreOperational" 5 "Operational" 4 "Stopped" 0 "Bootup" ;
VAL_ 1905 State 127 "PreOperational" 5 "Operational" 4 "Stopped" 0 "Bootup" ;
VAL_ 1904 State 127 "PreOperational" 5 "Operational" 4 "Stopped" 0 "Bootup" ;
VAL_ 1903 State 127 "PreOperational" 5 "Operational" 4 "Stopped" 0 "Bootup" ;
VAL_ 1902 State 127 "PreOperational" 5 "Operational" 4 "Stopped" 0 "Bootup" ;
VAL_ 1901 State 127 "PreOperational" 5 "Operational" 4 "Stopped" 0 "Bootup" ;
VAL_ 1900 State 127 "PreOperational" 5 "Operational" 4 "Stopped" 0 "Bootup" ;
VAL_ 1899 State 127 "PreOperational" 5 "Operational" 4 "Stopped" 0 "Bootup" ;
VAL_ 1898 State 127 "PreOperational" 5 "Operational" 4 "Stopped" 0 "Bootup" ;
VAL_ 1897 State 127 "PreOperational" 5 "Operational" 4 "Stopped" 0 "Bootup" ;
VAL_ 1896 State 127 "PreOperational" 5 "Operational" 4 "Stopped" 0 "Bootup" ;
VAL_ 1895 State 127 "PreOperational" 5 "Operational" 4 "Stopped" 0 "Bootup" ;
VAL_ 1894 State 127 "PreOperational" 5 "Operational" 4 "Stopped" 0 "Bootup" ;
VAL_ 1893 State 127 "PreOperational" 5 "Operational" 4 "Stopped" 0 "Bootup" ;
VAL_ 1892 State 127 "PreOperational" 5 "Operational" 4 "Stopped" 0 "Bootup" ;
VAL_ 1891 State 127 "PreOperational" 5 "Operational" 4 "Stopped" 0 "Bootup" ;
VAL_ 1890 State 127 "PreOperational" 5 "Operational" 4 "Stopped" 0 "Bootup" ;
VAL_ 1889 State 127 "PreOperational" 5 "Operational" 4 "Stopped" 0 "Bootup" ;
VAL_ 1888 State 127 "PreOperational" 5 "Operational" 4 "Stopped" 0 "Bootup" ;
VAL_ 1887 State 127 "PreOperational" 5 "Operational" 4 "Stopped" 0 "Bootup" ;
VAL_ 1886 State 127 "PreOperational" 5 "Operational" 4 "Stopped" 0 "Bootup" ;
VAL_ 1885 State 127 "PreOperational" 5 "Operational" 4 "Stopped" 0 "Bootup" ;
VAL_ 1884 State 127 "PreOperational" 5 "Operational" 4 "Stopped" 0 "Bootup" ;
VAL_ 1883 State 127 "PreOperational" 5 "Operational" 4 "Stopped" 0 "Bootup" ;
VAL_ 1882 State 127 "PreOperational" 5 "Operational" 4 "Stopped" 0 "Bootup" ;
VAL_ 1881 State 127 "PreOperational" 5 "Operational" 4 "Stopped" 0 "Bootup" ;
VAL_ 1880 State 127 "PreOperational" 5 "Operational" 4 "Stopped" 0 "Bootup" ;
VAL_ 1879 State 127 "PreOperational" 5 "Operational" 4 "Stopped" 0 "Bootup" ;
VAL_ 1878 State 127 "PreOperational" 5 "Operational" 4 "Stopped" 0 "Bootup" ;
VAL_ 1877 State 127 "PreOperational" 5 "Operational" 4 "Stopped" 0 "Bootup" ;
VAL_ 1876 State 127 "PreOperational" 5 "Operational" 4 "Stopped" 0 "Bootup" ;
VAL_ 1875 State 127 "PreOperational" 5 "Operational" 4 "Stopped" 0 "Bootup" ;
VAL_ 1874 State 127 "PreOperational" 5 "Operational" 4 "Stopped" 0 "Bootup" ;
VAL_ 1873 State 127 "PreOperational" 5 "Operational" 4 "Stopped" 0 "Bootup" ;
VAL_ 1872 State 127 "PreOperational" 5 "Operational" 4 "Stopped" 0 "Bootup" ;
VAL_ 1871 State 127 "PreOperational" 5 "Operational" 4 "Stopped" 0 "Bootup" ;
VAL_ 1870 State 127 "PreOperational" 5 "Operational" 4 "Stopped" 0 "Bootup" ;
VAL_ 1869 State 127 "PreOperational" 5 "Operational" 4 "Stopped" 0 "Bootup" ;
VAL_ 1868 State 127 "PreOperational" 5 "Operational" 4 "Stopped" 0 "Bootup" ;
VAL_ 1867 State 127 "PreOperational" 5 "Operational" 4 "Stopped" 0 "Bootup" ;
VAL_ 1866 State 127 "PreOperational" 5 "Operational" 4 "Stopped" 0 "Bootup" ;
VAL_ 1865 State 127 "PreOperational" 5 "Operational" 4 "Stopped" 0 "Bootup" ;
VAL_ 1864 State 127 "PreOperational" 5 "Operational" 4 "Stopped" 0 "Bootup" ;
VAL_ 1863 State 127 "PreOperational" 5 "Operational" 4 "Stopped" 0 "Bootup" ;
VAL_ 1862 State 127 "PreOperational" 5 "Operational" 4 "Stopped" 0 "Bootup" ;
VAL_ 1861 State 127 "PreOperational" 5 "Operational" 4 "Stopped" 0 "Bootup" ;
VAL_ 1860 State 127 "PreOperational" 5 "Operational" 4 "Stopped" 0 "Bootup" ;
VAL_ 1859 State 127 "PreOperational" 5 "Operational" 4 "Stopped" 0 "Bootup" ;
VAL_ 1858 State 127 "PreOperational" 5 "Operational" 4 "Stopped" 0 "Bootup" ;
VAL_ 1857 State 127 "PreOperational" 5 "Operational" 4 "Stopped" 0 "Bootup" ;
VAL_ 1856 State 127 "PreOperational" 5 "Operational" 4 "Stopped" 0 "Bootup" ;
VAL_ 1855 State 127 "PreOperational" 5 "Operational" 4 "Stopped" 0 "Bootup" ;
VAL_ 1854 State 127 "PreOperational" 5 "Operational" 4 "Stopped" 0 "Bootup" ;
VAL_ 1853 State 127 "PreOperational" 5 "Operational" 4 "Stopped" 0 "Bootup" ;
VAL_ 1852 State 127 "PreOperational" 5 "Operational" 4 "Stopped" 0 "Bootup" ;
VAL_ 1851 State 127 "PreOperational" 5 "Operational" 4 "Stopped" 0 "Bootup" ;
VAL_ 1850 State 127 "PreOperational" 5 "Operational" 4 "Stopped" 0 "Bootup" ;
VAL_ 1849 State 127 "PreOperational" 5 "Operational" 4 "Stopped" 0 "Bootup" ;
VAL_ 1848 State 127 "PreOperational" 5 "Operational" 4 "Stopped" 0 "Bootup" ;
VAL_ 1847 State 127 "PreOperational" 5 "Operational" 4 "Stopped" 0 "Bootup" ;
VAL_ 1846 State 127 "PreOperational" 5 "Operational" 4 "Stopped" 0 "Bootup" ;
VAL_ 1845 State 127 "PreOperational" 5 "Operational" 4 "Stopped" 0 "Bootup" ;
VAL_ 1844 State 127 "PreOperational" 5 "Operational" 4 "Stopped" 0 "Bootup" ;
VAL_ 1843 State 127 "PreOperational" 5 "Operational" 4 "Stopped" 0 "Bootup" ;
VAL_ 1842 State 127 "PreOperational" 5 "Operational" 4 "Stopped" 0 "Bootup" ;
VAL_ 1841 State 127 "PreOperational" 5 "Operational" 4 "Stopped" 0 "Bootup" ;
VAL_ 1840 State 127 "PreOperational" 5 "Operational" 4 "Stopped" 0 "Bootup" ;
VAL_ 1839 State 127 "PreOperational" 5 "Operational" 4 "Stopped" 0 "Bootup" ;
VAL_ 1838 State 127 "PreOperational" 5 "Operational" 4 "Stopped" 0 "Bootup" ;
VAL_ 1837 State 127 "PreOperational" 5 "Operational" 4 "Stopped" 0 "Bootup" ;
VAL_ 1836 State 127 "PreOperational" 5 "Operational" 4 "Stopped" 0 "Bootup" ;
VAL_ 1835 State 127 "PreOperational" 5 "Operational" 4 "Stopped" 0 "Bootup" ;
VAL_ 1834 State 127 "PreOperational" 5 "Operational" 4 "Stopped" 0 "Bootup" ;
VAL_ 1833 State 127 "PreOperational" 5 "Operational" 4 "Stopped" 0 "Bootup" ;
VAL_ 1832 State 127 "PreOperational" 5 "Operational" 4 "Stopped" 0 "Bootup" ;
VAL_ 1831 State 127 "PreOperational" 5 "Operational" 4 "Stopped" 0 "Bootup" ;
VAL_ 1830 State 127 "PreOperational" 5 "Operational" 4 "Stopped" 0 "Bootup" ;
VAL_ 1829 State 127 "PreOperational" 5 "Operational" 4 "Stopped" 0 "Bootup" ;
VAL_ 1828 State 127 "PreOperational" 5 "Operational" 4 "Stopped" 0 "Bootup" ;
VAL_ 1827 State 127 "PreOperational" 5 "Operational" 4 "Stopped" 0 "Bootup" ;
VAL_ 1826 State 127 "PreOperational" 5 "Operational" 4 "Stopped" 0 "Bootup" ;
VAL_ 1825 State 127 "PreOperational" 5 "Operational" 4 "Stopped" 0 "Bootup" ;
VAL_ 1824 State 127 "PreOperational" 5 "Operational" 4 "Stopped" 0 "Bootup" ;
VAL_ 1823 State 127 "PreOperational" 5 "Operational" 4 "Stopped" 0 "Bootup" ;
VAL_ 1822 State 127 "PreOperational" 5 "Operational" 4 "Stopped" 0 "Bootup" ;
VAL_ 1821 State 127 "PreOperational" 5 "Operational" 4 "Stopped" 0 "Bootup" ;
VAL_ 1820 State 127 "PreOperational" 5 "Operational" 4 "Stopped" 0 "Bootup" ;
VAL_ 1819 State 127 "PreOperational" 5 "Operational" 4 "Stopped" 0 "Bootup" ;
VAL_ 1818 State 127 "PreOperational" 5 "Operational" 4 "Stopped" 0 "Bootup" ;
VAL_ 1817 State 127 "PreOperational" 5 "Operational" 4 "Stopped" 0 "Bootup" ;
VAL_ 1816 State 127 "PreOperational" 5 "Operational" 4 "Stopped" 0 "Bootup" ;
VAL_ 1815 State 127 "PreOperational" 5 "Operational" 4 "Stopped" 0 "Bootup" ;
VAL_ 1814 State 127 "PreOperational" 5 "Operational" 4 "Stopped" 0 "Bootup" ;
VAL_ 1813 State 127 "PreOperational" 5 "Operational" 4 "Stopped" 0 "Bootup" ;
VAL_ 1812 State 127 "PreOperational" 5 "Operational" 4 "Stopped" 0 "Bootup" ;
VAL_ 1811 State 127 "PreOperational" 5 "Operational" 4 "Stopped" 0 "Bootup" ;
VAL_ 1810 State 127 "PreOperational" 5 "Operational" 4 "Stopped" 0 "Bootup" ;
VAL_ 1809 State 127 "PreOperational" 5 "Operational" 4 "Stopped" 0 "Bootup" ;
VAL_ 1808 State 127 "PreOperational" 5 "Operational" 4 "Stopped" 0 "Bootup" ;
VAL_ 1807 State 127 "PreOperational" 5 "Operational" 4 "Stopped" 0 "Bootup" ;
VAL_ 1806 State 127 "PreOperational" 5 "Operational" 4 "Stopped" 0 "Bootup" ;
VAL_ 1805 State 127 "PreOperational" 5 "Operational" 4 "Stopped" 0 "Bootup" ;
VAL_ 1804 State 127 "PreOperational" 5 "Operational" 4 "Stopped" 0 "Bootup" ;
VAL_ 1803 State 127 "PreOperational" 5 "Operational" 4 "Stopped" 0 "Bootup" ;
VAL_ 1802 State 127 "PreOperational" 5 "Operational" 4 "Stopped" 0 "Bootup" ;
VAL_ 1801 State 127 "PreOperational" 5 "Operational" 4 "Stopped" 0 "Bootup" ;
VAL_ 1800 State 127 "PreOperational" 5 "Operational" 4 "Stopped" 0 "Bootup" ;
VAL_ 1799 State 127 "PreOperational" 5 "Operational" 4 "Stopped" 0 "Bootup" ;
VAL_ 1798 State 127 "PreOperational" 5 "Operational" 4 "Stopped" 0 "Bootup" ;
VAL_ 1797 State 127 "PreOperational" 5 "Operational" 4 "Stopped" 0 "Bootup" ;
VAL_ 1796 State 127 "PreOperational" 5 "Operational" 4 "Stopped" 0 "Bootup" ;
VAL_ 1795 State 127 "PreOperational" 5 "Operational" 4 "Stopped" 0 "Bootup" ;
VAL_ 1794 State 127 "PreOperational" 5 "Operational" 4 "Stopped" 0 "Bootup" ;
VAL_ 1793 State 127 "PreOperational" 5 "Operational" 4 "Stopped" 0 "Bootup" ;
VAL_ 2021 LSS_TableIndex 8 "10" 7 "20" 6 "50" 5 "100" 4 "125" 3 "250" 2 "500" 1 "800" 0 "1000" ;
VAL_ 2021 LSS_TableSelector 0 "Std_CiA_Table" ;
VAL_ 2021 LSS_Mode 1 "Configuration" 0 "Operation" ;
VAL_ 2021 LSS_M_CS 94 "InquireNodeID" 93 "InquireSerial" 92 "InquireRevision" 91 "InquireProduct" 90 "InquireVendor" 23 "StoreConfiguration" 21 "ActivateBitTiming" 19 "ConfigureBitTiming" 17 "ConfigureNodeID" 76 "IdentifyNonConfSlave" 75 "IdentifySerialHigh" 74 "IdentifySerialLow" 73 "IdentifyRevisionHigh" 72 "IdentifyRevisionLow" 71 "IdentifyProduct" 70 "IdentifyVendor" 68 "SwitchModeSelectSerial" 66 "SwitchModeSelectRevision" 65 "SwitchModeSelectProduct" 64 "SwitchModeSelectVendor" 4 "SwitchModeGlobal" ;
VAL_ 2020 LSS_StoreCfg_ErrCode 255 "Impl_spec_error" 2 "Storage_media_access_error" 1 "Not_supported" 0 "Success" ;
VAL_ 2020 LSS_CfgBitTim_ErrCode 255 "Impl_spec_error" 1 "Not_supported" 0 "Success" ;
VAL_ 2020 LSS_CfgNodeID_ErrCode 255 "Impl_spec_error" 1 "NodeID_Out_Of_Range" 0 "Success" ;
VAL_ 2020 LSS_S_CS 94 "InquireNodeID" 93 "InquireSerial" 92 "InquireRevision" 91 "InquireProduct" 90 "InquireVendor" 76 "IdentifyNonConfSlave" 79 "IdentifySlave" 23 "StoreConfiguration" 19 "ConfigureBitTiming" 17 "ConfigureNodeID" 68 "SwitchModeSelectConfirm" ;
VAL_ 0 Node_ID 0 "All" ;
VAL_ 0 CS 130 "Reset Communication" 129 "Reset Node" 128 "Enter Pre-Operational" 2 "Stop" 1 "Start" ;
